VERSION ""

NS_ :

BS_:

BU_: VMCU TECU TACHO RECU_Virt IC3 HPCU EMS EBS DACU CIOM BBM ACM

BO_ 2675897016 TrailerDiagPhysRespMsg_F2_B8_BB1: 8 EBS
 SG_ TrailerDiagPhysResp_F2_B8_ISig_3 : 0|8@1- (1,0) [0|0] ""  VMCU

BO_ 2675897008 TrailerDiagPhysRespMsg_F2_B0_BB1: 8 EBS
 SG_ TrailerDiagPhysResp_F2_B0_ISig_3 : 0|8@1- (1,0) [0|0] ""  VMCU

BO_ 2675897000 TrailerDiagPhysRespMsg_F2_A8_BB1: 8 EBS
 SG_ TrailerDiagPhysResp_F2_A8_ISig_3 : 0|8@1- (1,0) [0|0] ""  VMCU

BO_ 2675886324 TrailerDiagPhysReqMsg_C8_F4_BB1: 8 IC3
 SG_ TrailerDiagPhysReq_C8_F4_ISig_3 : 0|8@1- (1,0) [0|0] ""  EBS

BO_ 2675886322 TrailerDiagPhysReqMsg_C8_F2_BB1: 8 VMCU
 SG_ TrailerDiagPhysReq_C8_F2_ISig_3 : 0|8@1- (1,0) [0|0] ""  EBS

BO_ 2675884276 TrailerDiagPhysReqMsg_C0_F4_BB1: 8 IC3
 SG_ TrailerDiagPhysReq_C0_F4_ISig_3 : 0|8@1- (1,0) [0|0] ""  EBS

BO_ 2675884274 TrailerDiagPhysReqMsg_C0_F2_BB1: 8 VMCU
 SG_ TrailerDiagPhysReq_C0_F2_ISig_3 : 0|8@1- (1,0) [0|0] ""  EBS

BO_ 2675882228 TrailerDiagPhysReqMsg_B8_F4_BB1: 8 IC3
 SG_ TrailerDiagPhysReq_B8_F4_ISig_3 : 0|8@1- (1,0) [0|0] ""  EBS

BO_ 2675882226 TrailerDiagPhysReqMsg_B8_F2_BB1: 8 VMCU
 SG_ TrailerDiagPhysReq_B8_F2_ISig_3 : 0|8@1- (1,0) [0|0] ""  EBS

BO_ 2675880180 TrailerDiagPhysReqMsg_B0_F4_BB1: 8 IC3
 SG_ TrailerDiagPhysReq_B0_F4_ISig_3 : 0|8@1- (1,0) [0|0] ""  EBS

BO_ 2675880178 TrailerDiagPhysReqMsg_B0_F2_BB1: 8 VMCU
 SG_ TrailerDiagPhysReq_B0_F2_ISig_3 : 0|8@1- (1,0) [0|0] ""  EBS

BO_ 2675878132 TrailerDiagPhysReqMsg_A8_F4_BB1: 8 IC3
 SG_ TrailerDiagPhysReq_A8_F4_ISig_3 : 0|8@1- (1,0) [0|0] ""  EBS

BO_ 2675878130 TrailerDiagPhysReqMsg_A8_F2_BB1: 8 VMCU
 SG_ TrailerDiagPhysReq_A8_F2_ISig_3 : 0|8@1- (1,0) [0|0] ""  EBS

BO_ 2675965940 TrailerDiagFuncMsgTGW_BB1: 8 IC3
 SG_ TrailerDiagFuncTGW2_ISig_3 : 0|64@1- (1,0) [0|0] ""  EBS

BO_ 2675965938 TrailerDiagFuncMsgExtTester_BB1: 8 VMCU
 SG_ TrailerDiagFuncExtTester_ISig_3 : 0|64@1- (1,0) [0|0] ""  EBS

BO_ 2671902706 TesterFuncDiagMsg_BB1: 8 VMCU
 SG_ FuncDiagDataTester_ISig_3 : 0|64@1+ (1,0) [0|0] ""  EBS,TACHO,ACM

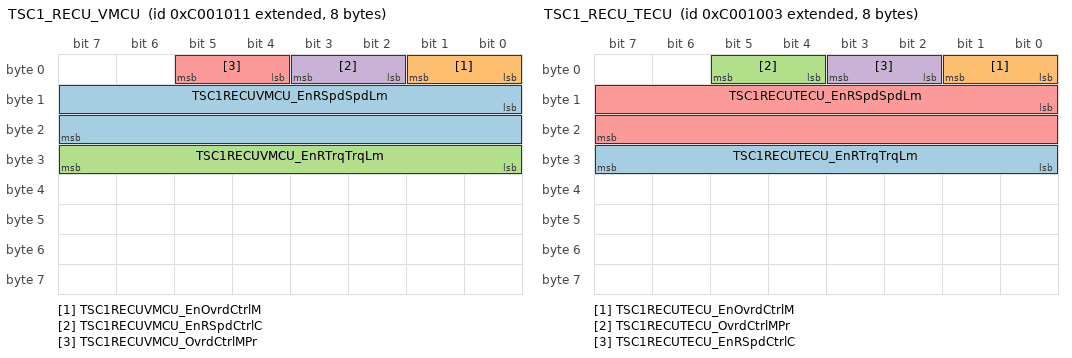
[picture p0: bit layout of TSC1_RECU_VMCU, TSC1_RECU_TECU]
BO_ 2348814353 TSC1_RECU_VMCU: 8 VMCU
 SG_ TSC1RECUVMCU_EnRSpdSpdLm : 8|16@1+ (0.125,0) [0|8191.875] "rpm"  RECU_Virt,EBS
 SG_ TSC1RECUVMCU_EnOvrdCtrlM : 0|2@1+ (1,0) [0|0] ""  EBS,RECU_Virt
 SG_ TSC1RECUVMCU_EnRTrqTrqLm : 24|8@1+ (1,-125) [-125|130] "Percent"  RECU_Virt,EBS
 SG_ TSC1RECUVMCU_EnRSpdCtrlC : 2|2@1+ (1,0) [0|0] ""  RECU_Virt,EBS
 SG_ TSC1RECUVMCU_OvrdCtrlMPr : 4|2@1+ (1,0) [0|0] ""  EBS,RECU_Virt

BO_ 2348814339 TSC1_RECU_TECU: 8 TECU
 SG_ TSC1RECUTECU_EnRTrqTrqLm : 24|8@1+ (1,-125) [-125|130] "Percent"  RECU_Virt
 SG_ TSC1RECUTECU_EnOvrdCtrlM : 0|2@1+ (1,0) [0|0] ""  RECU_Virt
 SG_ TSC1RECUTECU_OvrdCtrlMPr : 4|2@1+ (1,0) [0|0] ""  RECU_Virt
 SG_ TSC1RECUTECU_EnRSpdCtrlC : 2|2@1+ (1,0) [0|0] ""  RECU_Virt
 SG_ TSC1RECUTECU_EnRSpdSpdLm : 8|16@1+ (0.125,0) [0|8191.875] "rpm"  RECU_Virt

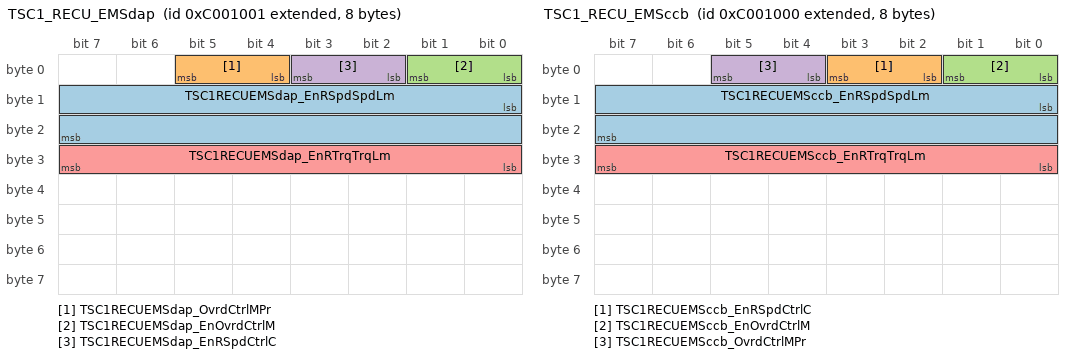
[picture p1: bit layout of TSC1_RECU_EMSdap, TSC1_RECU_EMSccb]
BO_ 2348814337 TSC1_RECU_EMSdap: 8 EMS
 SG_ TSC1RECUEMSdap_EnRSpdSpdLm : 8|16@1+ (0.125,0) [0|8191.875] "rpm"  RECU_Virt
 SG_ TSC1RECUEMSdap_OvrdCtrlMPr : 4|2@1+ (1,0) [0|0] ""  RECU_Virt
 SG_ TSC1RECUEMSdap_EnOvrdCtrlM : 0|2@1+ (1,0) [0|0] ""  RECU_Virt
 SG_ TSC1RECUEMSdap_EnRSpdCtrlC : 2|2@1+ (1,0) [0|0] ""  RECU_Virt
 SG_ TSC1RECUEMSdap_EnRTrqTrqLm : 24|8@1+ (1,-125) [-125|130] "Percent"  RECU_Virt

BO_ 2348814336 TSC1_RECU_EMSccb: 8 EMS
 SG_ TSC1RECUEMSccb_EnRSpdSpdLm : 8|16@1+ (0.125,0) [0|8191.875] "rpm"  RECU_Virt
 SG_ TSC1RECUEMSccb_EnRSpdCtrlC : 2|2@1+ (1,0) [0|0] ""  RECU_Virt
 SG_ TSC1RECUEMSccb_EnOvrdCtrlM : 0|2@1+ (1,0) [0|0] ""  RECU_Virt
 SG_ TSC1RECUEMSccb_OvrdCtrlMPr : 4|2@1+ (1,0) [0|0] ""  RECU_Virt
 SG_ TSC1RECUEMSccb_EnRTrqTrqLm : 24|8@1+ (1,-125) [-125|130] "Percent"  RECU_Virt

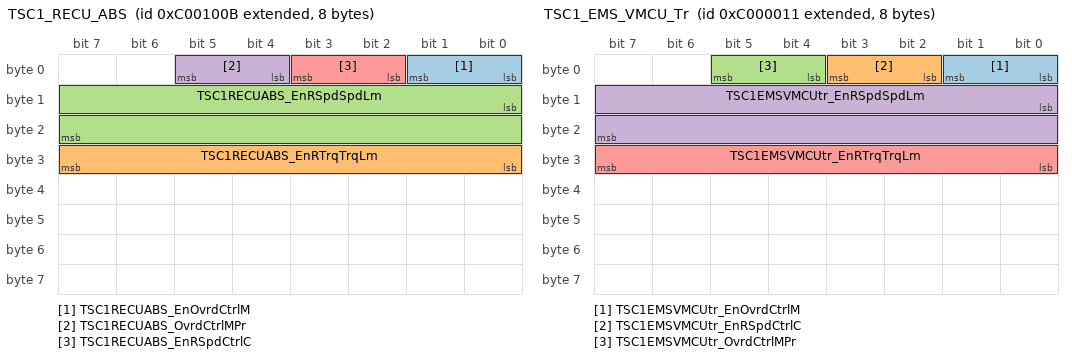
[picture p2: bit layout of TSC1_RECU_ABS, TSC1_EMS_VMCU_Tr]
BO_ 2348814347 TSC1_RECU_ABS: 8 EBS
 SG_ TSC1RECUABS_EnOvrdCtrlM : 0|2@1+ (1,0) [0|0] ""  RECU_Virt
 SG_ TSC1RECUABS_EnRTrqTrqLm : 24|8@1+ (1,-125) [-125|130] "Percent"  RECU_Virt
 SG_ TSC1RECUABS_EnRSpdSpdLm : 8|16@1+ (0.125,0) [0|8191.875] "rpm"  RECU_Virt
 SG_ TSC1RECUABS_OvrdCtrlMPr : 4|2@1+ (1,0) [0|0] ""  RECU_Virt
 SG_ TSC1RECUABS_EnRSpdCtrlC : 2|2@1+ (1,0) [0|0] ""  RECU_Virt

BO_ 2348810257 TSC1_EMS_VMCU_Tr: 8 VMCU
 SG_ TSC1EMSVMCUtr_EnOvrdCtrlM : 0|2@1+ (1,0) [0|0] ""  EMS
 SG_ TSC1EMSVMCUtr_EnRSpdCtrlC : 2|2@1+ (1,0) [0|0] ""  EMS
 SG_ TSC1EMSVMCUtr_OvrdCtrlMPr : 4|2@1+ (1,0) [0|0] ""  EMS
 SG_ TSC1EMSVMCUtr_EnRSpdSpdLm : 8|16@1+ (0.125,0) [0|8191.875] "rpm"  EMS
 SG_ TSC1EMSVMCUtr_EnRTrqTrqLm : 24|8@1+ (1,-125) [-125|130] "Percent"  EMS

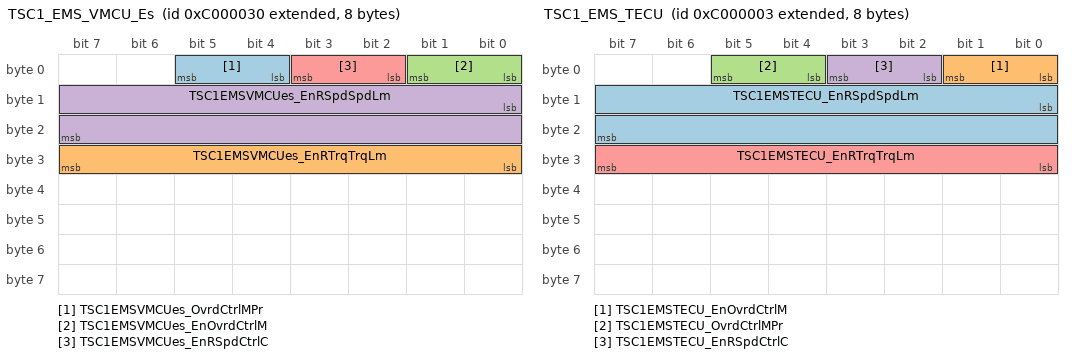
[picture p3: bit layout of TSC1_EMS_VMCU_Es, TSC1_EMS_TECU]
BO_ 2348810288 TSC1_EMS_VMCU_Es: 8 VMCU
 SG_ TSC1EMSVMCUes_OvrdCtrlMPr : 4|2@1+ (1,0) [0|0] ""  EMS,TECU
 SG_ TSC1EMSVMCUes_EnRTrqTrqLm : 24|8@1+ (1,-125) [-125|130] "Percent"  TECU,EMS
 SG_ TSC1EMSVMCUes_EnOvrdCtrlM : 0|2@1+ (1,0) [0|0] ""  TECU,EMS
 SG_ TSC1EMSVMCUes_EnRSpdSpdLm : 8|16@1+ (0.125,0) [0|8191.875] "rpm"  TECU,EMS
 SG_ TSC1EMSVMCUes_EnRSpdCtrlC : 2|2@1+ (1,0) [0|0] ""  EMS,TECU

BO_ 2348810243 TSC1_EMS_TECU: 8 TECU
 SG_ TSC1EMSTECU_EnRSpdSpdLm : 8|16@1+ (0.125,0) [0|8191.875] "rpm"  EMS
 SG_ TSC1EMSTECU_EnOvrdCtrlM : 0|2@1+ (1,0) [0|0] ""  EMS
 SG_ TSC1EMSTECU_OvrdCtrlMPr : 4|2@1+ (1,0) [0|0] ""  EMS
 SG_ TSC1EMSTECU_EnRSpdCtrlC : 2|2@1+ (1,0) [0|0] ""  EMS
 SG_ TSC1EMSTECU_EnRTrqTrqLm : 24|8@1+ (1,-125) [-125|130] "Percent"  EMS

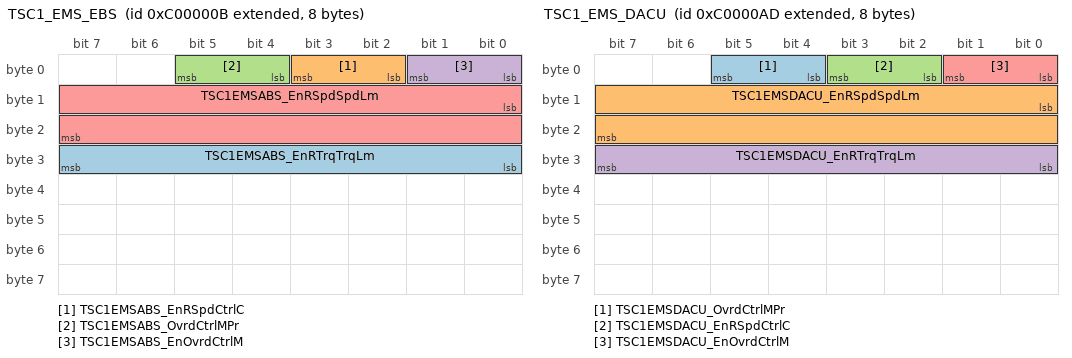
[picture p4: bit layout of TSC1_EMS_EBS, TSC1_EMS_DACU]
BO_ 2348810251 TSC1_EMS_EBS: 8 EBS
 SG_ TSC1EMSABS_EnRTrqTrqLm : 24|8@1+ (1,-125) [-125|130] "Percent"  EMS
 SG_ TSC1EMSABS_EnRSpdCtrlC : 2|2@1+ (1,0) [0|0] ""  EMS
 SG_ TSC1EMSABS_OvrdCtrlMPr : 4|2@1+ (1,0) [0|0] ""  EMS
 SG_ TSC1EMSABS_EnOvrdCtrlM : 0|2@1+ (1,0) [0|0] ""  EMS
 SG_ TSC1EMSABS_EnRSpdSpdLm : 8|16@1+ (0.125,0) [0|8191.875] "rpm"  EMS

BO_ 2348810413 TSC1_EMS_DACU: 8 DACU
 SG_ TSC1EMSDACU_OvrdCtrlMPr : 4|2@1+ (1,0) [0|0] ""  EMS
 SG_ TSC1EMSDACU_EnRSpdSpdLm : 8|16@1+ (0.125,0) [0|8191.875] "rpm"  EMS
 SG_ TSC1EMSDACU_EnRSpdCtrlC : 2|2@1+ (1,0) [0|0] ""  EMS
 SG_ TSC1EMSDACU_EnRTrqTrqLm : 24|8@1+ (1,-125) [-125|130] "Percent"  EMS
 SG_ TSC1EMSDACU_EnOvrdCtrlM : 0|2@1+ (1,0) [0|0] ""  EMS

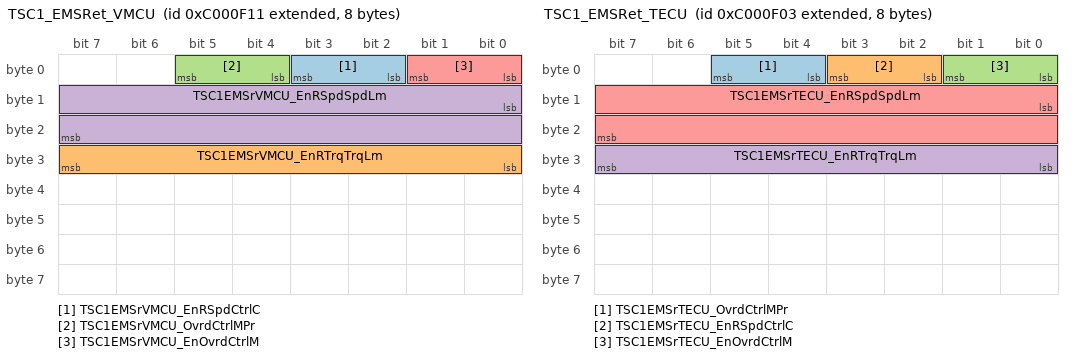
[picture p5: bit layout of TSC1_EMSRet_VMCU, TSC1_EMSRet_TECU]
BO_ 2348814097 TSC1_EMSRet_VMCU: 8 VMCU
 SG_ TSC1EMSrVMCU_EnRSpdCtrlC : 2|2@1+ (1,0) [0|0] ""  EBS,EMS
 SG_ TSC1EMSrVMCU_EnRTrqTrqLm : 24|8@1+ (1,-125) [-125|130] "Percent"  EMS,EBS
 SG_ TSC1EMSrVMCU_OvrdCtrlMPr : 4|2@1+ (1,0) [0|0] ""  EMS,EBS
 SG_ TSC1EMSrVMCU_EnRSpdSpdLm : 8|16@1+ (0.125,0) [0|8191.875] "rpm"  EBS,EMS
 SG_ TSC1EMSrVMCU_EnOvrdCtrlM : 0|2@1+ (1,0) [0|0] ""  EMS,EBS

BO_ 2348814083 TSC1_EMSRet_TECU: 8 TECU
 SG_ TSC1EMSrTECU_OvrdCtrlMPr : 4|2@1+ (1,0) [0|0] ""  EMS
 SG_ TSC1EMSrTECU_EnRSpdCtrlC : 2|2@1+ (1,0) [0|0] ""  EMS
 SG_ TSC1EMSrTECU_EnOvrdCtrlM : 0|2@1+ (1,0) [0|0] ""  EMS
 SG_ TSC1EMSrTECU_EnRTrqTrqLm : 24|8@1+ (1,-125) [-125|130] "Percent"  EMS
 SG_ TSC1EMSrTECU_EnRSpdSpdLm : 8|16@1+ (0.125,0) [0|8191.875] "rpm"  EMS

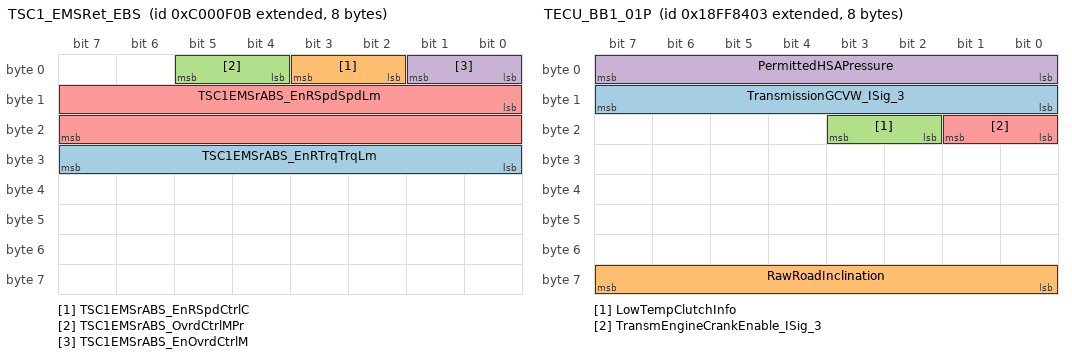
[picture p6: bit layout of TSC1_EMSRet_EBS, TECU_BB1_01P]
BO_ 2348814091 TSC1_EMSRet_EBS: 8 EBS
 SG_ TSC1EMSrABS_EnRTrqTrqLm : 24|8@1+ (1,-125) [-125|130] "Percent"  TECU,EMS
 SG_ TSC1EMSrABS_EnRSpdCtrlC : 2|2@1+ (1,0) [0|0] ""  TECU,EMS
 SG_ TSC1EMSrABS_OvrdCtrlMPr : 4|2@1+ (1,0) [0|0] ""  TECU,EMS
 SG_ TSC1EMSrABS_EnOvrdCtrlM : 0|2@1+ (1,0) [0|0] ""  TECU,EMS
 SG_ TSC1EMSrABS_EnRSpdSpdLm : 8|16@1+ (0.125,0) [0|8191.875] "rpm"  TECU,EMS

BO_ 2566755587 TRF2_X_TCU: 8 Vector__XXX

BO_ 2566846467 TRF1_X_TECU: 8 TECU
 SG_ TransmissionOilTemp_ISig_3 : 32|16@1+ (0.03125,-273) [-273|1774.96875] "DegreeC"  BBM,EMS,IC3
 SG_ TransmissionOilLevel : 8|8@1+ (0.4,0) [0|102] "Percent"  IC3

BO_ 2565603075 TPDT_X_TECU: 8 TECU
 SG_ TPDT_SeqNo_TECU : 0|8@1+ (1,0) [0|0] ""  IC3

BO_ 2565603310 TPDT_X_TACHO: 8 TACHO
 SG_ TPDT_SeqNo_TACHO : 0|8@1+ (1,0) [0|0] ""  IC3,VMCU,CIOM

BO_ 2565603088 TPDT_X_RECU: 8 RECU_Virt
 SG_ TPDT_SeqNo_RECU : 0|8@1+ (1,0) [0|0] ""  DACU,EMS,VMCU,TECU,EBS

BO_ 2565603077 TPDT_X_GSSA: 8 Vector__XXX

BO_ 2565603087 TPDT_X_EMSRet: 8 EMS
 SG_ TPDT_SeqNo_EMSRet : 0|8@1+ (1,0) [0|0] ""  TECU,RECU_Virt,DACU,EBS,IC3,VMCU

BO_ 2565603072 TPDT_X_EMS: 8 EMS
 SG_ TPDT_SeqNo_EMS : 0|8@1+ (1,0) [0|0] ""  TECU,DACU,IC3,VMCU,EBS,CIOM,RECU_Virt

BO_ 2565603083 TPDT_X_EBS: 8 EBS
 SG_ TPDT_SeqNo_EBS : 0|8@1+ (1,0) [0|0] ""  IC3,VMCU

BO_ 2565603133 TPDT_X_ACM: 8 ACM
 SG_ TPDT_SeqNo_ACM : 0|8@1+ (1,0) [0|0] ""  IC3

BO_ 2565598737 TPDT_TACHO_VMCU: 8 VMCU
 SG_ TPDT_SeqNo_TACHO_VMCU : 0|8@1+ (1,0) [0|0] ""  TACHO

BO_ 2565668611 TPCM_X_TECU: 8 TECU
 SG_ TPCM_ControlByte_TECU : 0|8@1+ (1,0) [0|0] ""  IC3

BO_ 2565668846 TPCM_X_TACHO: 8 TACHO
 SG_ TPCM_ControlByte_TACHO : 0|8@1+ (1,0) [0|0] ""  VMCU,CIOM,IC3

BO_ 2565668624 TPCM_X_RECU: 8 RECU_Virt
 SG_ TPCM_ControlByte_RECU : 0|8@1+ (1,0) [0|0] ""  TECU,EMS,VMCU,DACU,EBS

BO_ 2565668613 TPCM_X_GSSA: 8 Vector__XXX

BO_ 2565668623 TPCM_X_EMSRet: 8 EMS
 SG_ TPCM_ControlByte_EMSRet : 0|8@1+ (1,0) [0|0] ""  DACU,IC3,EBS,RECU_Virt,VMCU,TECU

BO_ 2565668608 TPCM_X_EMS: 8 EMS
 SG_ TPCM_ControlByte_EMS : 0|8@1+ (1,0) [0|0] ""  EBS,DACU,CIOM,RECU_Virt,TECU,VMCU,IC3

BO_ 2565668619 TPCM_X_EBS: 8 EBS
 SG_ TPCM_ControlByte_EBS : 0|8@1+ (1,0) [0|0] ""  IC3,VMCU

BO_ 2565668669 TPCM_X_ACM: 8 ACM
 SG_ TPCM_ControlByte_ACM : 0|8@1+ (1,0) [0|0] ""  IC3

BO_ 2565607918 TPCM_VMCU_TACHO: 8 TACHO
 SG_ TPCM_ControlByte_VMCU_TACHO : 0|8@1+ (1,0) [0|0] ""  VMCU

BO_ 2565664273 TPCM_TACHO_VMCU: 8 VMCU
 SG_ TPCM_ControlByte_TACHO_VMCU : 0|8@1+ (1,0) [0|0] ""  TACHO

BO_ 2633844483 TML_X_TCU: 8 Vector__XXX

BO_ 2566882307 TECU_BB1_01P: 8 TECU
 SG_ TransmissionGCVW_ISig_3 : 8|8@1+ (1000,0) [0|255000] "kg"  IC3,EMS,VMCU
 SG_ RawRoadInclination : 56|8@1+ (0.2,-25) [-25|26] "Percent"  VMCU
 SG_ LowTempClutchInfo : 18|2@1+ (1,0) [0|0] ""  IC3
 SG_ PermittedHSAPressure : 0|8@1+ (0.4,0) [0|102] "Percent"  EBS
 SG_ TransmEngineCrankEnable_ISig_3 : 16|2@1+ (1,0) [0|0] ""  VMCU

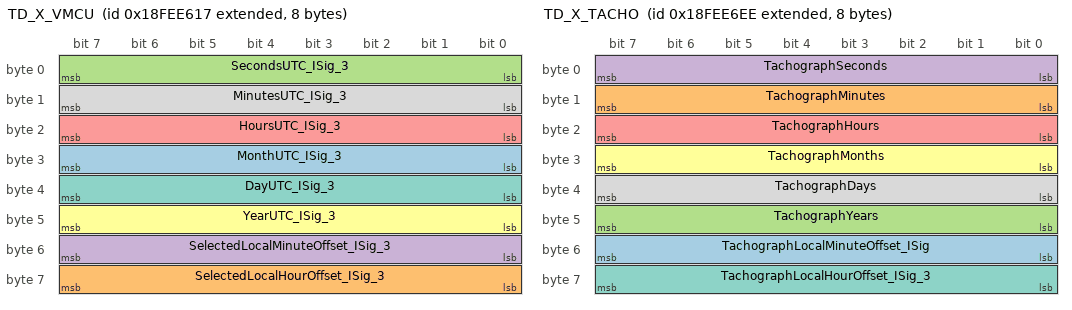
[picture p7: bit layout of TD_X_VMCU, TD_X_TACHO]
BO_ 2566841879 TD_X_VMCU: 8 VMCU
 SG_ MonthUTC_ISig_3 : 24|8@1+ (1,0) [0|255] "Months"  EBS,TECU,ACM,DACU,EMS,BBM,IC3,CIOM
 SG_ SelectedLocalHourOffset_ISig_3 : 56|8@1+ (1,-125) [-125|130] "h"  EBS,IC3
 SG_ SecondsUTC_ISig_3 : 0|8@1+ (0.25,0) [0|63.75] "s"  DACU,TECU,CIOM,IC3,ACM,BBM,EBS,EMS
 SG_ SelectedLocalMinuteOffset_ISig_3 : 48|8@1+ (1,-125) [-125|130] "min"  EBS,IC3
 SG_ HoursUTC_ISig_3 : 16|8@1+ (1,0) [0|255] "h"  EBS,DACU,ACM,BBM,IC3,TECU,CIOM,EMS
 SG_ YearUTC_ISig_3 : 40|8@1+ (1,1985) [1985|2240] "Years"  EBS,EMS,DACU,IC3,ACM,BBM,CIOM,TECU
 SG_ DayUTC_ISig_3 : 32|8@1+ (0.25,0) [0|63.75] "Days"  TECU,CIOM,IC3,EBS,EMS,DACU,ACM,BBM
 SG_ MinutesUTC_ISig_3 : 8|8@1+ (1,0) [0|255] "min"  DACU,TECU,CIOM,ACM,EMS,EBS,BBM,IC3

BO_ 2566842094 TD_X_TACHO: 8 TACHO
 SG_ TachographLocalMinuteOffset_ISig : 48|8@1+ (1,-125) [-125|130] "min"  VMCU,BBM
 SG_ TachographMinutes : 8|8@1+ (1,0) [0|255] "min"  VMCU
 SG_ TachographYears : 40|8@1+ (1,1985) [1985|2240] "Years"  VMCU
 SG_ TachographSeconds : 0|8@1+ (0.25,0) [0|63.75] "s"  VMCU
 SG_ TachographHours : 16|8@1+ (1,0) [0|255] "h"  VMCU
 SG_ TachographMonths : 24|8@1+ (1,0) [0|255] "Months"  VMCU
 SG_ TachographLocalHourOffset_ISig_3 : 56|8@1+ (1,-125) [-125|130] "h"  BBM,VMCU
 SG_ TachographDays : 32|8@1+ (0.25,0) [0|63.75] "Days"  VMCU

BO_ 2564156951 TDA_X_VMCU: 8 VMCU
 SG_ AdjustLocalMinuteOffset : 48|8@1+ (1,-125) [-125|130] "min"  TACHO
 SG_ AdjustLocalHourOffset : 56|8@1+ (1,-125) [-125|130] "h"  TACHO

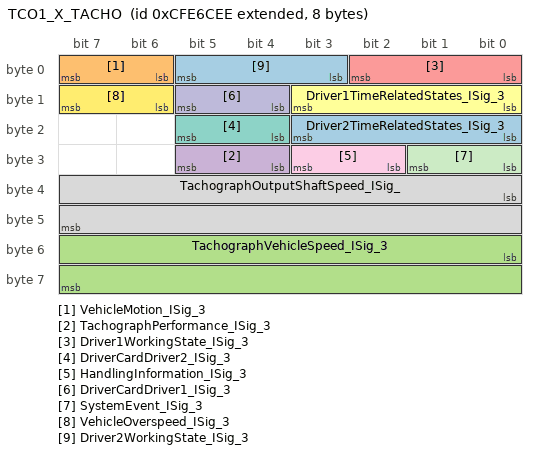
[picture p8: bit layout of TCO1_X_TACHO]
BO_ 2365484270 TCO1_X_TACHO: 8 TACHO
 SG_ Driver2TimeRelatedStates_ISig_3 : 16|4@1+ (1,0) [0|0] ""  BBM,CIOM,IC3
 SG_ VehicleMotion_ISig_3 : 6|2@1+ (1,0) [0|0] ""  IC3,CIOM,BBM
 SG_ TachographVehicleSpeed_ISig_3 : 48|16@1+ (0.00390625,0) [0|255.99609375] "Km_per_h"  CIOM,VMCU,BBM,IC3
 SG_ TachographPerformance_ISig_3 : 28|2@1+ (1,0) [0|0] ""  BBM,CIOM,IC3,VMCU
 SG_ Driver1WorkingState_ISig_3 : 0|3@1+ (1,0) [0|0] ""  BBM,IC3,CIOM
 SG_ Driver1TimeRelatedStates_ISig_3 : 8|4@1+ (1,0) [0|0] ""  CIOM,BBM,IC3
 SG_ DriverCardDriver2_ISig_3 : 20|2@1+ (1,0) [0|0] ""  CIOM,BBM,IC3
 SG_ TachographOutputShaftSpeed_ISig_ : 32|16@1+ (0.125,0) [0|8191.875] "rpm"  VMCU,BBM
 SG_ HandlingInformation_ISig_3 : 26|2@1+ (1,0) [0|0] ""  CIOM,VMCU,IC3,BBM
 SG_ DriverCardDriver1_ISig_3 : 12|2@1+ (1,0) [0|0] ""  CIOM,VMCU,IC3,BBM,DACU
 SG_ SystemEvent_ISig_3 : 24|2@1+ (1,0) [0|0] ""  IC3,BBM,VMCU,CIOM
 SG_ VehicleOverspeed_ISig_3 : 14|2@1+ (1,0) [0|0] ""  CIOM,BBM,IC3
 SG_ Driver2WorkingState_ISig_3 : 3|3@1+ (1,0) [0|0] ""  CIOM,BBM,IC3

BO_ 2566840835 TCFG_X_TCU: 8 Vector__XXX

BO_ 2348876549 TC1_TECU_GSSA: 8 Vector__XXX

BO_ 2566838787 SOFT_X_TCU: 8 Vector__XXX

BO_ 2566838789 SOFT_X_GSSA: 8 Vector__XXX

BO_ 2566862055 Reserved_VDC_BB1: 8 Vector__XXX

BO_ 2566862311 Reserved_CCU_BB1_04P: 8 Vector__XXX

BO_ 2566861799 Reserved_CCU_BB1_03P: 8 Vector__XXX

BO_ 2566861543 Reserved_CCU_BB1_02P: 8 Vector__XXX

BO_ 2566861287 Reserved_CCU_BB1_01P: 8 Vector__XXX

BO_ 2566862567 Reserved_BMS_BB1_01P: 8 Vector__XXX

BO_ 2565537539 RQST_X_TCU: 8 Vector__XXX

BO_ 2565533233 RQST_TACHO_CIOM: 3 CIOM
 SG_ PGNReq_Tacho_CIOM : 0|24@1+ (1,0) [0|16777215] ""  TACHO

BO_ 2565473539 RQST_GSSA_TCU: 8 Vector__XXX

BO_ 2631855639 RESET_TACHO_HMIIOM: 8 IC3

BO_ 2499792656 RECU_BB1_01P: 8 RECU_Virt
 SG_ DrivelineRetarderStat : 0|2@1+ (1,0) [0|0] ""  IC3

BO_ 2566840592 RC_X_RECU: 19 RECU_Virt
 SG_ DrivelineRetarderRefTorque : 128|16@1+ (1,0) [0|65535] "Nm"  EBS,VMCU,DACU,TECU,EMS
 SG_ DrivelineRetarderLocation : 4|4@1+ (1,0) [0|0] ""  EMS,DACU,EBS
 SG_ DrivelineRetarderType : 0|4@1+ (1,0) [0|0] ""  EBS

BO_ 2566840591 RC_X_EMSRet: 19 EMS
 SG_ EngRetConf_RetCtrlMethod : 8|8@1+ (1,0) [0|255] "Step"  TECU
 SG_ EngRetConf_RetSpeedAtP4 : 88|16@1+ (0.125,0) [0|8191.875] "rpm"  TECU
 SG_ EngRetConf_MaxRetSpeedP2 : 40|16@1+ (0.125,0) [0|8191.875] "rpm"  TECU
 SG_ EngRetConf_PerTrqAtP3 : 80|8@1+ (1,-125) [-125|130] "Percent"  TECU
 SG_ EngRetConf_RetSpeedAtP5 : 112|16@1+ (0.125,0) [0|8191.875] "rpm"  TECU
 SG_ EngRetConf_speedAtIdleP1 : 16|16@1+ (0.125,0) [0|8191.875] "rpm"  TECU
 SG_ EngRetConf_PerTrqAtP4 : 104|8@1+ (1,-125) [-125|130] "Percent"  TECU
 SG_ ReferenceEngineRetarderTorque : 128|16@1+ (1,0) [0|65535] "Nm"  VMCU,EBS,DACU,RECU_Virt,TECU
 SG_ EngRetConf_PerTrqAtIdleP1 : 32|8@1+ (1,-125) [-125|130] "Percent"  TECU
 SG_ EngRetConf_RetSpeedAtP3 : 64|16@1+ (0.125,0) [0|8191.875] "rpm"  TECU
 SG_ EngRetConf_PerTrqAtMaxSpeedP2 : 56|8@1+ (1,-125) [-125|130] "Percent"  TECU
 SG_ EngRetConf_PerTrqAtP5 : 144|8@1+ (1,-125) [-125|130] "Percent"  TECU

CM_ BO_ 2348814353 "PGN 0 Torque/Speed Control 1, From VMCU to RECU";
CM_ SG_ 2348814353 TSC1RECUVMCU_EnRSpdSpdLm "65024 - 65279 Error ; 65280 - 65535 Not available";
CM_ SG_ 2348814353 TSC1RECUVMCU_EnRTrqTrqLm "254 Error ; 255 Not available";
CM_ BO_ 2348814339 "PGN 0 Torque/Speed Control 1";
CM_ BO_ 2348814337 "PGN 0 Torque/Speed Control 1";
CM_ SG_ 2348814337 TSC1RECUEMSdap_EnRSpdSpdLm "65024 - 65279 Error ; 65280 - 65535 Not available";
CM_ SG_ 2348814337 TSC1RECUEMSdap_EnRTrqTrqLm "254 Error ; 255 Not available";
CM_ BO_ 2348814336 "PGN 0 Torque/Speed Control 1";
CM_ SG_ 2348814336 TSC1RECUEMSccb_EnRSpdSpdLm "65024 - 65279 Error ; 65280 - 65535 Not available";
CM_ SG_ 2348814336 TSC1RECUEMSccb_EnRTrqTrqLm "254 Error ; 255 Not available";
CM_ BO_ 2348814347 "PGN 0 Torque/Speed Control 1";
CM_ SG_ 2348814347 TSC1RECUABS_EnRTrqTrqLm "254 Error ; 255 Not available";
CM_ SG_ 2348814347 TSC1RECUABS_EnRSpdSpdLm "65024 - 65279 Error ; 65280 - 65535 Not available";
CM_ BO_ 2348810257 "PGN 0 Torque/Speed Control 1, Torque control, From VMCU to EMS";
CM_ SG_ 2348810257 TSC1EMSVMCUtr_EnRSpdSpdLm "65024 - 65279 Error ; 65280 - 65535 Not available";
CM_ SG_ 2348810257 TSC1EMSVMCUtr_EnRTrqTrqLm "254 Error ; 255 Not available";
CM_ BO_ 2348810288 "PGN 0 Torque/Speed Control 1, Engine speed control, From VMCU to EMS";
CM_ SG_ 2348810288 TSC1EMSVMCUes_EnRTrqTrqLm "254 Error ; 255 Not available";
CM_ SG_ 2348810288 TSC1EMSVMCUes_EnRSpdSpdLm "65024 - 65279 Error ; 65280 - 65535 Not available";
CM_ BO_ 2348810243 "PGN 0 Torque/Speed Control 1, From TECU to EMS";
CM_ SG_ 2348810243 TSC1EMSTECU_EnRSpdSpdLm "65024 - 65279 Error ; 65280 - 65535 Not available";
CM_ SG_ 2348810243 TSC1EMSTECU_EnRTrqTrqLm "254 Error ; 255 Not available";
CM_ BO_ 2348810251 "PGN 0 Torque/Speed Control 1, From EBS to EMS";
CM_ SG_ 2348810251 TSC1EMSABS_EnRTrqTrqLm "254 Error ; 255 Not available";
CM_ SG_ 2348810251 TSC1EMSABS_EnRSpdSpdLm "65024 - 65279 Error ; 65280 - 65535 Not available";
CM_ BO_ 2348810413 "PGN 0 Torque/Speed Control 1, From DACU to EMS";
CM_ SG_ 2348810413 TSC1EMSDACU_EnRSpdSpdLm "65024 - 65279 Error ; 65280 - 65535 Not available";
CM_ SG_ 2348810413 TSC1EMSDACU_EnRTrqTrqLm "254 Error ; 255 Not available";
CM_ BO_ 2348814097 "PGN 0 Torque/Speed Control 1, From VMCU to EMS Retarder";
CM_ SG_ 2348814097 TSC1EMSrVMCU_EnRTrqTrqLm "254 Error ; 255 Not available";
CM_ SG_ 2348814097 TSC1EMSrVMCU_EnRSpdSpdLm "65024 - 65279 Error ; 65280 - 65535 Not available";
CM_ BO_ 2348814083 "PGN 0 Torque/Speed Control 1, From TECU to EMS Retarder";
CM_ SG_ 2348814083 TSC1EMSrTECU_EnRTrqTrqLm "254 Error ; 255 Not available";
CM_ SG_ 2348814083 TSC1EMSrTECU_EnRSpdSpdLm "65024 - 65279 Error ; 65280 - 65535 Not available";
CM_ BO_ 2348814091 "PGN 0 Torque/Speed Control 1, From EBS to EMS Retarder";
CM_ SG_ 2348814091 TSC1EMSrABS_EnRTrqTrqLm "254 Error ; 255 Not available";
CM_ SG_ 2348814091 TSC1EMSrABS_EnRSpdSpdLm "65024 - 65279 Error ; 65280 - 65535 Not available";
CM_ BO_ 2566755587 "PGN 64917 Transmission Fluids 2";
CM_ BO_ 2566846467 "PGN 65272 Transmission Fluids 1";
CM_ SG_ 2566846467 TransmissionOilTemp_ISig_3 "65024 - 65279 Error ; 65280 - 65535 Not available";
CM_ BO_ 2565603075 "PGN 60160 Transport Protocol Data Transfer, From TECU";
CM_ BO_ 2565603310 "PGN 60160 Transport Protocol Data Transfer, From TACHO";
CM_ BO_ 2565603088 "PGN 60160 Transport Protocol Data Transfer, From RECU";
CM_ BO_ 2565603077 "PGN 60160 Transport Protocol Data Transfer";
CM_ BO_ 2565603087 "PGN 60160 Transport Protocol Data Transfer, From EMS Retarder";
CM_ BO_ 2565603072 "PGN 60160 Transport Protocol Data Transfer, From EMS";
CM_ BO_ 2565603083 "PGN 60160 Transport Protocol Data Transfer, From EBS";
CM_ BO_ 2565603133 "PGN 60160 Transport Protocol Data Transfer, From ACM";
CM_ BO_ 2565668611 "PGN 60416 Transport Protocol Connection Management, From TECU";
CM_ BO_ 2565668846 "PGN 60416 Transport Protocol Connection Management, From TACHO";
CM_ BO_ 2565668624 "PGN 60416 Transport Protocol Connection Management, From RECU";
CM_ BO_ 2565668613 "PGN 60416 Transport Protocol Connection Management";
CM_ BO_ 2565668623 "PGN 60416 Transport Protocol Connection Management, From EMS Retarder";
CM_ BO_ 2565668608 "PGN 60416 Transport Protocol Connection Management, From EMS";
CM_ BO_ 2565668619 "PGN 60416 Transport Protocol Connection Management, From EBS";
CM_ BO_ 2565668669 "PGN 60416 Transport Protocol Connection Management, From ACM";
CM_ BO_ 2633844483 "PGN64839 Transmission Mode Labels";
CM_ SG_ 2566882307 TransmissionGCVW_ISig_3 "254 Error ; 255 Not available";
CM_ SG_ 2566882307 PermittedHSAPressure "254 Error ; 255 Not available";
CM_ BO_ 2566841879 "PGN 65254 Time/Date, From HMIIOM";
CM_ SG_ 2566841879 MonthUTC_ISig_3 "254 Error ; 255 Not available";
CM_ SG_ 2566841879 SecondsUTC_ISig_3 "254 Error ; 255 Not available";
CM_ SG_ 2566841879 HoursUTC_ISig_3 "254 Error ; 255 Not available";
CM_ SG_ 2566841879 YearUTC_ISig_3 "254 Error ; 255 Not available";
CM_ SG_ 2566841879 DayUTC_ISig_3 "254 Error ; 255 Not available";
CM_ SG_ 2566841879 MinutesUTC_ISig_3 "254 Error ; 255 Not available";
CM_ BO_ 2566842094 "PGN 65254 Time/Date, From TACHO";
CM_ SG_ 2566842094 TachographLocalMinuteOffset_ISig "254 Error ; 255 Not available";
CM_ SG_ 2566842094 TachographMinutes "254 Error ; 255 Not available";
CM_ SG_ 2566842094 TachographYears "254 Error ; 255 Not available";
CM_ SG_ 2566842094 TachographSeconds "254 Error ; 255 Not available";
CM_ SG_ 2566842094 TachographHours "254 Error ; 255 Not available";
CM_ SG_ 2566842094 TachographMonths "254 Error ; 255 Not available";
CM_ SG_ 2566842094 TachographLocalHourOffset_ISig_3 "254 Error ; 255 Not available";
CM_ SG_ 2566842094 TachographDays "254 Error ; 255 Not available";
CM_ BO_ 2564156951 "PGN 54528 TimeDate Adjust";
CM_ SG_ 2564156951 AdjustLocalMinuteOffset "254 Error ; 255 Not available";
CM_ SG_ 2564156951 AdjustLocalHourOffset "254 Error ; 255 Not available";
CM_ BO_ 2365484270 "PGN 65132 Tachograph";
CM_ SG_ 2365484270 TachographVehicleSpeed_ISig_3 "65024 - 65279 Error ; 65280 - 65535 Not available";
CM_ SG_ 2365484270 TachographOutputShaftSpeed_ISig_ "65024 - 65279 Error ; 65280 - 65535 Not available";
CM_ BO_ 2566840835 "PGN 65250 Transmission Configuration";
CM_ BO_ 2348876549 "PGN 256 Transmission Control 1, Gearshift selector to Transmission.
Transmission rate: When active; 50 ms to transmission and axles";
CM_ BO_ 2566838787 "PGN 65242 Software Identification";
CM_ BO_ 2566838789 "PGN 65242 Software Identification";
CM_ BO_ 2566862055 "Reserved ID for EBMR tx100ms";
CM_ BO_ 2566862311 "Reserved ID for EBMR tx100ms";
CM_ BO_ 2566861799 "Reserved ID for EBMR tx100ms";
CM_ BO_ 2566861543 "Reserved ID for EBMR tx100ms";
CM_ BO_ 2566861287 "Reserved ID for EBMR tx250ms +100ms state change";
CM_ BO_ 2566862567 "Reserved ID for EBMR tx1000ms, Note SA may be modified";
CM_ BO_ 2565537539 "PGN59904 Request PGN Global sent by Transmission ECU";
CM_ BO_ 2565533233 "PGN 59904 Request PGN ";
CM_ BO_ 2565473539 "PGN59904 Request PGN to GearShiftSelector sent by Transmission ECU";
CM_ BO_ 2631855639 "PGN 56832 Reset, from HMIIOM to TACHO";
CM_ BO_ 2566840592 "PGN 65249 Retarder Configuration from RECU";
CM_ SG_ 2566840592 DrivelineRetarderRefTorque "65024 - 65279 Error ; 65280 - 65535 Not available";
CM_ BO_ 2566840591 "PGN 65249 Retarder Configuration from EMSRetarder";
CM_ SG_ 2566840591 EngRetConf_RetCtrlMethod "254 Error ; 255 Not available";
CM_ SG_ 2566840591 EngRetConf_RetSpeedAtP4 "65024 - 65279 Error ; 65280 - 65535 Not available";
CM_ SG_ 2566840591 EngRetConf_MaxRetSpeedP2 "65024 - 65279 Error ; 65280 - 65535 Not available";
CM_ SG_ 2566840591 EngRetConf_PerTrqAtP3 "254 Error ; 255 Not available";
CM_ SG_ 2566840591 EngRetConf_RetSpeedAtP5 "65024 - 65279 Error ; 65280 - 65535 Not available";
CM_ SG_ 2566840591 EngRetConf_speedAtIdleP1 "65024 - 65279 Error ; 65280 - 65535 Not available";
CM_ SG_ 2566840591 EngRetConf_PerTrqAtP4 "254 Error ; 255 Not available";
CM_ SG_ 2566840591 ReferenceEngineRetarderTorque "65024 - 65279 Error ; 65280 - 65535 Not available";
CM_ SG_ 2566840591 EngRetConf_PerTrqAtIdleP1 "254 Error ; 255 Not available";
CM_ SG_ 2566840591 EngRetConf_RetSpeedAtP3 "65024 - 65279 Error ; 65280 - 65535 Not available";
CM_ SG_ 2566840591 EngRetConf_PerTrqAtMaxSpeedP2 "254 Error ; 255 Not available";
CM_ SG_ 2566840591 EngRetConf_PerTrqAtP5 "254 Error ; 255 Not available";
BA_DEF_ BO_  "GenMsgStartDelayTime" INT 0 0;
BA_DEF_ BO_  "GenMsgDelayTime" INT 0 0;
BA_DEF_ BO_  "GenMsgNrOfRepetition" INT 0 0;
BA_DEF_ BO_  "GenMsgCycleTimeFast" INT 0 0;
BA_DEF_ BO_  "GenMsgCycleTime" INT 0 0;
BA_DEF_ BO_  "GenMsgSendType" ENUM  "Cyclic","NotUsed","NotUsed","NotUsed","NotUsed","NotUsed","NotUsed","IfActive","NoMsgSendType","NotUsed";
BA_DEF_ SG_  "GenSigStartValue" INT 0 0;
BA_DEF_ SG_  "GenSigCycleTimeActive" INT 0 0;
BA_DEF_ SG_  "GenSigCycleTime" INT 0 0;
BA_DEF_ SG_  "GenSigSendType" ENUM  "Cyclic","OnWrite","OnWriteWithRepetition","OnChange","OnChangeWithRepetition","IfActive","IfActiveWithRepetition","NoSigSendType","NotUsed","NotUsed","NotUsed","NotUsed","NotUsed";
BA_DEF_ BO_  "VFrameFormat" ENUM  "StandardCAN","ExtendedCAN","reserved","J1939PG","reserved","reserved","reserved","reserved","reserved","reserved","reserved","reserved","reserved","reserved","StandardCAN_FD","ExtendedCAN_FD";
BA_DEF_ BO_  "TpJ1939VarDlc" ENUM  "No","Yes";
BA_DEF_ SG_  "SigType" ENUM  "Default","Range","RangeSigned","ASCII","Discrete","Control","ReferencePGN","DTC","StringDelimiter","StringLength","StringLengthControl";
BA_DEF_ SG_  "SeToolVersion_SIGNAL" STRING ;
BA_DEF_ SG_  "SeToolUniqueID_SIGNAL" STRING ;
BA_DEF_ SG_  "SeToolOwnerSigGroup_SIGNAL" STRING ;
BA_DEF_ SG_  "SeToolOwnerSigGroupID_SIGNAL" STRING ;
BA_DEF_ SG_  "SeToolName_SIGNAL" STRING ;
BA_DEF_ SG_  "SeToolItemID_SIGNAL" STRING ;
BA_DEF_ SG_  "SeToolAncestorID_SIGNAL" STRING ;
BA_DEF_ SG_  "SPN" INT 0 524287;
BA_DEF_ SG_  "Platform_VMCU1_Sig" ENUM  "No","Yes";
BA_DEF_ SG_  "Platform_FactoryIf_Sig" ENUM  "No","Yes";
BA_DEF_ SG_  "NeedsUpdateBit" ENUM  "No","Yes";
BA_DEF_ SG_  "GenSigMaxLatency" INT 0 65535;
BA_DEF_ SG_  "GenSigILSupport" ENUM  "Yes","No";
BA_DEF_ BO_  "GenMsgILSupport" ENUM  "No","Yes";
BA_DEF_ BO_  "DiagUUDTResponse" ENUM  "No","Yes";
BA_DEF_ BO_  "DiagState" ENUM  "No","Yes";
BA_DEF_ BO_  "DiagResponse" ENUM  "No","Yes";
BA_DEF_ BO_  "DiagRequest" ENUM  "No","Yes";
BA_DEF_ BO_  "DiagConnection" HEX 0 65535;
BA_DEF_ BO_  "CanTpFcFrameId" HEX 0 2147483647;
BA_DEF_ BO_  "CanTpBs" INT 0 255;
BA_DEF_ SG_  "SystemSignalLongSymbol" STRING ;
BA_DEF_REL_ BU_SG_REL_  "GenSigTimeoutTime" INT 0 65535;
BA_DEF_REL_ BU_SG_REL_  "GenSigFirstTimeoutTime" INT 0 65535;
BA_DEF_DEF_  "GenMsgStartDelayTime" 0;
BA_DEF_DEF_  "GenMsgDelayTime" 0;
BA_DEF_DEF_  "GenMsgNrOfRepetition" 0;
BA_DEF_DEF_  "GenMsgCycleTimeFast" 0;
BA_DEF_DEF_  "GenMsgCycleTime" 0;
BA_DEF_DEF_  "GenMsgSendType" "Cyclic";
BA_DEF_DEF_  "GenSigStartValue" 0;
BA_DEF_DEF_  "GenSigCycleTimeActive" 0;
BA_DEF_DEF_  "GenSigCycleTime" 0;
BA_DEF_DEF_  "GenSigSendType" "Cyclic";
BA_DEF_DEF_  "VFrameFormat" "ExtendedCAN";
BA_DEF_DEF_  "TpJ1939VarDlc" "No";
BA_DEF_DEF_  "SigType" "Default";
BA_DEF_DEF_  "SeToolVersion_SIGNAL" "";
BA_DEF_DEF_  "SeToolUniqueID_SIGNAL" "";
BA_DEF_DEF_  "SeToolOwnerSigGroup_SIGNAL" "";
BA_DEF_DEF_  "SeToolOwnerSigGroupID_SIGNAL" "";
BA_DEF_DEF_  "SeToolName_SIGNAL" "";
BA_DEF_DEF_  "SeToolItemID_SIGNAL" "";
BA_DEF_DEF_  "SeToolAncestorID_SIGNAL" "";
BA_DEF_DEF_  "SPN" 0;
BA_DEF_DEF_  "Platform_VMCU1_Sig" "No";
BA_DEF_DEF_  "Platform_FactoryIf_Sig" "No";
BA_DEF_DEF_  "NeedsUpdateBit" "No";
BA_DEF_DEF_  "GenSigMaxLatency" 0;
BA_DEF_DEF_  "GenSigILSupport" "Yes";
BA_DEF_DEF_  "GenMsgILSupport" "Yes";
BA_DEF_DEF_  "DiagUUDTResponse" "No";
BA_DEF_DEF_  "DiagState" "No";
BA_DEF_DEF_  "DiagResponse" "No";
BA_DEF_DEF_  "DiagRequest" "No";
BA_DEF_DEF_  "DiagConnection" 0;
BA_DEF_DEF_  "CanTpFcFrameId" 2147483647;
BA_DEF_DEF_  "CanTpBs" 255;
BA_DEF_DEF_REL_ "GenSigTimeoutTime" 0;
BA_DEF_DEF_REL_ "GenSigFirstTimeoutTime" 0;
BA_DEF_DEF_  "SystemSignalLongSymbol" "";
BA_ "GenMsgILSupport" BO_ 2675897016 0;
BA_ "GenMsgSendType" BO_ 2675897016 8;
BA_ "VFrameFormat" BO_ 2675897016 3;
BA_ "GenMsgILSupport" BO_ 2675897008 0;
BA_ "GenMsgSendType" BO_ 2675897008 8;
BA_ "VFrameFormat" BO_ 2675897008 3;
BA_ "GenMsgILSupport" BO_ 2675897000 0;
BA_ "GenMsgSendType" BO_ 2675897000 8;
BA_ "VFrameFormat" BO_ 2675897000 3;
BA_ "GenMsgILSupport" BO_ 2675886324 0;
BA_ "GenMsgSendType" BO_ 2675886324 8;
BA_ "VFrameFormat" BO_ 2675886324 3;
BA_ "GenMsgILSupport" BO_ 2675886322 0;
BA_ "GenMsgSendType" BO_ 2675886322 8;
BA_ "VFrameFormat" BO_ 2675886322 3;
BA_ "GenMsgILSupport" BO_ 2675884276 0;
BA_ "GenMsgSendType" BO_ 2675884276 8;
BA_ "VFrameFormat" BO_ 2675884276 3;
BA_ "GenMsgILSupport" BO_ 2675884274 0;
BA_ "GenMsgSendType" BO_ 2675884274 8;
BA_ "VFrameFormat" BO_ 2675884274 3;
BA_ "GenMsgILSupport" BO_ 2675882228 0;
BA_ "GenMsgSendType" BO_ 2675882228 8;
BA_ "VFrameFormat" BO_ 2675882228 3;
BA_ "GenMsgILSupport" BO_ 2675882226 0;
BA_ "GenMsgSendType" BO_ 2675882226 8;
BA_ "VFrameFormat" BO_ 2675882226 3;
BA_ "GenMsgILSupport" BO_ 2675880180 0;
BA_ "GenMsgSendType" BO_ 2675880180 8;
BA_ "VFrameFormat" BO_ 2675880180 3;
BA_ "GenMsgILSupport" BO_ 2675880178 0;
BA_ "GenMsgSendType" BO_ 2675880178 8;
BA_ "VFrameFormat" BO_ 2675880178 3;
BA_ "GenMsgILSupport" BO_ 2675878132 0;
BA_ "GenMsgSendType" BO_ 2675878132 8;
BA_ "VFrameFormat" BO_ 2675878132 3;
BA_ "GenMsgILSupport" BO_ 2675878130 0;
BA_ "GenMsgSendType" BO_ 2675878130 8;
BA_ "VFrameFormat" BO_ 2675878130 3;
BA_ "GenMsgILSupport" BO_ 2675965940 0;
BA_ "GenMsgSendType" BO_ 2675965940 8;
BA_ "VFrameFormat" BO_ 2675965940 3;
BA_ "GenMsgILSupport" BO_ 2675965938 0;
BA_ "GenMsgSendType" BO_ 2675965938 8;
BA_ "VFrameFormat" BO_ 2675965938 3;
BA_ "DiagConnection" BO_ 2671902706 62190;
BA_ "DiagState" BO_ 2671902706 1;
BA_ "GenMsgILSupport" BO_ 2671902706 0;
BA_ "GenMsgSendType" BO_ 2671902706 8;
BA_ "VFrameFormat" BO_ 2671902706 3;
BA_ "GenMsgSendType" BO_ 2348814353 7;
BA_ "GenMsgCycleTimeFast" BO_ 2348814353 50;
BA_ "GenMsgNrOfRepetition" BO_ 2348814353 3;
BA_ "VFrameFormat" BO_ 2348814353 3;
BA_ "GenMsgSendType" BO_ 2348814339 7;
BA_ "GenMsgCycleTimeFast" BO_ 2348814339 50;
BA_ "GenMsgNrOfRepetition" BO_ 2348814339 3;
BA_ "VFrameFormat" BO_ 2348814339 3;
BA_ "GenMsgSendType" BO_ 2348814337 7;
BA_ "GenMsgCycleTimeFast" BO_ 2348814337 50;
BA_ "GenMsgNrOfRepetition" BO_ 2348814337 3;
BA_ "VFrameFormat" BO_ 2348814337 3;
BA_ "GenMsgSendType" BO_ 2348814336 7;
BA_ "GenMsgCycleTimeFast" BO_ 2348814336 50;
BA_ "GenMsgNrOfRepetition" BO_ 2348814336 3;
BA_ "VFrameFormat" BO_ 2348814336 3;
BA_ "GenMsgSendType" BO_ 2348814347 7;
BA_ "GenMsgCycleTimeFast" BO_ 2348814347 50;
BA_ "GenMsgNrOfRepetition" BO_ 2348814347 3;
BA_ "VFrameFormat" BO_ 2348814347 3;
BA_ "GenMsgSendType" BO_ 2348810257 7;
BA_ "GenMsgCycleTimeFast" BO_ 2348810257 20;
BA_ "GenMsgNrOfRepetition" BO_ 2348810257 3;
BA_ "VFrameFormat" BO_ 2348810257 3;
BA_ "GenMsgSendType" BO_ 2348810288 7;
BA_ "GenMsgCycleTimeFast" BO_ 2348810288 20;
BA_ "GenMsgNrOfRepetition" BO_ 2348810288 3;
BA_ "VFrameFormat" BO_ 2348810288 3;
BA_ "GenMsgSendType" BO_ 2348810243 7;
BA_ "GenMsgCycleTimeFast" BO_ 2348810243 10;
BA_ "GenMsgNrOfRepetition" BO_ 2348810243 3;
BA_ "VFrameFormat" BO_ 2348810243 3;
BA_ "GenMsgSendType" BO_ 2348810251 7;
BA_ "GenMsgCycleTimeFast" BO_ 2348810251 10;
BA_ "GenMsgNrOfRepetition" BO_ 2348810251 3;
BA_ "VFrameFormat" BO_ 2348810251 3;
BA_ "GenMsgSendType" BO_ 2348810413 7;
BA_ "GenMsgCycleTimeFast" BO_ 2348810413 20;
BA_ "GenMsgNrOfRepetition" BO_ 2348810413 3;
BA_ "VFrameFormat" BO_ 2348810413 3;
BA_ "GenMsgSendType" BO_ 2348814097 7;
BA_ "GenMsgCycleTimeFast" BO_ 2348814097 50;
BA_ "GenMsgNrOfRepetition" BO_ 2348814097 3;
BA_ "VFrameFormat" BO_ 2348814097 3;
BA_ "GenMsgSendType" BO_ 2348814083 7;
BA_ "GenMsgCycleTimeFast" BO_ 2348814083 50;
BA_ "GenMsgNrOfRepetition" BO_ 2348814083 3;
BA_ "VFrameFormat" BO_ 2348814083 3;
BA_ "GenMsgSendType" BO_ 2348814091 7;
BA_ "GenMsgCycleTimeFast" BO_ 2348814091 50;
BA_ "GenMsgNrOfRepetition" BO_ 2348814091 3;
BA_ "VFrameFormat" BO_ 2348814091 3;
BA_ "VFrameFormat" BO_ 2566755587 3;
BA_ "GenMsgCycleTime" BO_ 2566846467 1000;
BA_ "GenMsgStartDelayTime" BO_ 2566846467 125;
BA_ "VFrameFormat" BO_ 2566846467 3;
BA_ "GenMsgILSupport" BO_ 2565603075 0;
BA_ "GenMsgSendType" BO_ 2565603075 8;
BA_ "VFrameFormat" BO_ 2565603075 3;
BA_ "GenMsgILSupport" BO_ 2565603310 0;
BA_ "GenMsgSendType" BO_ 2565603310 8;
BA_ "VFrameFormat" BO_ 2565603310 3;
BA_ "GenMsgILSupport" BO_ 2565603088 0;
BA_ "GenMsgSendType" BO_ 2565603088 8;
BA_ "VFrameFormat" BO_ 2565603088 3;
BA_ "GenMsgILSupport" BO_ 2565603077 0;
BA_ "VFrameFormat" BO_ 2565603077 3;
BA_ "GenMsgILSupport" BO_ 2565603087 0;
BA_ "GenMsgSendType" BO_ 2565603087 8;
BA_ "VFrameFormat" BO_ 2565603087 3;
BA_ "GenMsgILSupport" BO_ 2565603072 0;
BA_ "GenMsgSendType" BO_ 2565603072 8;
BA_ "VFrameFormat" BO_ 2565603072 3;
BA_ "GenMsgILSupport" BO_ 2565603083 0;
BA_ "GenMsgSendType" BO_ 2565603083 8;
BA_ "VFrameFormat" BO_ 2565603083 3;
BA_ "GenMsgILSupport" BO_ 2565603133 0;
BA_ "GenMsgSendType" BO_ 2565603133 8;
BA_ "VFrameFormat" BO_ 2565603133 3;
BA_ "GenMsgILSupport" BO_ 2565598737 0;
BA_ "GenMsgSendType" BO_ 2565598737 8;
BA_ "VFrameFormat" BO_ 2565598737 3;
BA_ "GenMsgILSupport" BO_ 2565668611 0;
BA_ "GenMsgSendType" BO_ 2565668611 8;
BA_ "VFrameFormat" BO_ 2565668611 3;
BA_ "GenMsgILSupport" BO_ 2565668846 0;
BA_ "GenMsgSendType" BO_ 2565668846 8;
BA_ "VFrameFormat" BO_ 2565668846 3;
BA_ "GenMsgILSupport" BO_ 2565668624 0;
BA_ "GenMsgSendType" BO_ 2565668624 8;
BA_ "VFrameFormat" BO_ 2565668624 3;
BA_ "GenMsgILSupport" BO_ 2565668613 0;
BA_ "VFrameFormat" BO_ 2565668613 3;
BA_ "GenMsgILSupport" BO_ 2565668623 0;
BA_ "GenMsgSendType" BO_ 2565668623 8;
BA_ "VFrameFormat" BO_ 2565668623 3;
BA_ "GenMsgILSupport" BO_ 2565668608 0;
BA_ "GenMsgSendType" BO_ 2565668608 8;
BA_ "VFrameFormat" BO_ 2565668608 3;
BA_ "GenMsgILSupport" BO_ 2565668619 0;
BA_ "GenMsgSendType" BO_ 2565668619 8;
BA_ "VFrameFormat" BO_ 2565668619 3;
BA_ "GenMsgILSupport" BO_ 2565668669 0;
BA_ "GenMsgSendType" BO_ 2565668669 8;
BA_ "VFrameFormat" BO_ 2565668669 3;
BA_ "GenMsgILSupport" BO_ 2565607918 0;
BA_ "GenMsgSendType" BO_ 2565607918 8;
BA_ "VFrameFormat" BO_ 2565607918 3;
BA_ "GenMsgILSupport" BO_ 2565664273 0;
BA_ "GenMsgSendType" BO_ 2565664273 8;
BA_ "VFrameFormat" BO_ 2565664273 3;
BA_ "TpJ1939VarDlc" BO_ 2633844483 1;
BA_ "VFrameFormat" BO_ 2633844483 3;
BA_ "GenMsgCycleTime" BO_ 2566882307 95;
BA_ "GenMsgStartDelayTime" BO_ 2566882307 5;
BA_ "VFrameFormat" BO_ 2566882307 3;
BA_ "GenMsgCycleTime" BO_ 2566841879 250;
BA_ "GenMsgStartDelayTime" BO_ 2566841879 50;
BA_ "VFrameFormat" BO_ 2566841879 3;
BA_ "GenMsgCycleTime" BO_ 2566842094 1000;
BA_ "VFrameFormat" BO_ 2566842094 3;
BA_ "GenMsgSendType" BO_ 2564156951 8;
BA_ "GenMsgDelayTime" BO_ 2564156951 100;
BA_ "VFrameFormat" BO_ 2564156951 3;
BA_ "GenMsgCycleTime" BO_ 2365484270 20;
BA_ "VFrameFormat" BO_ 2365484270 3;
BA_ "TpJ1939VarDlc" BO_ 2566840835 1;
BA_ "VFrameFormat" BO_ 2566840835 3;
BA_ "VFrameFormat" BO_ 2348876549 3;
BA_ "TpJ1939VarDlc" BO_ 2566838787 1;
BA_ "VFrameFormat" BO_ 2566838787 3;
BA_ "TpJ1939VarDlc" BO_ 2566838789 1;
BA_ "VFrameFormat" BO_ 2566838789 3;
BA_ "VFrameFormat" BO_ 2566862055 3;
BA_ "VFrameFormat" BO_ 2566862311 3;
BA_ "VFrameFormat" BO_ 2566861799 3;
BA_ "VFrameFormat" BO_ 2566861543 3;
BA_ "VFrameFormat" BO_ 2566861287 3;
BA_ "VFrameFormat" BO_ 2566862567 3;
BA_ "VFrameFormat" BO_ 2565537539 3;
BA_ "GenMsgCycleTime" BO_ 2565533233 30000;
BA_ "GenMsgStartDelayTime" BO_ 2565533233 25;
BA_ "VFrameFormat" BO_ 2565533233 3;
BA_ "VFrameFormat" BO_ 2565473539 3;
BA_ "GenMsgSendType" BO_ 2631855639 8;
BA_ "GenMsgDelayTime" BO_ 2631855639 200;
BA_ "VFrameFormat" BO_ 2631855639 3;
BA_ "GenMsgCycleTime" BO_ 2499792656 150;
BA_ "GenMsgStartDelayTime" BO_ 2499792656 10;
BA_ "VFrameFormat" BO_ 2499792656 3;
BA_ "GenMsgCycleTime" BO_ 2566840592 5000;
BA_ "GenMsgDelayTime" BO_ 2566840592 350;
BA_ "GenMsgStartDelayTime" BO_ 2566840592 25;
BA_ "VFrameFormat" BO_ 2566840592 3;
BA_ "GenMsgCycleTime" BO_ 2566840591 5000;
BA_ "GenMsgDelayTime" BO_ 2566840591 350;
BA_ "GenMsgStartDelayTime" BO_ 2566840591 1555;
BA_ "VFrameFormat" BO_ 2566840591 3;
BA_ "GenSigSendType" SG_ 2675897016 TrailerDiagPhysResp_F2_B8_ISig_3 7;
BA_ "GenSigSendType" SG_ 2675897008 TrailerDiagPhysResp_F2_B0_ISig_3 7;
BA_ "GenSigSendType" SG_ 2675897000 TrailerDiagPhysResp_F2_A8_ISig_3 7;
BA_ "GenSigSendType" SG_ 2675886324 TrailerDiagPhysReq_C8_F4_ISig_3 7;
BA_ "GenSigSendType" SG_ 2675886322 TrailerDiagPhysReq_C8_F2_ISig_3 7;
BA_ "GenSigSendType" SG_ 2675884276 TrailerDiagPhysReq_C0_F4_ISig_3 7;
BA_ "GenSigSendType" SG_ 2675884274 TrailerDiagPhysReq_C0_F2_ISig_3 7;
BA_ "GenSigSendType" SG_ 2675882228 TrailerDiagPhysReq_B8_F4_ISig_3 7;
BA_ "GenSigSendType" SG_ 2675882226 TrailerDiagPhysReq_B8_F2_ISig_3 7;
BA_ "GenSigSendType" SG_ 2675880180 TrailerDiagPhysReq_B0_F4_ISig_3 7;
BA_ "GenSigSendType" SG_ 2675880178 TrailerDiagPhysReq_B0_F2_ISig_3 7;
BA_ "GenSigSendType" SG_ 2675878132 TrailerDiagPhysReq_A8_F4_ISig_3 7;
BA_ "GenSigSendType" SG_ 2675878130 TrailerDiagPhysReq_A8_F2_ISig_3 7;
BA_ "GenSigSendType" SG_ 2675965940 TrailerDiagFuncTGW2_ISig_3 7;
BA_ "GenSigSendType" SG_ 2675965938 TrailerDiagFuncExtTester_ISig_3 7;
BA_ "GenSigSendType" SG_ 2671902706 FuncDiagDataTester_ISig_3 7;
BA_ "Platform_VMCU1_Sig" SG_ 2671902706 FuncDiagDataTester_ISig_3 1;
BA_ "GenSigSendType" SG_ 2348814353 TSC1RECUVMCU_EnRSpdSpdLm 7;
BA_ "GenSigCycleTime" SG_ 2348814353 TSC1RECUVMCU_EnRSpdSpdLm 100;
BA_ "GenSigCycleTimeActive" SG_ 2348814353 TSC1RECUVMCU_EnRSpdSpdLm 100;
BA_ "GenSigStartValue" SG_ 2348814353 TSC1RECUVMCU_EnRSpdSpdLm 65535;
BA_ "Platform_VMCU1_Sig" SG_ 2348814353 TSC1RECUVMCU_EnRSpdSpdLm 1;
BA_ "SPN" SG_ 2348814353 TSC1RECUVMCU_EnRSpdSpdLm 898;
BA_ "GenSigSendType" SG_ 2348814353 TSC1RECUVMCU_EnOvrdCtrlM 6;
BA_ "Platform_VMCU1_Sig" SG_ 2348814353 TSC1RECUVMCU_EnOvrdCtrlM 1;
BA_ "SPN" SG_ 2348814353 TSC1RECUVMCU_EnOvrdCtrlM 695;
BA_ "GenSigSendType" SG_ 2348814353 TSC1RECUVMCU_EnRTrqTrqLm 7;
BA_ "GenSigCycleTime" SG_ 2348814353 TSC1RECUVMCU_EnRTrqTrqLm 100;
BA_ "GenSigCycleTimeActive" SG_ 2348814353 TSC1RECUVMCU_EnRTrqTrqLm 100;
BA_ "GenSigStartValue" SG_ 2348814353 TSC1RECUVMCU_EnRTrqTrqLm 255;
BA_ "Platform_VMCU1_Sig" SG_ 2348814353 TSC1RECUVMCU_EnRTrqTrqLm 1;
BA_ "SPN" SG_ 2348814353 TSC1RECUVMCU_EnRTrqTrqLm 518;
BA_ "GenSigSendType" SG_ 2348814353 TSC1RECUVMCU_EnRSpdCtrlC 7;
BA_ "GenSigCycleTime" SG_ 2348814353 TSC1RECUVMCU_EnRSpdCtrlC 100;
BA_ "GenSigCycleTimeActive" SG_ 2348814353 TSC1RECUVMCU_EnRSpdCtrlC 100;
BA_ "Platform_VMCU1_Sig" SG_ 2348814353 TSC1RECUVMCU_EnRSpdCtrlC 1;
BA_ "SPN" SG_ 2348814353 TSC1RECUVMCU_EnRSpdCtrlC 696;
BA_ "GenSigSendType" SG_ 2348814353 TSC1RECUVMCU_OvrdCtrlMPr 7;
BA_ "GenSigCycleTime" SG_ 2348814353 TSC1RECUVMCU_OvrdCtrlMPr 100;
BA_ "GenSigCycleTimeActive" SG_ 2348814353 TSC1RECUVMCU_OvrdCtrlMPr 100;
BA_ "GenSigStartValue" SG_ 2348814353 TSC1RECUVMCU_OvrdCtrlMPr 3;
BA_ "Platform_VMCU1_Sig" SG_ 2348814353 TSC1RECUVMCU_OvrdCtrlMPr 1;
BA_ "SPN" SG_ 2348814353 TSC1RECUVMCU_OvrdCtrlMPr 897;
BA_ "GenSigSendType" SG_ 2348814339 TSC1RECUTECU_EnRTrqTrqLm 7;
BA_ "GenSigStartValue" SG_ 2348814339 TSC1RECUTECU_EnRTrqTrqLm 255;
BA_ "Platform_VMCU1_Sig" SG_ 2348814339 TSC1RECUTECU_EnRTrqTrqLm 1;
BA_ "SPN" SG_ 2348814339 TSC1RECUTECU_EnRTrqTrqLm 518;
BA_ "GenSigSendType" SG_ 2348814339 TSC1RECUTECU_EnOvrdCtrlM 6;
BA_ "Platform_VMCU1_Sig" SG_ 2348814339 TSC1RECUTECU_EnOvrdCtrlM 1;
BA_ "SPN" SG_ 2348814339 TSC1RECUTECU_EnOvrdCtrlM 695;
BA_ "GenSigSendType" SG_ 2348814339 TSC1RECUTECU_OvrdCtrlMPr 7;
BA_ "GenSigStartValue" SG_ 2348814339 TSC1RECUTECU_OvrdCtrlMPr 3;
BA_ "Platform_VMCU1_Sig" SG_ 2348814339 TSC1RECUTECU_OvrdCtrlMPr 1;
BA_ "SPN" SG_ 2348814339 TSC1RECUTECU_OvrdCtrlMPr 897;
BA_ "GenSigSendType" SG_ 2348814339 TSC1RECUTECU_EnRSpdCtrlC 7;
BA_ "Platform_VMCU1_Sig" SG_ 2348814339 TSC1RECUTECU_EnRSpdCtrlC 1;
BA_ "SPN" SG_ 2348814339 TSC1RECUTECU_EnRSpdCtrlC 696;
BA_ "GenSigSendType" SG_ 2348814339 TSC1RECUTECU_EnRSpdSpdLm 7;
BA_ "GenSigStartValue" SG_ 2348814339 TSC1RECUTECU_EnRSpdSpdLm 65535;
BA_ "Platform_VMCU1_Sig" SG_ 2348814339 TSC1RECUTECU_EnRSpdSpdLm 1;
BA_ "SPN" SG_ 2348814339 TSC1RECUTECU_EnRSpdSpdLm 898;
BA_ "GenSigSendType" SG_ 2348814337 TSC1RECUEMSdap_EnRSpdSpdLm 7;
BA_ "GenSigCycleTime" SG_ 2348814337 TSC1RECUEMSdap_EnRSpdSpdLm 100;
BA_ "GenSigCycleTimeActive" SG_ 2348814337 TSC1RECUEMSdap_EnRSpdSpdLm 100;
BA_ "GenSigStartValue" SG_ 2348814337 TSC1RECUEMSdap_EnRSpdSpdLm 65535;
BA_ "Platform_VMCU1_Sig" SG_ 2348814337 TSC1RECUEMSdap_EnRSpdSpdLm 1;
BA_ "SPN" SG_ 2348814337 TSC1RECUEMSdap_EnRSpdSpdLm 898;
BA_ "GenSigSendType" SG_ 2348814337 TSC1RECUEMSdap_OvrdCtrlMPr 7;
BA_ "GenSigCycleTime" SG_ 2348814337 TSC1RECUEMSdap_OvrdCtrlMPr 100;
BA_ "GenSigCycleTimeActive" SG_ 2348814337 TSC1RECUEMSdap_OvrdCtrlMPr 100;
BA_ "GenSigStartValue" SG_ 2348814337 TSC1RECUEMSdap_OvrdCtrlMPr 3;
BA_ "Platform_VMCU1_Sig" SG_ 2348814337 TSC1RECUEMSdap_OvrdCtrlMPr 1;
BA_ "SPN" SG_ 2348814337 TSC1RECUEMSdap_OvrdCtrlMPr 897;
BA_ "GenSigSendType" SG_ 2348814337 TSC1RECUEMSdap_EnOvrdCtrlM 6;
BA_ "Platform_VMCU1_Sig" SG_ 2348814337 TSC1RECUEMSdap_EnOvrdCtrlM 1;
BA_ "SPN" SG_ 2348814337 TSC1RECUEMSdap_EnOvrdCtrlM 695;
BA_ "GenSigSendType" SG_ 2348814337 TSC1RECUEMSdap_EnRSpdCtrlC 7;
BA_ "GenSigCycleTime" SG_ 2348814337 TSC1RECUEMSdap_EnRSpdCtrlC 100;
BA_ "GenSigCycleTimeActive" SG_ 2348814337 TSC1RECUEMSdap_EnRSpdCtrlC 100;
BA_ "Platform_VMCU1_Sig" SG_ 2348814337 TSC1RECUEMSdap_EnRSpdCtrlC 1;
BA_ "SPN" SG_ 2348814337 TSC1RECUEMSdap_EnRSpdCtrlC 696;
BA_ "GenSigSendType" SG_ 2348814337 TSC1RECUEMSdap_EnRTrqTrqLm 7;
BA_ "GenSigCycleTime" SG_ 2348814337 TSC1RECUEMSdap_EnRTrqTrqLm 100;
BA_ "GenSigCycleTimeActive" SG_ 2348814337 TSC1RECUEMSdap_EnRTrqTrqLm 100;
BA_ "GenSigStartValue" SG_ 2348814337 TSC1RECUEMSdap_EnRTrqTrqLm 255;
BA_ "Platform_VMCU1_Sig" SG_ 2348814337 TSC1RECUEMSdap_EnRTrqTrqLm 1;
BA_ "SPN" SG_ 2348814337 TSC1RECUEMSdap_EnRTrqTrqLm 518;
BA_ "GenSigSendType" SG_ 2348814336 TSC1RECUEMSccb_EnRSpdSpdLm 7;
BA_ "GenSigCycleTime" SG_ 2348814336 TSC1RECUEMSccb_EnRSpdSpdLm 100;
BA_ "GenSigCycleTimeActive" SG_ 2348814336 TSC1RECUEMSccb_EnRSpdSpdLm 100;
BA_ "GenSigStartValue" SG_ 2348814336 TSC1RECUEMSccb_EnRSpdSpdLm 65535;
BA_ "Platform_VMCU1_Sig" SG_ 2348814336 TSC1RECUEMSccb_EnRSpdSpdLm 1;
BA_ "SPN" SG_ 2348814336 TSC1RECUEMSccb_EnRSpdSpdLm 898;
BA_ "GenSigSendType" SG_ 2348814336 TSC1RECUEMSccb_EnRSpdCtrlC 7;
BA_ "GenSigCycleTime" SG_ 2348814336 TSC1RECUEMSccb_EnRSpdCtrlC 100;
BA_ "GenSigCycleTimeActive" SG_ 2348814336 TSC1RECUEMSccb_EnRSpdCtrlC 100;
BA_ "Platform_VMCU1_Sig" SG_ 2348814336 TSC1RECUEMSccb_EnRSpdCtrlC 1;
BA_ "SPN" SG_ 2348814336 TSC1RECUEMSccb_EnRSpdCtrlC 696;
BA_ "GenSigSendType" SG_ 2348814336 TSC1RECUEMSccb_EnOvrdCtrlM 6;
BA_ "Platform_VMCU1_Sig" SG_ 2348814336 TSC1RECUEMSccb_EnOvrdCtrlM 1;
BA_ "SPN" SG_ 2348814336 TSC1RECUEMSccb_EnOvrdCtrlM 695;
BA_ "GenSigSendType" SG_ 2348814336 TSC1RECUEMSccb_OvrdCtrlMPr 7;
BA_ "GenSigCycleTime" SG_ 2348814336 TSC1RECUEMSccb_OvrdCtrlMPr 100;
BA_ "GenSigCycleTimeActive" SG_ 2348814336 TSC1RECUEMSccb_OvrdCtrlMPr 100;
BA_ "GenSigStartValue" SG_ 2348814336 TSC1RECUEMSccb_OvrdCtrlMPr 3;
BA_ "Platform_VMCU1_Sig" SG_ 2348814336 TSC1RECUEMSccb_OvrdCtrlMPr 1;
BA_ "SPN" SG_ 2348814336 TSC1RECUEMSccb_OvrdCtrlMPr 897;
BA_ "GenSigSendType" SG_ 2348814336 TSC1RECUEMSccb_EnRTrqTrqLm 7;
BA_ "GenSigCycleTime" SG_ 2348814336 TSC1RECUEMSccb_EnRTrqTrqLm 100;
BA_ "GenSigCycleTimeActive" SG_ 2348814336 TSC1RECUEMSccb_EnRTrqTrqLm 100;
BA_ "GenSigStartValue" SG_ 2348814336 TSC1RECUEMSccb_EnRTrqTrqLm 255;
BA_ "Platform_VMCU1_Sig" SG_ 2348814336 TSC1RECUEMSccb_EnRTrqTrqLm 1;
BA_ "SPN" SG_ 2348814336 TSC1RECUEMSccb_EnRTrqTrqLm 518;
BA_ "GenSigSendType" SG_ 2348814347 TSC1RECUABS_EnOvrdCtrlM 6;
BA_ "Platform_VMCU1_Sig" SG_ 2348814347 TSC1RECUABS_EnOvrdCtrlM 1;
BA_ "SPN" SG_ 2348814347 TSC1RECUABS_EnOvrdCtrlM 695;
BA_ "GenSigSendType" SG_ 2348814347 TSC1RECUABS_EnRTrqTrqLm 7;
BA_ "GenSigCycleTime" SG_ 2348814347 TSC1RECUABS_EnRTrqTrqLm 100;
BA_ "GenSigCycleTimeActive" SG_ 2348814347 TSC1RECUABS_EnRTrqTrqLm 100;
BA_ "GenSigStartValue" SG_ 2348814347 TSC1RECUABS_EnRTrqTrqLm 255;
BA_ "Platform_VMCU1_Sig" SG_ 2348814347 TSC1RECUABS_EnRTrqTrqLm 1;
BA_ "SPN" SG_ 2348814347 TSC1RECUABS_EnRTrqTrqLm 518;
BA_ "GenSigSendType" SG_ 2348814347 TSC1RECUABS_EnRSpdSpdLm 7;
BA_ "GenSigCycleTime" SG_ 2348814347 TSC1RECUABS_EnRSpdSpdLm 100;
BA_ "GenSigCycleTimeActive" SG_ 2348814347 TSC1RECUABS_EnRSpdSpdLm 100;
BA_ "GenSigStartValue" SG_ 2348814347 TSC1RECUABS_EnRSpdSpdLm 65535;
BA_ "Platform_VMCU1_Sig" SG_ 2348814347 TSC1RECUABS_EnRSpdSpdLm 1;
BA_ "SPN" SG_ 2348814347 TSC1RECUABS_EnRSpdSpdLm 898;
BA_ "GenSigSendType" SG_ 2348814347 TSC1RECUABS_OvrdCtrlMPr 7;
BA_ "GenSigCycleTime" SG_ 2348814347 TSC1RECUABS_OvrdCtrlMPr 100;
BA_ "GenSigCycleTimeActive" SG_ 2348814347 TSC1RECUABS_OvrdCtrlMPr 100;
BA_ "GenSigStartValue" SG_ 2348814347 TSC1RECUABS_OvrdCtrlMPr 3;
BA_ "Platform_VMCU1_Sig" SG_ 2348814347 TSC1RECUABS_OvrdCtrlMPr 1;
BA_ "SPN" SG_ 2348814347 TSC1RECUABS_OvrdCtrlMPr 897;
BA_ "GenSigSendType" SG_ 2348814347 TSC1RECUABS_EnRSpdCtrlC 7;
BA_ "GenSigCycleTime" SG_ 2348814347 TSC1RECUABS_EnRSpdCtrlC 100;
BA_ "GenSigCycleTimeActive" SG_ 2348814347 TSC1RECUABS_EnRSpdCtrlC 100;
BA_ "Platform_VMCU1_Sig" SG_ 2348814347 TSC1RECUABS_EnRSpdCtrlC 1;
BA_ "SPN" SG_ 2348814347 TSC1RECUABS_EnRSpdCtrlC 696;
BA_ "GenSigSendType" SG_ 2348810257 TSC1EMSVMCUtr_EnOvrdCtrlM 6;
BA_ "Platform_VMCU1_Sig" SG_ 2348810257 TSC1EMSVMCUtr_EnOvrdCtrlM 1;
BA_ "SPN" SG_ 2348810257 TSC1EMSVMCUtr_EnOvrdCtrlM 695;
BA_ "SeToolAncestorID_SIGNAL" SG_ 2348810257 TSC1EMSVMCUtr_EnOvrdCtrlM "x0000001D042564C7";
BA_ "SeToolItemID_SIGNAL" SG_ 2348810257 TSC1EMSVMCUtr_EnOvrdCtrlM "x0000001D042564C7";
BA_ "SeToolName_SIGNAL" SG_ 2348810257 TSC1EMSVMCUtr_EnOvrdCtrlM "EnOvrdCtrlM";
BA_ "SeToolOwnerSigGroupID_SIGNAL" SG_ 2348810257 TSC1EMSVMCUtr_EnOvrdCtrlM "x0000001D043FB710";
BA_ "SeToolOwnerSigGroup_SIGNAL" SG_ 2348810257 TSC1EMSVMCUtr_EnOvrdCtrlM "TSC1EMSVMCUtr";
BA_ "SeToolVersion_SIGNAL" SG_ 2348810257 TSC1EMSVMCUtr_EnOvrdCtrlM "1";
BA_ "GenSigSendType" SG_ 2348810257 TSC1EMSVMCUtr_EnRSpdCtrlC 7;
BA_ "GenSigCycleTime" SG_ 2348810257 TSC1EMSVMCUtr_EnRSpdCtrlC 100;
BA_ "GenSigCycleTimeActive" SG_ 2348810257 TSC1EMSVMCUtr_EnRSpdCtrlC 100;
BA_ "Platform_VMCU1_Sig" SG_ 2348810257 TSC1EMSVMCUtr_EnRSpdCtrlC 1;
BA_ "SPN" SG_ 2348810257 TSC1EMSVMCUtr_EnRSpdCtrlC 696;
BA_ "SeToolAncestorID_SIGNAL" SG_ 2348810257 TSC1EMSVMCUtr_EnRSpdCtrlC "x0000001D042564C9";
BA_ "SeToolItemID_SIGNAL" SG_ 2348810257 TSC1EMSVMCUtr_EnRSpdCtrlC "x0000001D042564C9";
BA_ "SeToolName_SIGNAL" SG_ 2348810257 TSC1EMSVMCUtr_EnRSpdCtrlC "EnRSpdCtrlC";
BA_ "SeToolOwnerSigGroupID_SIGNAL" SG_ 2348810257 TSC1EMSVMCUtr_EnRSpdCtrlC "x0000001D043FB710";
BA_ "SeToolOwnerSigGroup_SIGNAL" SG_ 2348810257 TSC1EMSVMCUtr_EnRSpdCtrlC "TSC1EMSVMCUtr";
BA_ "SeToolVersion_SIGNAL" SG_ 2348810257 TSC1EMSVMCUtr_EnRSpdCtrlC "1";
BA_ "GenSigSendType" SG_ 2348810257 TSC1EMSVMCUtr_OvrdCtrlMPr 7;
BA_ "GenSigCycleTime" SG_ 2348810257 TSC1EMSVMCUtr_OvrdCtrlMPr 100;
BA_ "GenSigCycleTimeActive" SG_ 2348810257 TSC1EMSVMCUtr_OvrdCtrlMPr 100;
BA_ "GenSigStartValue" SG_ 2348810257 TSC1EMSVMCUtr_OvrdCtrlMPr 3;
BA_ "Platform_VMCU1_Sig" SG_ 2348810257 TSC1EMSVMCUtr_OvrdCtrlMPr 1;
BA_ "SPN" SG_ 2348810257 TSC1EMSVMCUtr_OvrdCtrlMPr 897;
BA_ "SeToolAncestorID_SIGNAL" SG_ 2348810257 TSC1EMSVMCUtr_OvrdCtrlMPr "x0000001D042564CE";
BA_ "SeToolItemID_SIGNAL" SG_ 2348810257 TSC1EMSVMCUtr_OvrdCtrlMPr "x0000001D042564CE";
BA_ "SeToolName_SIGNAL" SG_ 2348810257 TSC1EMSVMCUtr_OvrdCtrlMPr "OvrdCtrlMPr";
BA_ "SeToolOwnerSigGroupID_SIGNAL" SG_ 2348810257 TSC1EMSVMCUtr_OvrdCtrlMPr "x0000001D043FB710";
BA_ "SeToolOwnerSigGroup_SIGNAL" SG_ 2348810257 TSC1EMSVMCUtr_OvrdCtrlMPr "TSC1EMSVMCUtr";
BA_ "SeToolVersion_SIGNAL" SG_ 2348810257 TSC1EMSVMCUtr_OvrdCtrlMPr "1";
BA_ "GenSigSendType" SG_ 2348810257 TSC1EMSVMCUtr_EnRSpdSpdLm 7;
BA_ "GenSigCycleTime" SG_ 2348810257 TSC1EMSVMCUtr_EnRSpdSpdLm 100;
BA_ "GenSigCycleTimeActive" SG_ 2348810257 TSC1EMSVMCUtr_EnRSpdSpdLm 100;
BA_ "GenSigStartValue" SG_ 2348810257 TSC1EMSVMCUtr_EnRSpdSpdLm 65535;
BA_ "Platform_VMCU1_Sig" SG_ 2348810257 TSC1EMSVMCUtr_EnRSpdSpdLm 1;
BA_ "SPN" SG_ 2348810257 TSC1EMSVMCUtr_EnRSpdSpdLm 898;
BA_ "SeToolAncestorID_SIGNAL" SG_ 2348810257 TSC1EMSVMCUtr_EnRSpdSpdLm "x0000001D042564D1";
BA_ "SeToolItemID_SIGNAL" SG_ 2348810257 TSC1EMSVMCUtr_EnRSpdSpdLm "x0000001D042564D1";
BA_ "SeToolName_SIGNAL" SG_ 2348810257 TSC1EMSVMCUtr_EnRSpdSpdLm "EnRSpdSpdLm";
BA_ "SeToolOwnerSigGroupID_SIGNAL" SG_ 2348810257 TSC1EMSVMCUtr_EnRSpdSpdLm "x0000001D043FB710";
BA_ "SeToolOwnerSigGroup_SIGNAL" SG_ 2348810257 TSC1EMSVMCUtr_EnRSpdSpdLm "TSC1EMSVMCUtr";
BA_ "SeToolVersion_SIGNAL" SG_ 2348810257 TSC1EMSVMCUtr_EnRSpdSpdLm "1";
BA_ "GenSigSendType" SG_ 2348810257 TSC1EMSVMCUtr_EnRTrqTrqLm 7;
BA_ "GenSigCycleTime" SG_ 2348810257 TSC1EMSVMCUtr_EnRTrqTrqLm 100;
BA_ "GenSigCycleTimeActive" SG_ 2348810257 TSC1EMSVMCUtr_EnRTrqTrqLm 100;
BA_ "GenSigStartValue" SG_ 2348810257 TSC1EMSVMCUtr_EnRTrqTrqLm 255;
BA_ "Platform_VMCU1_Sig" SG_ 2348810257 TSC1EMSVMCUtr_EnRTrqTrqLm 1;
BA_ "SPN" SG_ 2348810257 TSC1EMSVMCUtr_EnRTrqTrqLm 518;
BA_ "SeToolAncestorID_SIGNAL" SG_ 2348810257 TSC1EMSVMCUtr_EnRTrqTrqLm "x0000001D042564D4";
BA_ "SeToolItemID_SIGNAL" SG_ 2348810257 TSC1EMSVMCUtr_EnRTrqTrqLm "x0000001D042564D4";
BA_ "SeToolName_SIGNAL" SG_ 2348810257 TSC1EMSVMCUtr_EnRTrqTrqLm "EnRTrqTrqLm";
BA_ "SeToolOwnerSigGroupID_SIGNAL" SG_ 2348810257 TSC1EMSVMCUtr_EnRTrqTrqLm "x0000001D043FB710";
BA_ "SeToolOwnerSigGroup_SIGNAL" SG_ 2348810257 TSC1EMSVMCUtr_EnRTrqTrqLm "TSC1EMSVMCUtr";
BA_ "SeToolVersion_SIGNAL" SG_ 2348810257 TSC1EMSVMCUtr_EnRTrqTrqLm "1";
BA_ "GenSigSendType" SG_ 2348810288 TSC1EMSVMCUes_OvrdCtrlMPr 7;
BA_ "GenSigCycleTime" SG_ 2348810288 TSC1EMSVMCUes_OvrdCtrlMPr 100;
BA_ "GenSigCycleTimeActive" SG_ 2348810288 TSC1EMSVMCUes_OvrdCtrlMPr 100;
BA_ "GenSigStartValue" SG_ 2348810288 TSC1EMSVMCUes_OvrdCtrlMPr 3;
BA_ "Platform_VMCU1_Sig" SG_ 2348810288 TSC1EMSVMCUes_OvrdCtrlMPr 1;
BA_ "SPN" SG_ 2348810288 TSC1EMSVMCUes_OvrdCtrlMPr 897;
BA_ "SeToolAncestorID_SIGNAL" SG_ 2348810288 TSC1EMSVMCUes_OvrdCtrlMPr "x0000001D042564CE";
BA_ "SeToolItemID_SIGNAL" SG_ 2348810288 TSC1EMSVMCUes_OvrdCtrlMPr "x0000001D042564CE";
BA_ "SeToolName_SIGNAL" SG_ 2348810288 TSC1EMSVMCUes_OvrdCtrlMPr "OvrdCtrlMPr";
BA_ "SeToolOwnerSigGroupID_SIGNAL" SG_ 2348810288 TSC1EMSVMCUes_OvrdCtrlMPr "x0000001D0436B0FF";
BA_ "SeToolOwnerSigGroup_SIGNAL" SG_ 2348810288 TSC1EMSVMCUes_OvrdCtrlMPr "TSC1EMSVMCUes";
BA_ "SeToolVersion_SIGNAL" SG_ 2348810288 TSC1EMSVMCUes_OvrdCtrlMPr "1";
BA_ "GenSigSendType" SG_ 2348810288 TSC1EMSVMCUes_EnRTrqTrqLm 7;
BA_ "GenSigCycleTime" SG_ 2348810288 TSC1EMSVMCUes_EnRTrqTrqLm 100;
BA_ "GenSigCycleTimeActive" SG_ 2348810288 TSC1EMSVMCUes_EnRTrqTrqLm 100;
BA_ "GenSigStartValue" SG_ 2348810288 TSC1EMSVMCUes_EnRTrqTrqLm 255;
BA_ "Platform_VMCU1_Sig" SG_ 2348810288 TSC1EMSVMCUes_EnRTrqTrqLm 1;
BA_ "SPN" SG_ 2348810288 TSC1EMSVMCUes_EnRTrqTrqLm 518;
BA_ "SeToolAncestorID_SIGNAL" SG_ 2348810288 TSC1EMSVMCUes_EnRTrqTrqLm "x0000001D042564D4";
BA_ "SeToolItemID_SIGNAL" SG_ 2348810288 TSC1EMSVMCUes_EnRTrqTrqLm "x0000001D042564D4";
BA_ "SeToolName_SIGNAL" SG_ 2348810288 TSC1EMSVMCUes_EnRTrqTrqLm "EnRTrqTrqLm";
BA_ "SeToolOwnerSigGroupID_SIGNAL" SG_ 2348810288 TSC1EMSVMCUes_EnRTrqTrqLm "x0000001D0436B0FF";
BA_ "SeToolOwnerSigGroup_SIGNAL" SG_ 2348810288 TSC1EMSVMCUes_EnRTrqTrqLm "TSC1EMSVMCUes";
BA_ "SeToolVersion_SIGNAL" SG_ 2348810288 TSC1EMSVMCUes_EnRTrqTrqLm "1";
BA_ "GenSigSendType" SG_ 2348810288 TSC1EMSVMCUes_EnOvrdCtrlM 6;
BA_ "Platform_VMCU1_Sig" SG_ 2348810288 TSC1EMSVMCUes_EnOvrdCtrlM 1;
BA_ "SPN" SG_ 2348810288 TSC1EMSVMCUes_EnOvrdCtrlM 695;
BA_ "SeToolAncestorID_SIGNAL" SG_ 2348810288 TSC1EMSVMCUes_EnOvrdCtrlM "x0000001D042564C7";
BA_ "SeToolItemID_SIGNAL" SG_ 2348810288 TSC1EMSVMCUes_EnOvrdCtrlM "x0000001D042564C7";
BA_ "SeToolName_SIGNAL" SG_ 2348810288 TSC1EMSVMCUes_EnOvrdCtrlM "EnOvrdCtrlM";
BA_ "SeToolOwnerSigGroupID_SIGNAL" SG_ 2348810288 TSC1EMSVMCUes_EnOvrdCtrlM "x0000001D0436B0FF";
BA_ "SeToolOwnerSigGroup_SIGNAL" SG_ 2348810288 TSC1EMSVMCUes_EnOvrdCtrlM "TSC1EMSVMCUes";
BA_ "SeToolVersion_SIGNAL" SG_ 2348810288 TSC1EMSVMCUes_EnOvrdCtrlM "1";
BA_ "GenSigSendType" SG_ 2348810288 TSC1EMSVMCUes_EnRSpdSpdLm 7;
BA_ "GenSigCycleTime" SG_ 2348810288 TSC1EMSVMCUes_EnRSpdSpdLm 100;
BA_ "GenSigCycleTimeActive" SG_ 2348810288 TSC1EMSVMCUes_EnRSpdSpdLm 100;
BA_ "GenSigStartValue" SG_ 2348810288 TSC1EMSVMCUes_EnRSpdSpdLm 65535;
BA_ "Platform_VMCU1_Sig" SG_ 2348810288 TSC1EMSVMCUes_EnRSpdSpdLm 1;
BA_ "SPN" SG_ 2348810288 TSC1EMSVMCUes_EnRSpdSpdLm 898;
BA_ "SeToolAncestorID_SIGNAL" SG_ 2348810288 TSC1EMSVMCUes_EnRSpdSpdLm "x0000001D042564D1";
BA_ "SeToolItemID_SIGNAL" SG_ 2348810288 TSC1EMSVMCUes_EnRSpdSpdLm "x0000001D042564D1";
BA_ "SeToolName_SIGNAL" SG_ 2348810288 TSC1EMSVMCUes_EnRSpdSpdLm "EnRSpdSpdLm";
BA_ "SeToolOwnerSigGroupID_SIGNAL" SG_ 2348810288 TSC1EMSVMCUes_EnRSpdSpdLm "x0000001D0436B0FF";
BA_ "SeToolOwnerSigGroup_SIGNAL" SG_ 2348810288 TSC1EMSVMCUes_EnRSpdSpdLm "TSC1EMSVMCUes";
BA_ "SeToolVersion_SIGNAL" SG_ 2348810288 TSC1EMSVMCUes_EnRSpdSpdLm "1";
BA_ "GenSigSendType" SG_ 2348810288 TSC1EMSVMCUes_EnRSpdCtrlC 7;
BA_ "GenSigCycleTime" SG_ 2348810288 TSC1EMSVMCUes_EnRSpdCtrlC 100;
BA_ "GenSigCycleTimeActive" SG_ 2348810288 TSC1EMSVMCUes_EnRSpdCtrlC 100;
BA_ "Platform_VMCU1_Sig" SG_ 2348810288 TSC1EMSVMCUes_EnRSpdCtrlC 1;
BA_ "SPN" SG_ 2348810288 TSC1EMSVMCUes_EnRSpdCtrlC 696;
BA_ "SeToolAncestorID_SIGNAL" SG_ 2348810288 TSC1EMSVMCUes_EnRSpdCtrlC "x0000001D042564C9";
BA_ "SeToolItemID_SIGNAL" SG_ 2348810288 TSC1EMSVMCUes_EnRSpdCtrlC "x0000001D042564C9";
BA_ "SeToolName_SIGNAL" SG_ 2348810288 TSC1EMSVMCUes_EnRSpdCtrlC "EnRSpdCtrlC";
BA_ "SeToolOwnerSigGroupID_SIGNAL" SG_ 2348810288 TSC1EMSVMCUes_EnRSpdCtrlC "x0000001D0436B0FF";
BA_ "SeToolOwnerSigGroup_SIGNAL" SG_ 2348810288 TSC1EMSVMCUes_EnRSpdCtrlC "TSC1EMSVMCUes";
BA_ "SeToolVersion_SIGNAL" SG_ 2348810288 TSC1EMSVMCUes_EnRSpdCtrlC "1";
BA_ "GenSigSendType" SG_ 2348810243 TSC1EMSTECU_EnRSpdSpdLm 7;
BA_ "GenSigCycleTime" SG_ 2348810243 TSC1EMSTECU_EnRSpdSpdLm 100;
BA_ "GenSigCycleTimeActive" SG_ 2348810243 TSC1EMSTECU_EnRSpdSpdLm 100;
BA_ "GenSigStartValue" SG_ 2348810243 TSC1EMSTECU_EnRSpdSpdLm 65535;
BA_ "Platform_VMCU1_Sig" SG_ 2348810243 TSC1EMSTECU_EnRSpdSpdLm 1;
BA_ "SPN" SG_ 2348810243 TSC1EMSTECU_EnRSpdSpdLm 898;
BA_ "SeToolAncestorID_SIGNAL" SG_ 2348810243 TSC1EMSTECU_EnRSpdSpdLm "x0000001D042564D1";
BA_ "SeToolItemID_SIGNAL" SG_ 2348810243 TSC1EMSTECU_EnRSpdSpdLm "x0000001D042564D1";
BA_ "SeToolName_SIGNAL" SG_ 2348810243 TSC1EMSTECU_EnRSpdSpdLm "EnRSpdSpdLm";
BA_ "SeToolOwnerSigGroupID_SIGNAL" SG_ 2348810243 TSC1EMSTECU_EnRSpdSpdLm "x0000001D043D7655";
BA_ "SeToolOwnerSigGroup_SIGNAL" SG_ 2348810243 TSC1EMSTECU_EnRSpdSpdLm "TSC1_TECU_EMS";
BA_ "SeToolVersion_SIGNAL" SG_ 2348810243 TSC1EMSTECU_EnRSpdSpdLm "1";
BA_ "GenSigSendType" SG_ 2348810243 TSC1EMSTECU_EnOvrdCtrlM 6;
BA_ "Platform_VMCU1_Sig" SG_ 2348810243 TSC1EMSTECU_EnOvrdCtrlM 1;
BA_ "SPN" SG_ 2348810243 TSC1EMSTECU_EnOvrdCtrlM 695;
BA_ "SeToolAncestorID_SIGNAL" SG_ 2348810243 TSC1EMSTECU_EnOvrdCtrlM "x0000001D042564C7";
BA_ "SeToolItemID_SIGNAL" SG_ 2348810243 TSC1EMSTECU_EnOvrdCtrlM "x0000001D042564C7";
BA_ "SeToolName_SIGNAL" SG_ 2348810243 TSC1EMSTECU_EnOvrdCtrlM "EnOvrdCtrlM";
BA_ "SeToolOwnerSigGroupID_SIGNAL" SG_ 2348810243 TSC1EMSTECU_EnOvrdCtrlM "x0000001D043D7655";
BA_ "SeToolOwnerSigGroup_SIGNAL" SG_ 2348810243 TSC1EMSTECU_EnOvrdCtrlM "TSC1_TECU_EMS";
BA_ "SeToolVersion_SIGNAL" SG_ 2348810243 TSC1EMSTECU_EnOvrdCtrlM "1";
BA_ "GenSigSendType" SG_ 2348810243 TSC1EMSTECU_OvrdCtrlMPr 7;
BA_ "GenSigCycleTime" SG_ 2348810243 TSC1EMSTECU_OvrdCtrlMPr 100;
BA_ "GenSigCycleTimeActive" SG_ 2348810243 TSC1EMSTECU_OvrdCtrlMPr 100;
BA_ "GenSigStartValue" SG_ 2348810243 TSC1EMSTECU_OvrdCtrlMPr 3;
BA_ "Platform_VMCU1_Sig" SG_ 2348810243 TSC1EMSTECU_OvrdCtrlMPr 1;
BA_ "SPN" SG_ 2348810243 TSC1EMSTECU_OvrdCtrlMPr 897;
BA_ "SeToolAncestorID_SIGNAL" SG_ 2348810243 TSC1EMSTECU_OvrdCtrlMPr "x0000001D042564CE";
BA_ "SeToolItemID_SIGNAL" SG_ 2348810243 TSC1EMSTECU_OvrdCtrlMPr "x0000001D042564CE";
BA_ "SeToolName_SIGNAL" SG_ 2348810243 TSC1EMSTECU_OvrdCtrlMPr "OvrdCtrlMPr";
BA_ "SeToolOwnerSigGroupID_SIGNAL" SG_ 2348810243 TSC1EMSTECU_OvrdCtrlMPr "x0000001D043D7655";
BA_ "SeToolOwnerSigGroup_SIGNAL" SG_ 2348810243 TSC1EMSTECU_OvrdCtrlMPr "TSC1_TECU_EMS";
BA_ "SeToolVersion_SIGNAL" SG_ 2348810243 TSC1EMSTECU_OvrdCtrlMPr "1";
BA_ "GenSigSendType" SG_ 2348810243 TSC1EMSTECU_EnRSpdCtrlC 7;
BA_ "GenSigCycleTime" SG_ 2348810243 TSC1EMSTECU_EnRSpdCtrlC 100;
BA_ "GenSigCycleTimeActive" SG_ 2348810243 TSC1EMSTECU_EnRSpdCtrlC 100;
BA_ "Platform_VMCU1_Sig" SG_ 2348810243 TSC1EMSTECU_EnRSpdCtrlC 1;
BA_ "SPN" SG_ 2348810243 TSC1EMSTECU_EnRSpdCtrlC 696;
BA_ "SeToolAncestorID_SIGNAL" SG_ 2348810243 TSC1EMSTECU_EnRSpdCtrlC "x0000001D042564C9";
BA_ "SeToolItemID_SIGNAL" SG_ 2348810243 TSC1EMSTECU_EnRSpdCtrlC "x0000001D042564C9";
BA_ "SeToolName_SIGNAL" SG_ 2348810243 TSC1EMSTECU_EnRSpdCtrlC "EnRSpdCtrlC";
BA_ "SeToolOwnerSigGroupID_SIGNAL" SG_ 2348810243 TSC1EMSTECU_EnRSpdCtrlC "x0000001D043D7655";
BA_ "SeToolOwnerSigGroup_SIGNAL" SG_ 2348810243 TSC1EMSTECU_EnRSpdCtrlC "TSC1_TECU_EMS";
BA_ "SeToolVersion_SIGNAL" SG_ 2348810243 TSC1EMSTECU_EnRSpdCtrlC "1";
BA_ "GenSigSendType" SG_ 2348810243 TSC1EMSTECU_EnRTrqTrqLm 7;
BA_ "GenSigCycleTime" SG_ 2348810243 TSC1EMSTECU_EnRTrqTrqLm 100;
BA_ "GenSigCycleTimeActive" SG_ 2348810243 TSC1EMSTECU_EnRTrqTrqLm 100;
BA_ "GenSigStartValue" SG_ 2348810243 TSC1EMSTECU_EnRTrqTrqLm 255;
BA_ "Platform_VMCU1_Sig" SG_ 2348810243 TSC1EMSTECU_EnRTrqTrqLm 1;
BA_ "SPN" SG_ 2348810243 TSC1EMSTECU_EnRTrqTrqLm 518;
BA_ "SeToolAncestorID_SIGNAL" SG_ 2348810243 TSC1EMSTECU_EnRTrqTrqLm "x0000001D042564D4";
BA_ "SeToolItemID_SIGNAL" SG_ 2348810243 TSC1EMSTECU_EnRTrqTrqLm "x0000001D042564D4";
BA_ "SeToolName_SIGNAL" SG_ 2348810243 TSC1EMSTECU_EnRTrqTrqLm "EnRTrqTrqLm";
BA_ "SeToolOwnerSigGroupID_SIGNAL" SG_ 2348810243 TSC1EMSTECU_EnRTrqTrqLm "x0000001D043D7655";
BA_ "SeToolOwnerSigGroup_SIGNAL" SG_ 2348810243 TSC1EMSTECU_EnRTrqTrqLm "TSC1_TECU_EMS";
BA_ "SeToolVersion_SIGNAL" SG_ 2348810243 TSC1EMSTECU_EnRTrqTrqLm "1";
BA_ "GenSigSendType" SG_ 2348810251 TSC1EMSABS_EnRTrqTrqLm 7;
BA_ "GenSigCycleTime" SG_ 2348810251 TSC1EMSABS_EnRTrqTrqLm 100;
BA_ "GenSigCycleTimeActive" SG_ 2348810251 TSC1EMSABS_EnRTrqTrqLm 100;
BA_ "GenSigStartValue" SG_ 2348810251 TSC1EMSABS_EnRTrqTrqLm 255;
BA_ "Platform_VMCU1_Sig" SG_ 2348810251 TSC1EMSABS_EnRTrqTrqLm 1;
BA_ "SPN" SG_ 2348810251 TSC1EMSABS_EnRTrqTrqLm 518;
BA_ "SeToolAncestorID_SIGNAL" SG_ 2348810251 TSC1EMSABS_EnRTrqTrqLm "x0000001D042564D4";
BA_ "SeToolItemID_SIGNAL" SG_ 2348810251 TSC1EMSABS_EnRTrqTrqLm "x0000001D042564D4";
BA_ "SeToolName_SIGNAL" SG_ 2348810251 TSC1EMSABS_EnRTrqTrqLm "EnRTrqTrqLm";
BA_ "SeToolOwnerSigGroupID_SIGNAL" SG_ 2348810251 TSC1EMSABS_EnRTrqTrqLm "x0000001D043D6E46";
BA_ "SeToolOwnerSigGroup_SIGNAL" SG_ 2348810251 TSC1EMSABS_EnRTrqTrqLm "TSC1EMSABS";
BA_ "SeToolVersion_SIGNAL" SG_ 2348810251 TSC1EMSABS_EnRTrqTrqLm "1";
BA_ "GenSigSendType" SG_ 2348810251 TSC1EMSABS_EnRSpdCtrlC 7;
BA_ "GenSigCycleTime" SG_ 2348810251 TSC1EMSABS_EnRSpdCtrlC 100;
BA_ "GenSigCycleTimeActive" SG_ 2348810251 TSC1EMSABS_EnRSpdCtrlC 100;
BA_ "Platform_VMCU1_Sig" SG_ 2348810251 TSC1EMSABS_EnRSpdCtrlC 1;
BA_ "SPN" SG_ 2348810251 TSC1EMSABS_EnRSpdCtrlC 696;
BA_ "SeToolAncestorID_SIGNAL" SG_ 2348810251 TSC1EMSABS_EnRSpdCtrlC "x0000001D042564C9";
BA_ "SeToolItemID_SIGNAL" SG_ 2348810251 TSC1EMSABS_EnRSpdCtrlC "x0000001D042564C9";
BA_ "SeToolName_SIGNAL" SG_ 2348810251 TSC1EMSABS_EnRSpdCtrlC "EnRSpdCtrlC";
BA_ "SeToolOwnerSigGroupID_SIGNAL" SG_ 2348810251 TSC1EMSABS_EnRSpdCtrlC "x0000001D043D6E46";
BA_ "SeToolOwnerSigGroup_SIGNAL" SG_ 2348810251 TSC1EMSABS_EnRSpdCtrlC "TSC1EMSABS";
BA_ "SeToolVersion_SIGNAL" SG_ 2348810251 TSC1EMSABS_EnRSpdCtrlC "1";
BA_ "GenSigSendType" SG_ 2348810251 TSC1EMSABS_OvrdCtrlMPr 7;
BA_ "GenSigCycleTime" SG_ 2348810251 TSC1EMSABS_OvrdCtrlMPr 100;
BA_ "GenSigCycleTimeActive" SG_ 2348810251 TSC1EMSABS_OvrdCtrlMPr 100;
BA_ "GenSigStartValue" SG_ 2348810251 TSC1EMSABS_OvrdCtrlMPr 3;
BA_ "Platform_VMCU1_Sig" SG_ 2348810251 TSC1EMSABS_OvrdCtrlMPr 1;
BA_ "SPN" SG_ 2348810251 TSC1EMSABS_OvrdCtrlMPr 897;
BA_ "SeToolAncestorID_SIGNAL" SG_ 2348810251 TSC1EMSABS_OvrdCtrlMPr "x0000001D042564CE";
BA_ "SeToolItemID_SIGNAL" SG_ 2348810251 TSC1EMSABS_OvrdCtrlMPr "x0000001D042564CE";
BA_ "SeToolName_SIGNAL" SG_ 2348810251 TSC1EMSABS_OvrdCtrlMPr "OvrdCtrlMPr";
BA_ "SeToolOwnerSigGroupID_SIGNAL" SG_ 2348810251 TSC1EMSABS_OvrdCtrlMPr "x0000001D043D6E46";
BA_ "SeToolOwnerSigGroup_SIGNAL" SG_ 2348810251 TSC1EMSABS_OvrdCtrlMPr "TSC1EMSABS";
BA_ "SeToolVersion_SIGNAL" SG_ 2348810251 TSC1EMSABS_OvrdCtrlMPr "1";
BA_ "GenSigSendType" SG_ 2348810251 TSC1EMSABS_EnOvrdCtrlM 6;
BA_ "Platform_VMCU1_Sig" SG_ 2348810251 TSC1EMSABS_EnOvrdCtrlM 1;
BA_ "SPN" SG_ 2348810251 TSC1EMSABS_EnOvrdCtrlM 695;
BA_ "SeToolAncestorID_SIGNAL" SG_ 2348810251 TSC1EMSABS_EnOvrdCtrlM "x0000001D042564C7";
BA_ "SeToolItemID_SIGNAL" SG_ 2348810251 TSC1EMSABS_EnOvrdCtrlM "x0000001D042564C7";
BA_ "SeToolName_SIGNAL" SG_ 2348810251 TSC1EMSABS_EnOvrdCtrlM "EnOvrdCtrlM";
BA_ "SeToolOwnerSigGroupID_SIGNAL" SG_ 2348810251 TSC1EMSABS_EnOvrdCtrlM "x0000001D043D6E46";
BA_ "SeToolOwnerSigGroup_SIGNAL" SG_ 2348810251 TSC1EMSABS_EnOvrdCtrlM "TSC1EMSABS";
BA_ "SeToolVersion_SIGNAL" SG_ 2348810251 TSC1EMSABS_EnOvrdCtrlM "1";
BA_ "GenSigSendType" SG_ 2348810251 TSC1EMSABS_EnRSpdSpdLm 7;
BA_ "GenSigCycleTime" SG_ 2348810251 TSC1EMSABS_EnRSpdSpdLm 100;
BA_ "GenSigCycleTimeActive" SG_ 2348810251 TSC1EMSABS_EnRSpdSpdLm 100;
BA_ "GenSigStartValue" SG_ 2348810251 TSC1EMSABS_EnRSpdSpdLm 65535;
BA_ "Platform_VMCU1_Sig" SG_ 2348810251 TSC1EMSABS_EnRSpdSpdLm 1;
BA_ "SPN" SG_ 2348810251 TSC1EMSABS_EnRSpdSpdLm 898;
BA_ "SeToolAncestorID_SIGNAL" SG_ 2348810251 TSC1EMSABS_EnRSpdSpdLm "x0000001D042564D1";
BA_ "SeToolItemID_SIGNAL" SG_ 2348810251 TSC1EMSABS_EnRSpdSpdLm "x0000001D042564D1";
BA_ "SeToolName_SIGNAL" SG_ 2348810251 TSC1EMSABS_EnRSpdSpdLm "EnRSpdSpdLm";
BA_ "SeToolOwnerSigGroupID_SIGNAL" SG_ 2348810251 TSC1EMSABS_EnRSpdSpdLm "x0000001D043D6E46";
BA_ "SeToolOwnerSigGroup_SIGNAL" SG_ 2348810251 TSC1EMSABS_EnRSpdSpdLm "TSC1EMSABS";
BA_ "SeToolVersion_SIGNAL" SG_ 2348810251 TSC1EMSABS_EnRSpdSpdLm "1";
BA_ "GenSigSendType" SG_ 2348810413 TSC1EMSDACU_OvrdCtrlMPr 7;
BA_ "GenSigCycleTime" SG_ 2348810413 TSC1EMSDACU_OvrdCtrlMPr 100;
BA_ "GenSigCycleTimeActive" SG_ 2348810413 TSC1EMSDACU_OvrdCtrlMPr 100;
BA_ "GenSigStartValue" SG_ 2348810413 TSC1EMSDACU_OvrdCtrlMPr 3;
BA_ "Platform_VMCU1_Sig" SG_ 2348810413 TSC1EMSDACU_OvrdCtrlMPr 1;
BA_ "SPN" SG_ 2348810413 TSC1EMSDACU_OvrdCtrlMPr 897;
BA_ "SeToolAncestorID_SIGNAL" SG_ 2348810413 TSC1EMSDACU_OvrdCtrlMPr "x0000001D042564CE";
BA_ "SeToolItemID_SIGNAL" SG_ 2348810413 TSC1EMSDACU_OvrdCtrlMPr "x0000001D042564CE";
BA_ "SeToolName_SIGNAL" SG_ 2348810413 TSC1EMSDACU_OvrdCtrlMPr "OvrdCtrlMPr";
BA_ "SeToolOwnerSigGroupID_SIGNAL" SG_ 2348810413 TSC1EMSDACU_OvrdCtrlMPr "x0000001D0440D562";
BA_ "SeToolOwnerSigGroup_SIGNAL" SG_ 2348810413 TSC1EMSDACU_OvrdCtrlMPr "TSC1EMSDACU";
BA_ "SeToolVersion_SIGNAL" SG_ 2348810413 TSC1EMSDACU_OvrdCtrlMPr "1";
BA_ "GenSigSendType" SG_ 2348810413 TSC1EMSDACU_EnRSpdSpdLm 7;
BA_ "GenSigCycleTime" SG_ 2348810413 TSC1EMSDACU_EnRSpdSpdLm 100;
BA_ "GenSigCycleTimeActive" SG_ 2348810413 TSC1EMSDACU_EnRSpdSpdLm 100;
BA_ "GenSigStartValue" SG_ 2348810413 TSC1EMSDACU_EnRSpdSpdLm 65535;
BA_ "Platform_VMCU1_Sig" SG_ 2348810413 TSC1EMSDACU_EnRSpdSpdLm 1;
BA_ "SPN" SG_ 2348810413 TSC1EMSDACU_EnRSpdSpdLm 898;
BA_ "SeToolAncestorID_SIGNAL" SG_ 2348810413 TSC1EMSDACU_EnRSpdSpdLm "x0000001D042564D1";
BA_ "SeToolItemID_SIGNAL" SG_ 2348810413 TSC1EMSDACU_EnRSpdSpdLm "x0000001D042564D1";
BA_ "SeToolName_SIGNAL" SG_ 2348810413 TSC1EMSDACU_EnRSpdSpdLm "EnRSpdSpdLm";
BA_ "SeToolOwnerSigGroupID_SIGNAL" SG_ 2348810413 TSC1EMSDACU_EnRSpdSpdLm "x0000001D0440D562";
BA_ "SeToolOwnerSigGroup_SIGNAL" SG_ 2348810413 TSC1EMSDACU_EnRSpdSpdLm "TSC1EMSDACU";
BA_ "SeToolVersion_SIGNAL" SG_ 2348810413 TSC1EMSDACU_EnRSpdSpdLm "1";
BA_ "GenSigSendType" SG_ 2348810413 TSC1EMSDACU_EnRSpdCtrlC 7;
BA_ "GenSigCycleTime" SG_ 2348810413 TSC1EMSDACU_EnRSpdCtrlC 100;
BA_ "GenSigCycleTimeActive" SG_ 2348810413 TSC1EMSDACU_EnRSpdCtrlC 100;
BA_ "Platform_VMCU1_Sig" SG_ 2348810413 TSC1EMSDACU_EnRSpdCtrlC 1;
BA_ "SPN" SG_ 2348810413 TSC1EMSDACU_EnRSpdCtrlC 696;
BA_ "SeToolAncestorID_SIGNAL" SG_ 2348810413 TSC1EMSDACU_EnRSpdCtrlC "x0000001D042564C9";
BA_ "SeToolItemID_SIGNAL" SG_ 2348810413 TSC1EMSDACU_EnRSpdCtrlC "x0000001D042564C9";
BA_ "SeToolName_SIGNAL" SG_ 2348810413 TSC1EMSDACU_EnRSpdCtrlC "EnRSpdCtrlC";
BA_ "SeToolOwnerSigGroupID_SIGNAL" SG_ 2348810413 TSC1EMSDACU_EnRSpdCtrlC "x0000001D0440D562";
BA_ "SeToolOwnerSigGroup_SIGNAL" SG_ 2348810413 TSC1EMSDACU_EnRSpdCtrlC "TSC1EMSDACU";
BA_ "SeToolVersion_SIGNAL" SG_ 2348810413 TSC1EMSDACU_EnRSpdCtrlC "1";
BA_ "GenSigSendType" SG_ 2348810413 TSC1EMSDACU_EnRTrqTrqLm 7;
BA_ "GenSigCycleTime" SG_ 2348810413 TSC1EMSDACU_EnRTrqTrqLm 100;
BA_ "GenSigCycleTimeActive" SG_ 2348810413 TSC1EMSDACU_EnRTrqTrqLm 100;
BA_ "GenSigStartValue" SG_ 2348810413 TSC1EMSDACU_EnRTrqTrqLm 255;
BA_ "Platform_VMCU1_Sig" SG_ 2348810413 TSC1EMSDACU_EnRTrqTrqLm 1;
BA_ "SPN" SG_ 2348810413 TSC1EMSDACU_EnRTrqTrqLm 518;
BA_ "SeToolAncestorID_SIGNAL" SG_ 2348810413 TSC1EMSDACU_EnRTrqTrqLm "x0000001D042564D4";
BA_ "SeToolItemID_SIGNAL" SG_ 2348810413 TSC1EMSDACU_EnRTrqTrqLm "x0000001D042564D4";
BA_ "SeToolName_SIGNAL" SG_ 2348810413 TSC1EMSDACU_EnRTrqTrqLm "EnRTrqTrqLm";
BA_ "SeToolOwnerSigGroupID_SIGNAL" SG_ 2348810413 TSC1EMSDACU_EnRTrqTrqLm "x0000001D0440D562";
BA_ "SeToolOwnerSigGroup_SIGNAL" SG_ 2348810413 TSC1EMSDACU_EnRTrqTrqLm "TSC1EMSDACU";
BA_ "SeToolVersion_SIGNAL" SG_ 2348810413 TSC1EMSDACU_EnRTrqTrqLm "1";
BA_ "GenSigSendType" SG_ 2348810413 TSC1EMSDACU_EnOvrdCtrlM 6;
BA_ "Platform_VMCU1_Sig" SG_ 2348810413 TSC1EMSDACU_EnOvrdCtrlM 1;
BA_ "SPN" SG_ 2348810413 TSC1EMSDACU_EnOvrdCtrlM 695;
BA_ "SeToolAncestorID_SIGNAL" SG_ 2348810413 TSC1EMSDACU_EnOvrdCtrlM "x0000001D042564C7";
BA_ "SeToolItemID_SIGNAL" SG_ 2348810413 TSC1EMSDACU_EnOvrdCtrlM "x0000001D042564C7";
BA_ "SeToolName_SIGNAL" SG_ 2348810413 TSC1EMSDACU_EnOvrdCtrlM "EnOvrdCtrlM";
BA_ "SeToolOwnerSigGroupID_SIGNAL" SG_ 2348810413 TSC1EMSDACU_EnOvrdCtrlM "x0000001D0440D562";
BA_ "SeToolOwnerSigGroup_SIGNAL" SG_ 2348810413 TSC1EMSDACU_EnOvrdCtrlM "TSC1EMSDACU";
BA_ "SeToolVersion_SIGNAL" SG_ 2348810413 TSC1EMSDACU_EnOvrdCtrlM "1";
BA_ "GenSigSendType" SG_ 2348814097 TSC1EMSrVMCU_EnRSpdCtrlC 7;
BA_ "GenSigCycleTime" SG_ 2348814097 TSC1EMSrVMCU_EnRSpdCtrlC 100;
BA_ "GenSigCycleTimeActive" SG_ 2348814097 TSC1EMSrVMCU_EnRSpdCtrlC 100;
BA_ "Platform_VMCU1_Sig" SG_ 2348814097 TSC1EMSrVMCU_EnRSpdCtrlC 1;
BA_ "SPN" SG_ 2348814097 TSC1EMSrVMCU_EnRSpdCtrlC 696;
BA_ "SeToolAncestorID_SIGNAL" SG_ 2348814097 TSC1EMSrVMCU_EnRSpdCtrlC "x0000001D042564C9";
BA_ "SeToolItemID_SIGNAL" SG_ 2348814097 TSC1EMSrVMCU_EnRSpdCtrlC "x0000001D042564C9";
BA_ "SeToolName_SIGNAL" SG_ 2348814097 TSC1EMSrVMCU_EnRSpdCtrlC "EnRSpdCtrlC";
BA_ "SeToolOwnerSigGroupID_SIGNAL" SG_ 2348814097 TSC1EMSrVMCU_EnRSpdCtrlC "x0000001D043FB6F7";
BA_ "SeToolOwnerSigGroup_SIGNAL" SG_ 2348814097 TSC1EMSrVMCU_EnRSpdCtrlC "TSC1EMSrVMCU";
BA_ "SeToolVersion_SIGNAL" SG_ 2348814097 TSC1EMSrVMCU_EnRSpdCtrlC "1";
BA_ "GenSigSendType" SG_ 2348814097 TSC1EMSrVMCU_EnRTrqTrqLm 7;
BA_ "GenSigCycleTime" SG_ 2348814097 TSC1EMSrVMCU_EnRTrqTrqLm 100;
BA_ "GenSigCycleTimeActive" SG_ 2348814097 TSC1EMSrVMCU_EnRTrqTrqLm 100;
BA_ "GenSigStartValue" SG_ 2348814097 TSC1EMSrVMCU_EnRTrqTrqLm 255;
BA_ "Platform_VMCU1_Sig" SG_ 2348814097 TSC1EMSrVMCU_EnRTrqTrqLm 1;
BA_ "SPN" SG_ 2348814097 TSC1EMSrVMCU_EnRTrqTrqLm 518;
BA_ "SeToolAncestorID_SIGNAL" SG_ 2348814097 TSC1EMSrVMCU_EnRTrqTrqLm "x0000001D042564D4";
BA_ "SeToolItemID_SIGNAL" SG_ 2348814097 TSC1EMSrVMCU_EnRTrqTrqLm "x0000001D042564D4";
BA_ "SeToolName_SIGNAL" SG_ 2348814097 TSC1EMSrVMCU_EnRTrqTrqLm "EnRTrqTrqLm";
BA_ "SeToolOwnerSigGroupID_SIGNAL" SG_ 2348814097 TSC1EMSrVMCU_EnRTrqTrqLm "x0000001D043FB6F7";
BA_ "SeToolOwnerSigGroup_SIGNAL" SG_ 2348814097 TSC1EMSrVMCU_EnRTrqTrqLm "TSC1EMSrVMCU";
BA_ "SeToolVersion_SIGNAL" SG_ 2348814097 TSC1EMSrVMCU_EnRTrqTrqLm "1";
BA_ "GenSigSendType" SG_ 2348814097 TSC1EMSrVMCU_OvrdCtrlMPr 7;
BA_ "GenSigCycleTime" SG_ 2348814097 TSC1EMSrVMCU_OvrdCtrlMPr 100;
BA_ "GenSigCycleTimeActive" SG_ 2348814097 TSC1EMSrVMCU_OvrdCtrlMPr 100;
BA_ "GenSigStartValue" SG_ 2348814097 TSC1EMSrVMCU_OvrdCtrlMPr 3;
BA_ "Platform_VMCU1_Sig" SG_ 2348814097 TSC1EMSrVMCU_OvrdCtrlMPr 1;
BA_ "SPN" SG_ 2348814097 TSC1EMSrVMCU_OvrdCtrlMPr 897;
BA_ "SeToolAncestorID_SIGNAL" SG_ 2348814097 TSC1EMSrVMCU_OvrdCtrlMPr "x0000001D042564CE";
BA_ "SeToolItemID_SIGNAL" SG_ 2348814097 TSC1EMSrVMCU_OvrdCtrlMPr "x0000001D042564CE";
BA_ "SeToolName_SIGNAL" SG_ 2348814097 TSC1EMSrVMCU_OvrdCtrlMPr "OvrdCtrlMPr";
BA_ "SeToolOwnerSigGroupID_SIGNAL" SG_ 2348814097 TSC1EMSrVMCU_OvrdCtrlMPr "x0000001D043FB6F7";
BA_ "SeToolOwnerSigGroup_SIGNAL" SG_ 2348814097 TSC1EMSrVMCU_OvrdCtrlMPr "TSC1EMSrVMCU";
BA_ "SeToolVersion_SIGNAL" SG_ 2348814097 TSC1EMSrVMCU_OvrdCtrlMPr "1";
BA_ "GenSigSendType" SG_ 2348814097 TSC1EMSrVMCU_EnRSpdSpdLm 7;
BA_ "GenSigCycleTime" SG_ 2348814097 TSC1EMSrVMCU_EnRSpdSpdLm 100;
BA_ "GenSigCycleTimeActive" SG_ 2348814097 TSC1EMSrVMCU_EnRSpdSpdLm 100;
BA_ "GenSigStartValue" SG_ 2348814097 TSC1EMSrVMCU_EnRSpdSpdLm 65535;
BA_ "Platform_VMCU1_Sig" SG_ 2348814097 TSC1EMSrVMCU_EnRSpdSpdLm 1;
BA_ "SPN" SG_ 2348814097 TSC1EMSrVMCU_EnRSpdSpdLm 898;
BA_ "SeToolAncestorID_SIGNAL" SG_ 2348814097 TSC1EMSrVMCU_EnRSpdSpdLm "x0000001D042564D1";
BA_ "SeToolItemID_SIGNAL" SG_ 2348814097 TSC1EMSrVMCU_EnRSpdSpdLm "x0000001D042564D1";
BA_ "SeToolName_SIGNAL" SG_ 2348814097 TSC1EMSrVMCU_EnRSpdSpdLm "EnRSpdSpdLm";
BA_ "SeToolOwnerSigGroupID_SIGNAL" SG_ 2348814097 TSC1EMSrVMCU_EnRSpdSpdLm "x0000001D043FB6F7";
BA_ "SeToolOwnerSigGroup_SIGNAL" SG_ 2348814097 TSC1EMSrVMCU_EnRSpdSpdLm "TSC1EMSrVMCU";
BA_ "SeToolVersion_SIGNAL" SG_ 2348814097 TSC1EMSrVMCU_EnRSpdSpdLm "1";
BA_ "GenSigSendType" SG_ 2348814097 TSC1EMSrVMCU_EnOvrdCtrlM 6;
BA_ "Platform_VMCU1_Sig" SG_ 2348814097 TSC1EMSrVMCU_EnOvrdCtrlM 1;
BA_ "SPN" SG_ 2348814097 TSC1EMSrVMCU_EnOvrdCtrlM 695;
BA_ "SeToolAncestorID_SIGNAL" SG_ 2348814097 TSC1EMSrVMCU_EnOvrdCtrlM "x0000001D042564C7";
BA_ "SeToolItemID_SIGNAL" SG_ 2348814097 TSC1EMSrVMCU_EnOvrdCtrlM "x0000001D042564C7";
BA_ "SeToolName_SIGNAL" SG_ 2348814097 TSC1EMSrVMCU_EnOvrdCtrlM "EnOvrdCtrlM";
BA_ "SeToolOwnerSigGroupID_SIGNAL" SG_ 2348814097 TSC1EMSrVMCU_EnOvrdCtrlM "x0000001D043FB6F7";
BA_ "SeToolOwnerSigGroup_SIGNAL" SG_ 2348814097 TSC1EMSrVMCU_EnOvrdCtrlM "TSC1EMSrVMCU";
BA_ "SeToolVersion_SIGNAL" SG_ 2348814097 TSC1EMSrVMCU_EnOvrdCtrlM "1";
BA_ "GenSigSendType" SG_ 2348814083 TSC1EMSrTECU_OvrdCtrlMPr 7;
BA_ "GenSigCycleTime" SG_ 2348814083 TSC1EMSrTECU_OvrdCtrlMPr 100;
BA_ "GenSigCycleTimeActive" SG_ 2348814083 TSC1EMSrTECU_OvrdCtrlMPr 100;
BA_ "GenSigStartValue" SG_ 2348814083 TSC1EMSrTECU_OvrdCtrlMPr 3;
BA_ "Platform_VMCU1_Sig" SG_ 2348814083 TSC1EMSrTECU_OvrdCtrlMPr 1;
BA_ "SPN" SG_ 2348814083 TSC1EMSrTECU_OvrdCtrlMPr 897;
BA_ "SeToolAncestorID_SIGNAL" SG_ 2348814083 TSC1EMSrTECU_OvrdCtrlMPr "x0000001D042564CE";
BA_ "SeToolItemID_SIGNAL" SG_ 2348814083 TSC1EMSrTECU_OvrdCtrlMPr "x0000001D042564CE";
BA_ "SeToolName_SIGNAL" SG_ 2348814083 TSC1EMSrTECU_OvrdCtrlMPr "OvrdCtrlMPr";
BA_ "SeToolOwnerSigGroupID_SIGNAL" SG_ 2348814083 TSC1EMSrTECU_OvrdCtrlMPr "x0000001D043D766D";
BA_ "SeToolOwnerSigGroup_SIGNAL" SG_ 2348814083 TSC1EMSrTECU_OvrdCtrlMPr "TSC1_TECU_EMS_Ret";
BA_ "SeToolVersion_SIGNAL" SG_ 2348814083 TSC1EMSrTECU_OvrdCtrlMPr "1";
BA_ "GenSigSendType" SG_ 2348814083 TSC1EMSrTECU_EnRSpdCtrlC 7;
BA_ "GenSigCycleTime" SG_ 2348814083 TSC1EMSrTECU_EnRSpdCtrlC 100;
BA_ "GenSigCycleTimeActive" SG_ 2348814083 TSC1EMSrTECU_EnRSpdCtrlC 100;
BA_ "Platform_VMCU1_Sig" SG_ 2348814083 TSC1EMSrTECU_EnRSpdCtrlC 1;
BA_ "SPN" SG_ 2348814083 TSC1EMSrTECU_EnRSpdCtrlC 696;
BA_ "SeToolAncestorID_SIGNAL" SG_ 2348814083 TSC1EMSrTECU_EnRSpdCtrlC "x0000001D042564C9";
BA_ "SeToolItemID_SIGNAL" SG_ 2348814083 TSC1EMSrTECU_EnRSpdCtrlC "x0000001D042564C9";
BA_ "SeToolName_SIGNAL" SG_ 2348814083 TSC1EMSrTECU_EnRSpdCtrlC "EnRSpdCtrlC";
BA_ "SeToolOwnerSigGroupID_SIGNAL" SG_ 2348814083 TSC1EMSrTECU_EnRSpdCtrlC "x0000001D043D766D";
BA_ "SeToolOwnerSigGroup_SIGNAL" SG_ 2348814083 TSC1EMSrTECU_EnRSpdCtrlC "TSC1_TECU_EMS_Ret";
BA_ "SeToolVersion_SIGNAL" SG_ 2348814083 TSC1EMSrTECU_EnRSpdCtrlC "1";
BA_ "GenSigSendType" SG_ 2348814083 TSC1EMSrTECU_EnOvrdCtrlM 6;
BA_ "Platform_VMCU1_Sig" SG_ 2348814083 TSC1EMSrTECU_EnOvrdCtrlM 1;
BA_ "SPN" SG_ 2348814083 TSC1EMSrTECU_EnOvrdCtrlM 695;
BA_ "SeToolAncestorID_SIGNAL" SG_ 2348814083 TSC1EMSrTECU_EnOvrdCtrlM "x0000001D042564C7";
BA_ "SeToolItemID_SIGNAL" SG_ 2348814083 TSC1EMSrTECU_EnOvrdCtrlM "x0000001D042564C7";
BA_ "SeToolName_SIGNAL" SG_ 2348814083 TSC1EMSrTECU_EnOvrdCtrlM "EnOvrdCtrlM";
BA_ "SeToolOwnerSigGroupID_SIGNAL" SG_ 2348814083 TSC1EMSrTECU_EnOvrdCtrlM "x0000001D043D766D";
BA_ "SeToolOwnerSigGroup_SIGNAL" SG_ 2348814083 TSC1EMSrTECU_EnOvrdCtrlM "TSC1_TECU_EMS_Ret";
BA_ "SeToolVersion_SIGNAL" SG_ 2348814083 TSC1EMSrTECU_EnOvrdCtrlM "1";
BA_ "GenSigSendType" SG_ 2348814083 TSC1EMSrTECU_EnRTrqTrqLm 7;
BA_ "GenSigCycleTime" SG_ 2348814083 TSC1EMSrTECU_EnRTrqTrqLm 100;
BA_ "GenSigCycleTimeActive" SG_ 2348814083 TSC1EMSrTECU_EnRTrqTrqLm 100;
BA_ "GenSigStartValue" SG_ 2348814083 TSC1EMSrTECU_EnRTrqTrqLm 255;
BA_ "Platform_VMCU1_Sig" SG_ 2348814083 TSC1EMSrTECU_EnRTrqTrqLm 1;
BA_ "SPN" SG_ 2348814083 TSC1EMSrTECU_EnRTrqTrqLm 518;
BA_ "SeToolAncestorID_SIGNAL" SG_ 2348814083 TSC1EMSrTECU_EnRTrqTrqLm "x0000001D042564D4";
BA_ "SeToolItemID_SIGNAL" SG_ 2348814083 TSC1EMSrTECU_EnRTrqTrqLm "x0000001D042564D4";
BA_ "SeToolName_SIGNAL" SG_ 2348814083 TSC1EMSrTECU_EnRTrqTrqLm "EnRTrqTrqLm";
BA_ "SeToolOwnerSigGroupID_SIGNAL" SG_ 2348814083 TSC1EMSrTECU_EnRTrqTrqLm "x0000001D043D766D";
BA_ "SeToolOwnerSigGroup_SIGNAL" SG_ 2348814083 TSC1EMSrTECU_EnRTrqTrqLm "TSC1_TECU_EMS_Ret";
BA_ "SeToolVersion_SIGNAL" SG_ 2348814083 TSC1EMSrTECU_EnRTrqTrqLm "1";
BA_ "GenSigSendType" SG_ 2348814083 TSC1EMSrTECU_EnRSpdSpdLm 7;
BA_ "GenSigCycleTime" SG_ 2348814083 TSC1EMSrTECU_EnRSpdSpdLm 100;
BA_ "GenSigCycleTimeActive" SG_ 2348814083 TSC1EMSrTECU_EnRSpdSpdLm 100;
BA_ "GenSigStartValue" SG_ 2348814083 TSC1EMSrTECU_EnRSpdSpdLm 65535;
BA_ "Platform_VMCU1_Sig" SG_ 2348814083 TSC1EMSrTECU_EnRSpdSpdLm 1;
BA_ "SPN" SG_ 2348814083 TSC1EMSrTECU_EnRSpdSpdLm 898;
BA_ "SeToolAncestorID_SIGNAL" SG_ 2348814083 TSC1EMSrTECU_EnRSpdSpdLm "x0000001D042564D1";
BA_ "SeToolItemID_SIGNAL" SG_ 2348814083 TSC1EMSrTECU_EnRSpdSpdLm "x0000001D042564D1";
BA_ "SeToolName_SIGNAL" SG_ 2348814083 TSC1EMSrTECU_EnRSpdSpdLm "EnRSpdSpdLm";
BA_ "SeToolOwnerSigGroupID_SIGNAL" SG_ 2348814083 TSC1EMSrTECU_EnRSpdSpdLm "x0000001D043D766D";
BA_ "SeToolOwnerSigGroup_SIGNAL" SG_ 2348814083 TSC1EMSrTECU_EnRSpdSpdLm "TSC1_TECU_EMS_Ret";
BA_ "SeToolVersion_SIGNAL" SG_ 2348814083 TSC1EMSrTECU_EnRSpdSpdLm "1";
BA_ "GenSigSendType" SG_ 2348814091 TSC1EMSrABS_EnRTrqTrqLm 7;
BA_ "GenSigCycleTime" SG_ 2348814091 TSC1EMSrABS_EnRTrqTrqLm 100;
BA_ "GenSigCycleTimeActive" SG_ 2348814091 TSC1EMSrABS_EnRTrqTrqLm 100;
BA_ "GenSigStartValue" SG_ 2348814091 TSC1EMSrABS_EnRTrqTrqLm 255;
BA_ "Platform_VMCU1_Sig" SG_ 2348814091 TSC1EMSrABS_EnRTrqTrqLm 1;
BA_ "SPN" SG_ 2348814091 TSC1EMSrABS_EnRTrqTrqLm 518;
BA_ "SeToolAncestorID_SIGNAL" SG_ 2348814091 TSC1EMSrABS_EnRTrqTrqLm "x0000001D042564D4";
BA_ "SeToolItemID_SIGNAL" SG_ 2348814091 TSC1EMSrABS_EnRTrqTrqLm "x0000001D042564D4";
BA_ "SeToolName_SIGNAL" SG_ 2348814091 TSC1EMSrABS_EnRTrqTrqLm "EnRTrqTrqLm";
BA_ "SeToolOwnerSigGroupID_SIGNAL" SG_ 2348814091 TSC1EMSrABS_EnRTrqTrqLm "x0000001D043D6A13";
BA_ "SeToolOwnerSigGroup_SIGNAL" SG_ 2348814091 TSC1EMSrABS_EnRTrqTrqLm "TSC1EMSrABS";
BA_ "SeToolVersion_SIGNAL" SG_ 2348814091 TSC1EMSrABS_EnRTrqTrqLm "1";
BA_ "GenSigSendType" SG_ 2348814091 TSC1EMSrABS_EnRSpdCtrlC 7;
BA_ "GenSigCycleTime" SG_ 2348814091 TSC1EMSrABS_EnRSpdCtrlC 100;
BA_ "GenSigCycleTimeActive" SG_ 2348814091 TSC1EMSrABS_EnRSpdCtrlC 100;
BA_ "Platform_VMCU1_Sig" SG_ 2348814091 TSC1EMSrABS_EnRSpdCtrlC 1;
BA_ "SPN" SG_ 2348814091 TSC1EMSrABS_EnRSpdCtrlC 696;
BA_ "SeToolAncestorID_SIGNAL" SG_ 2348814091 TSC1EMSrABS_EnRSpdCtrlC "x0000001D042564C9";
BA_ "SeToolItemID_SIGNAL" SG_ 2348814091 TSC1EMSrABS_EnRSpdCtrlC "x0000001D042564C9";
BA_ "SeToolName_SIGNAL" SG_ 2348814091 TSC1EMSrABS_EnRSpdCtrlC "EnRSpdCtrlC";
BA_ "SeToolOwnerSigGroupID_SIGNAL" SG_ 2348814091 TSC1EMSrABS_EnRSpdCtrlC "x0000001D043D6A13";
BA_ "SeToolOwnerSigGroup_SIGNAL" SG_ 2348814091 TSC1EMSrABS_EnRSpdCtrlC "TSC1EMSrABS";
BA_ "SeToolVersion_SIGNAL" SG_ 2348814091 TSC1EMSrABS_EnRSpdCtrlC "1";
BA_ "GenSigSendType" SG_ 2348814091 TSC1EMSrABS_OvrdCtrlMPr 7;
BA_ "GenSigCycleTime" SG_ 2348814091 TSC1EMSrABS_OvrdCtrlMPr 100;
BA_ "GenSigCycleTimeActive" SG_ 2348814091 TSC1EMSrABS_OvrdCtrlMPr 100;
BA_ "GenSigStartValue" SG_ 2348814091 TSC1EMSrABS_OvrdCtrlMPr 3;
BA_ "Platform_VMCU1_Sig" SG_ 2348814091 TSC1EMSrABS_OvrdCtrlMPr 1;
BA_ "SPN" SG_ 2348814091 TSC1EMSrABS_OvrdCtrlMPr 897;
BA_ "SeToolAncestorID_SIGNAL" SG_ 2348814091 TSC1EMSrABS_OvrdCtrlMPr "x0000001D042564CE";
BA_ "SeToolItemID_SIGNAL" SG_ 2348814091 TSC1EMSrABS_OvrdCtrlMPr "x0000001D042564CE";
BA_ "SeToolName_SIGNAL" SG_ 2348814091 TSC1EMSrABS_OvrdCtrlMPr "OvrdCtrlMPr";
BA_ "SeToolOwnerSigGroupID_SIGNAL" SG_ 2348814091 TSC1EMSrABS_OvrdCtrlMPr "x0000001D043D6A13";
BA_ "SeToolOwnerSigGroup_SIGNAL" SG_ 2348814091 TSC1EMSrABS_OvrdCtrlMPr "TSC1EMSrABS";
BA_ "SeToolVersion_SIGNAL" SG_ 2348814091 TSC1EMSrABS_OvrdCtrlMPr "1";
BA_ "GenSigSendType" SG_ 2348814091 TSC1EMSrABS_EnOvrdCtrlM 6;
BA_ "Platform_VMCU1_Sig" SG_ 2348814091 TSC1EMSrABS_EnOvrdCtrlM 1;
BA_ "SPN" SG_ 2348814091 TSC1EMSrABS_EnOvrdCtrlM 695;
BA_ "SeToolAncestorID_SIGNAL" SG_ 2348814091 TSC1EMSrABS_EnOvrdCtrlM "x0000001D042564C7";
BA_ "SeToolItemID_SIGNAL" SG_ 2348814091 TSC1EMSrABS_EnOvrdCtrlM "x0000001D042564C7";
BA_ "SeToolName_SIGNAL" SG_ 2348814091 TSC1EMSrABS_EnOvrdCtrlM "EnOvrdCtrlM";
BA_ "SeToolOwnerSigGroupID_SIGNAL" SG_ 2348814091 TSC1EMSrABS_EnOvrdCtrlM "x0000001D043D6A13";
BA_ "SeToolOwnerSigGroup_SIGNAL" SG_ 2348814091 TSC1EMSrABS_EnOvrdCtrlM "TSC1EMSrABS";
BA_ "SeToolVersion_SIGNAL" SG_ 2348814091 TSC1EMSrABS_EnOvrdCtrlM "1";
BA_ "GenSigSendType" SG_ 2348814091 TSC1EMSrABS_EnRSpdSpdLm 7;
BA_ "GenSigCycleTime" SG_ 2348814091 TSC1EMSrABS_EnRSpdSpdLm 100;
BA_ "GenSigCycleTimeActive" SG_ 2348814091 TSC1EMSrABS_EnRSpdSpdLm 100;
BA_ "GenSigStartValue" SG_ 2348814091 TSC1EMSrABS_EnRSpdSpdLm 65535;
BA_ "Platform_VMCU1_Sig" SG_ 2348814091 TSC1EMSrABS_EnRSpdSpdLm 1;
BA_ "SPN" SG_ 2348814091 TSC1EMSrABS_EnRSpdSpdLm 898;
BA_ "SeToolAncestorID_SIGNAL" SG_ 2348814091 TSC1EMSrABS_EnRSpdSpdLm "x0000001D042564D1";
BA_ "SeToolItemID_SIGNAL" SG_ 2348814091 TSC1EMSrABS_EnRSpdSpdLm "x0000001D042564D1";
BA_ "SeToolName_SIGNAL" SG_ 2348814091 TSC1EMSrABS_EnRSpdSpdLm "EnRSpdSpdLm";
BA_ "SeToolOwnerSigGroupID_SIGNAL" SG_ 2348814091 TSC1EMSrABS_EnRSpdSpdLm "x0000001D043D6A13";
BA_ "SeToolOwnerSigGroup_SIGNAL" SG_ 2348814091 TSC1EMSrABS_EnRSpdSpdLm "TSC1EMSrABS";
BA_ "SeToolVersion_SIGNAL" SG_ 2348814091 TSC1EMSrABS_EnRSpdSpdLm "1";
BA_ "GenSigCycleTime" SG_ 2566846467 TransmissionOilTemp_ISig_3 100;
BA_ "GenSigCycleTimeActive" SG_ 2566846467 TransmissionOilTemp_ISig_3 100;
BA_ "GenSigStartValue" SG_ 2566846467 TransmissionOilTemp_ISig_3 65535;
BA_ "Platform_VMCU1_Sig" SG_ 2566846467 TransmissionOilTemp_ISig_3 1;
BA_ "SPN" SG_ 2566846467 TransmissionOilTemp_ISig_3 177;
BA_ "SeToolAncestorID_SIGNAL" SG_ 2566846467 TransmissionOilTemp_ISig_3 "x0000001D04131792";
BA_ "SeToolItemID_SIGNAL" SG_ 2566846467 TransmissionOilTemp_ISig_3 "x0000001D04131792";
BA_ "SeToolName_SIGNAL" SG_ 2566846467 TransmissionOilTemp_ISig_3 "TransmissionOilTemp";
BA_ "SeToolVersion_SIGNAL" SG_ 2566846467 TransmissionOilTemp_ISig_3 "1";
BA_ "GenSigCycleTime" SG_ 2566846467 TransmissionOilLevel 100;
BA_ "GenSigCycleTimeActive" SG_ 2566846467 TransmissionOilLevel 100;
BA_ "GenSigStartValue" SG_ 2566846467 TransmissionOilLevel 255;
BA_ "Platform_VMCU1_Sig" SG_ 2566846467 TransmissionOilLevel 1;
BA_ "SPN" SG_ 2566846467 TransmissionOilLevel 124;
BA_ "GenSigSendType" SG_ 2565603075 TPDT_SeqNo_TECU 7;
BA_ "Platform_VMCU1_Sig" SG_ 2565603075 TPDT_SeqNo_TECU 1;
BA_ "GenSigSendType" SG_ 2565603310 TPDT_SeqNo_TACHO 7;
BA_ "Platform_VMCU1_Sig" SG_ 2565603310 TPDT_SeqNo_TACHO 1;
BA_ "GenSigSendType" SG_ 2565603088 TPDT_SeqNo_RECU 7;
BA_ "Platform_VMCU1_Sig" SG_ 2565603088 TPDT_SeqNo_RECU 1;
BA_ "GenSigSendType" SG_ 2565603087 TPDT_SeqNo_EMSRet 7;
BA_ "Platform_VMCU1_Sig" SG_ 2565603087 TPDT_SeqNo_EMSRet 1;
BA_ "GenSigSendType" SG_ 2565603072 TPDT_SeqNo_EMS 7;
BA_ "Platform_VMCU1_Sig" SG_ 2565603072 TPDT_SeqNo_EMS 1;
BA_ "GenSigSendType" SG_ 2565603083 TPDT_SeqNo_EBS 7;
BA_ "GenSigSendType" SG_ 2565603133 TPDT_SeqNo_ACM 7;
BA_ "Platform_VMCU1_Sig" SG_ 2565603133 TPDT_SeqNo_ACM 1;
BA_ "GenSigSendType" SG_ 2565598737 TPDT_SeqNo_TACHO_VMCU 7;
BA_ "GenSigSendType" SG_ 2565668611 TPCM_ControlByte_TECU 7;
BA_ "Platform_VMCU1_Sig" SG_ 2565668611 TPCM_ControlByte_TECU 1;
BA_ "GenSigSendType" SG_ 2565668846 TPCM_ControlByte_TACHO 7;
BA_ "Platform_VMCU1_Sig" SG_ 2565668846 TPCM_ControlByte_TACHO 1;
BA_ "GenSigSendType" SG_ 2565668624 TPCM_ControlByte_RECU 7;
BA_ "Platform_VMCU1_Sig" SG_ 2565668624 TPCM_ControlByte_RECU 1;
BA_ "GenSigSendType" SG_ 2565668623 TPCM_ControlByte_EMSRet 7;
BA_ "Platform_VMCU1_Sig" SG_ 2565668623 TPCM_ControlByte_EMSRet 1;
BA_ "GenSigSendType" SG_ 2565668608 TPCM_ControlByte_EMS 7;
BA_ "Platform_VMCU1_Sig" SG_ 2565668608 TPCM_ControlByte_EMS 1;
BA_ "GenSigSendType" SG_ 2565668619 TPCM_ControlByte_EBS 7;
BA_ "GenSigSendType" SG_ 2565668669 TPCM_ControlByte_ACM 7;
BA_ "Platform_VMCU1_Sig" SG_ 2565668669 TPCM_ControlByte_ACM 1;
BA_ "GenSigSendType" SG_ 2565607918 TPCM_ControlByte_VMCU_TACHO 7;
BA_ "GenSigSendType" SG_ 2565664273 TPCM_ControlByte_TACHO_VMCU 7;
BA_ "GenSigCycleTime" SG_ 2566882307 TransmissionGCVW_ISig_3 100;
BA_ "GenSigCycleTimeActive" SG_ 2566882307 TransmissionGCVW_ISig_3 100;
BA_ "GenSigStartValue" SG_ 2566882307 TransmissionGCVW_ISig_3 255;
BA_ "Platform_VMCU1_Sig" SG_ 2566882307 TransmissionGCVW_ISig_3 1;
BA_ "GenSigCycleTime" SG_ 2566882307 RawRoadInclination 100;
BA_ "GenSigCycleTimeActive" SG_ 2566882307 RawRoadInclination 100;
BA_ "GenSigStartValue" SG_ 2566882307 RawRoadInclination 255;
BA_ "GenSigCycleTime" SG_ 2566882307 LowTempClutchInfo 100;
BA_ "GenSigCycleTimeActive" SG_ 2566882307 LowTempClutchInfo 100;
BA_ "GenSigStartValue" SG_ 2566882307 LowTempClutchInfo 3;
BA_ "GenSigCycleTime" SG_ 2566882307 PermittedHSAPressure 100;
BA_ "GenSigCycleTimeActive" SG_ 2566882307 PermittedHSAPressure 100;
BA_ "GenSigStartValue" SG_ 2566882307 PermittedHSAPressure 255;
BA_ "GenSigMaxLatency" SG_ 2566882307 PermittedHSAPressure 110;
BA_ "Platform_VMCU1_Sig" SG_ 2566882307 PermittedHSAPressure 1;
BA_ "SeToolAncestorID_SIGNAL" SG_ 2566882307 PermittedHSAPressure "x0000001D0410CF7A";
BA_ "SeToolItemID_SIGNAL" SG_ 2566882307 PermittedHSAPressure "x0000001D0435749F";
BA_ "SeToolName_SIGNAL" SG_ 2566882307 PermittedHSAPressure "PermittedHSAPressure";
BA_ "SeToolVersion_SIGNAL" SG_ 2566882307 PermittedHSAPressure "2";
BA_ "GenSigCycleTime" SG_ 2566882307 TransmEngineCrankEnable_ISig_3 100;
BA_ "GenSigCycleTimeActive" SG_ 2566882307 TransmEngineCrankEnable_ISig_3 100;
BA_ "GenSigStartValue" SG_ 2566882307 TransmEngineCrankEnable_ISig_3 3;
BA_ "Platform_VMCU1_Sig" SG_ 2566882307 TransmEngineCrankEnable_ISig_3 1;
BA_ "SeToolAncestorID_SIGNAL" SG_ 2566882307 TransmEngineCrankEnable_ISig_3 "x0000001D041FEE2F";
BA_ "SeToolItemID_SIGNAL" SG_ 2566882307 TransmEngineCrankEnable_ISig_3 "x0000001D041FEE2F";
BA_ "SeToolName_SIGNAL" SG_ 2566882307 TransmEngineCrankEnable_ISig_3 "TransmEngineCrankEnable";
BA_ "SeToolVersion_SIGNAL" SG_ 2566882307 TransmEngineCrankEnable_ISig_3 "1";
BA_ "GenSigCycleTime" SG_ 2566841879 MonthUTC_ISig_3 100;
BA_ "GenSigCycleTimeActive" SG_ 2566841879 MonthUTC_ISig_3 100;
BA_ "GenSigStartValue" SG_ 2566841879 MonthUTC_ISig_3 255;
BA_ "Platform_FactoryIf_Sig" SG_ 2566841879 MonthUTC_ISig_3 1;
BA_ "Platform_VMCU1_Sig" SG_ 2566841879 MonthUTC_ISig_3 1;
BA_ "SPN" SG_ 2566841879 MonthUTC_ISig_3 963;
BA_ "SeToolAncestorID_SIGNAL" SG_ 2566841879 MonthUTC_ISig_3 "x0000001D0412FAC9";
BA_ "SeToolItemID_SIGNAL" SG_ 2566841879 MonthUTC_ISig_3 "x0000001D041EBD16";
BA_ "SeToolName_SIGNAL" SG_ 2566841879 MonthUTC_ISig_3 "MonthUTC";
BA_ "SeToolVersion_SIGNAL" SG_ 2566841879 MonthUTC_ISig_3 "2";
BA_ "GenSigCycleTime" SG_ 2566841879 SelectedLocalHourOffset_ISig_3 100;
BA_ "GenSigCycleTimeActive" SG_ 2566841879 SelectedLocalHourOffset_ISig_3 100;
BA_ "GenSigStartValue" SG_ 2566841879 SelectedLocalHourOffset_ISig_3 255;
BA_ "SPN" SG_ 2566841879 SelectedLocalHourOffset_ISig_3 1602;
BA_ "GenSigCycleTime" SG_ 2566841879 SecondsUTC_ISig_3 100;
BA_ "GenSigCycleTimeActive" SG_ 2566841879 SecondsUTC_ISig_3 100;
BA_ "GenSigStartValue" SG_ 2566841879 SecondsUTC_ISig_3 255;
BA_ "Platform_FactoryIf_Sig" SG_ 2566841879 SecondsUTC_ISig_3 1;
BA_ "Platform_VMCU1_Sig" SG_ 2566841879 SecondsUTC_ISig_3 1;
BA_ "SPN" SG_ 2566841879 SecondsUTC_ISig_3 959;
BA_ "SeToolAncestorID_SIGNAL" SG_ 2566841879 SecondsUTC_ISig_3 "x0000001D0412FABE";
BA_ "SeToolItemID_SIGNAL" SG_ 2566841879 SecondsUTC_ISig_3 "x0000001D041EBD32";
BA_ "SeToolName_SIGNAL" SG_ 2566841879 SecondsUTC_ISig_3 "SecondsUTC";
BA_ "SeToolVersion_SIGNAL" SG_ 2566841879 SecondsUTC_ISig_3 "2";
BA_ "GenSigCycleTime" SG_ 2566841879 SelectedLocalMinuteOffset_ISig_3 100;
BA_ "GenSigCycleTimeActive" SG_ 2566841879 SelectedLocalMinuteOffset_ISig_3 100;
BA_ "GenSigStartValue" SG_ 2566841879 SelectedLocalMinuteOffset_ISig_3 255;
BA_ "SPN" SG_ 2566841879 SelectedLocalMinuteOffset_ISig_3 1601;
BA_ "GenSigCycleTime" SG_ 2566841879 HoursUTC_ISig_3 100;
BA_ "GenSigCycleTimeActive" SG_ 2566841879 HoursUTC_ISig_3 100;
BA_ "GenSigStartValue" SG_ 2566841879 HoursUTC_ISig_3 255;
BA_ "Platform_FactoryIf_Sig" SG_ 2566841879 HoursUTC_ISig_3 1;
BA_ "Platform_VMCU1_Sig" SG_ 2566841879 HoursUTC_ISig_3 1;
BA_ "SPN" SG_ 2566841879 HoursUTC_ISig_3 961;
BA_ "SeToolAncestorID_SIGNAL" SG_ 2566841879 HoursUTC_ISig_3 "x0000001D0412FAC2";
BA_ "SeToolItemID_SIGNAL" SG_ 2566841879 HoursUTC_ISig_3 "x0000001D041EBD20";
BA_ "SeToolName_SIGNAL" SG_ 2566841879 HoursUTC_ISig_3 "HoursUTC";
BA_ "SeToolVersion_SIGNAL" SG_ 2566841879 HoursUTC_ISig_3 "2";
BA_ "GenSigCycleTime" SG_ 2566841879 YearUTC_ISig_3 100;
BA_ "GenSigCycleTimeActive" SG_ 2566841879 YearUTC_ISig_3 100;
BA_ "GenSigStartValue" SG_ 2566841879 YearUTC_ISig_3 255;
BA_ "Platform_FactoryIf_Sig" SG_ 2566841879 YearUTC_ISig_3 1;
BA_ "Platform_VMCU1_Sig" SG_ 2566841879 YearUTC_ISig_3 1;
BA_ "SPN" SG_ 2566841879 YearUTC_ISig_3 964;
BA_ "SeToolAncestorID_SIGNAL" SG_ 2566841879 YearUTC_ISig_3 "x0000001D0412FACB";
BA_ "SeToolItemID_SIGNAL" SG_ 2566841879 YearUTC_ISig_3 "x0000001D041EBCEF";
BA_ "SeToolName_SIGNAL" SG_ 2566841879 YearUTC_ISig_3 "YearUTC";
BA_ "SeToolVersion_SIGNAL" SG_ 2566841879 YearUTC_ISig_3 "2";
BA_ "GenSigCycleTime" SG_ 2566841879 DayUTC_ISig_3 100;
BA_ "GenSigCycleTimeActive" SG_ 2566841879 DayUTC_ISig_3 100;
BA_ "GenSigStartValue" SG_ 2566841879 DayUTC_ISig_3 255;
BA_ "Platform_FactoryIf_Sig" SG_ 2566841879 DayUTC_ISig_3 1;
BA_ "Platform_VMCU1_Sig" SG_ 2566841879 DayUTC_ISig_3 1;
BA_ "SPN" SG_ 2566841879 DayUTC_ISig_3 962;
BA_ "SeToolAncestorID_SIGNAL" SG_ 2566841879 DayUTC_ISig_3 "x0000001D0412FAC4";
BA_ "SeToolItemID_SIGNAL" SG_ 2566841879 DayUTC_ISig_3 "x0000001D041EBD81";
BA_ "SeToolName_SIGNAL" SG_ 2566841879 DayUTC_ISig_3 "DayUTC";
BA_ "SeToolVersion_SIGNAL" SG_ 2566841879 DayUTC_ISig_3 "2";
BA_ "GenSigCycleTime" SG_ 2566841879 MinutesUTC_ISig_3 100;
BA_ "GenSigCycleTimeActive" SG_ 2566841879 MinutesUTC_ISig_3 100;
BA_ "GenSigStartValue" SG_ 2566841879 MinutesUTC_ISig_3 255;
BA_ "Platform_FactoryIf_Sig" SG_ 2566841879 MinutesUTC_ISig_3 1;
BA_ "Platform_VMCU1_Sig" SG_ 2566841879 MinutesUTC_ISig_3 1;
BA_ "SPN" SG_ 2566841879 MinutesUTC_ISig_3 960;
BA_ "SeToolAncestorID_SIGNAL" SG_ 2566841879 MinutesUTC_ISig_3 "x0000001D0412FAC0";
BA_ "SeToolItemID_SIGNAL" SG_ 2566841879 MinutesUTC_ISig_3 "x0000001D041EBD29";
BA_ "SeToolName_SIGNAL" SG_ 2566841879 MinutesUTC_ISig_3 "MinutesUTC";
BA_ "SeToolVersion_SIGNAL" SG_ 2566841879 MinutesUTC_ISig_3 "2";
BA_ "GenSigCycleTime" SG_ 2566842094 TachographLocalMinuteOffset_ISig 100;
BA_ "GenSigCycleTimeActive" SG_ 2566842094 TachographLocalMinuteOffset_ISig 100;
BA_ "GenSigStartValue" SG_ 2566842094 TachographLocalMinuteOffset_ISig 255;
BA_ "Platform_VMCU1_Sig" SG_ 2566842094 TachographLocalMinuteOffset_ISig 1;
BA_ "SPN" SG_ 2566842094 TachographLocalMinuteOffset_ISig 1601;
BA_ "SystemSignalLongSymbol" SG_ 2566842094 TachographLocalMinuteOffset_ISig "TachographLocalMinuteOffset_ISig_3";
BA_ "GenSigCycleTime" SG_ 2566842094 TachographMinutes 100;
BA_ "GenSigCycleTimeActive" SG_ 2566842094 TachographMinutes 100;
BA_ "GenSigStartValue" SG_ 2566842094 TachographMinutes 255;
BA_ "Platform_VMCU1_Sig" SG_ 2566842094 TachographMinutes 1;
BA_ "SPN" SG_ 2566842094 TachographMinutes 960;
BA_ "GenSigCycleTime" SG_ 2566842094 TachographYears 100;
BA_ "GenSigCycleTimeActive" SG_ 2566842094 TachographYears 100;
BA_ "GenSigStartValue" SG_ 2566842094 TachographYears 255;
BA_ "Platform_VMCU1_Sig" SG_ 2566842094 TachographYears 1;
BA_ "SPN" SG_ 2566842094 TachographYears 964;
BA_ "SeToolAncestorID_SIGNAL" SG_ 2566842094 TachographYears "x0000001D0419B88C";
BA_ "SeToolItemID_SIGNAL" SG_ 2566842094 TachographYears "x0000001D0419B88C";
BA_ "SeToolName_SIGNAL" SG_ 2566842094 TachographYears "TachographYears";
BA_ "SeToolVersion_SIGNAL" SG_ 2566842094 TachographYears "1";
BA_ "GenSigCycleTime" SG_ 2566842094 TachographSeconds 100;
BA_ "GenSigCycleTimeActive" SG_ 2566842094 TachographSeconds 100;
BA_ "GenSigStartValue" SG_ 2566842094 TachographSeconds 255;
BA_ "Platform_VMCU1_Sig" SG_ 2566842094 TachographSeconds 1;
BA_ "SPN" SG_ 2566842094 TachographSeconds 959;
BA_ "GenSigCycleTime" SG_ 2566842094 TachographHours 100;
BA_ "GenSigCycleTimeActive" SG_ 2566842094 TachographHours 100;
BA_ "GenSigStartValue" SG_ 2566842094 TachographHours 255;
BA_ "Platform_VMCU1_Sig" SG_ 2566842094 TachographHours 1;
BA_ "SPN" SG_ 2566842094 TachographHours 961;
BA_ "GenSigCycleTime" SG_ 2566842094 TachographMonths 100;
BA_ "GenSigCycleTimeActive" SG_ 2566842094 TachographMonths 100;
BA_ "GenSigStartValue" SG_ 2566842094 TachographMonths 255;
BA_ "Platform_VMCU1_Sig" SG_ 2566842094 TachographMonths 1;
BA_ "SPN" SG_ 2566842094 TachographMonths 963;
BA_ "SeToolAncestorID_SIGNAL" SG_ 2566842094 TachographMonths "x0000001D0419B85C";
BA_ "SeToolItemID_SIGNAL" SG_ 2566842094 TachographMonths "x0000001D0419B85C";
BA_ "SeToolName_SIGNAL" SG_ 2566842094 TachographMonths "TachographMonths";
BA_ "SeToolVersion_SIGNAL" SG_ 2566842094 TachographMonths "1";
BA_ "GenSigCycleTime" SG_ 2566842094 TachographLocalHourOffset_ISig_3 100;
BA_ "GenSigCycleTimeActive" SG_ 2566842094 TachographLocalHourOffset_ISig_3 100;
BA_ "GenSigStartValue" SG_ 2566842094 TachographLocalHourOffset_ISig_3 255;
BA_ "Platform_VMCU1_Sig" SG_ 2566842094 TachographLocalHourOffset_ISig_3 1;
BA_ "SPN" SG_ 2566842094 TachographLocalHourOffset_ISig_3 1602;
BA_ "GenSigCycleTime" SG_ 2566842094 TachographDays 100;
BA_ "GenSigCycleTimeActive" SG_ 2566842094 TachographDays 100;
BA_ "GenSigStartValue" SG_ 2566842094 TachographDays 255;
BA_ "Platform_VMCU1_Sig" SG_ 2566842094 TachographDays 1;
BA_ "SPN" SG_ 2566842094 TachographDays 962;
BA_ "SeToolAncestorID_SIGNAL" SG_ 2566842094 TachographDays "x0000001D0419B848";
BA_ "SeToolItemID_SIGNAL" SG_ 2566842094 TachographDays "x0000001D0419B848";
BA_ "SeToolName_SIGNAL" SG_ 2566842094 TachographDays "TachographDays";
BA_ "SeToolVersion_SIGNAL" SG_ 2566842094 TachographDays "1";
BA_ "GenSigSendType" SG_ 2564156951 AdjustLocalMinuteOffset 1;
BA_ "GenSigStartValue" SG_ 2564156951 AdjustLocalMinuteOffset 255;
BA_ "Platform_VMCU1_Sig" SG_ 2564156951 AdjustLocalMinuteOffset 1;
BA_ "SPN" SG_ 2564156951 AdjustLocalMinuteOffset 1609;
BA_ "GenSigSendType" SG_ 2564156951 AdjustLocalHourOffset 1;
BA_ "GenSigStartValue" SG_ 2564156951 AdjustLocalHourOffset 255;
BA_ "Platform_VMCU1_Sig" SG_ 2564156951 AdjustLocalHourOffset 1;
BA_ "SPN" SG_ 2564156951 AdjustLocalHourOffset 1610;
BA_ "GenSigCycleTime" SG_ 2365484270 Driver2TimeRelatedStates_ISig_3 100;
BA_ "GenSigCycleTimeActive" SG_ 2365484270 Driver2TimeRelatedStates_ISig_3 100;
BA_ "GenSigStartValue" SG_ 2365484270 Driver2TimeRelatedStates_ISig_3 15;
BA_ "Platform_VMCU1_Sig" SG_ 2365484270 Driver2TimeRelatedStates_ISig_3 1;
BA_ "SPN" SG_ 2365484270 Driver2TimeRelatedStates_ISig_3 1618;
BA_ "GenSigCycleTime" SG_ 2365484270 VehicleMotion_ISig_3 100;
BA_ "GenSigCycleTimeActive" SG_ 2365484270 VehicleMotion_ISig_3 100;
BA_ "GenSigStartValue" SG_ 2365484270 VehicleMotion_ISig_3 3;
BA_ "Platform_VMCU1_Sig" SG_ 2365484270 VehicleMotion_ISig_3 1;
BA_ "SPN" SG_ 2365484270 VehicleMotion_ISig_3 1611;
BA_ "GenSigCycleTime" SG_ 2365484270 TachographVehicleSpeed_ISig_3 100;
BA_ "GenSigCycleTimeActive" SG_ 2365484270 TachographVehicleSpeed_ISig_3 100;
BA_ "GenSigStartValue" SG_ 2365484270 TachographVehicleSpeed_ISig_3 65535;
BA_ "Platform_VMCU1_Sig" SG_ 2365484270 TachographVehicleSpeed_ISig_3 1;
BA_ "SPN" SG_ 2365484270 TachographVehicleSpeed_ISig_3 1624;
BA_ "SeToolAncestorID_SIGNAL" SG_ 2365484270 TachographVehicleSpeed_ISig_3 "x0000001D0414CAF5";
BA_ "SeToolItemID_SIGNAL" SG_ 2365484270 TachographVehicleSpeed_ISig_3 "x0000001D0414CAF5";
BA_ "SeToolName_SIGNAL" SG_ 2365484270 TachographVehicleSpeed_ISig_3 "TachographVehicleSpeed";
BA_ "SeToolVersion_SIGNAL" SG_ 2365484270 TachographVehicleSpeed_ISig_3 "1";
BA_ "GenSigCycleTime" SG_ 2365484270 TachographPerformance_ISig_3 100;
BA_ "GenSigCycleTimeActive" SG_ 2365484270 TachographPerformance_ISig_3 100;
BA_ "GenSigStartValue" SG_ 2365484270 TachographPerformance_ISig_3 3;
BA_ "Platform_VMCU1_Sig" SG_ 2365484270 TachographPerformance_ISig_3 1;
BA_ "SPN" SG_ 2365484270 TachographPerformance_ISig_3 1620;
BA_ "GenSigCycleTime" SG_ 2365484270 Driver1WorkingState_ISig_3 100;
BA_ "GenSigCycleTimeActive" SG_ 2365484270 Driver1WorkingState_ISig_3 100;
BA_ "GenSigStartValue" SG_ 2365484270 Driver1WorkingState_ISig_3 7;
BA_ "Platform_VMCU1_Sig" SG_ 2365484270 Driver1WorkingState_ISig_3 1;
BA_ "SPN" SG_ 2365484270 Driver1WorkingState_ISig_3 1612;
BA_ "SeToolAncestorID_SIGNAL" SG_ 2365484270 Driver1WorkingState_ISig_3 "x0000001D0417BE44";
BA_ "SeToolItemID_SIGNAL" SG_ 2365484270 Driver1WorkingState_ISig_3 "x0000001D0417BE44";
BA_ "SeToolName_SIGNAL" SG_ 2365484270 Driver1WorkingState_ISig_3 "Driver1WorkingState";
BA_ "SeToolVersion_SIGNAL" SG_ 2365484270 Driver1WorkingState_ISig_3 "1";
BA_ "GenSigCycleTime" SG_ 2365484270 Driver1TimeRelatedStates_ISig_3 100;
BA_ "GenSigCycleTimeActive" SG_ 2365484270 Driver1TimeRelatedStates_ISig_3 100;
BA_ "GenSigStartValue" SG_ 2365484270 Driver1TimeRelatedStates_ISig_3 15;
BA_ "Platform_VMCU1_Sig" SG_ 2365484270 Driver1TimeRelatedStates_ISig_3 1;
BA_ "SPN" SG_ 2365484270 Driver1TimeRelatedStates_ISig_3 1617;
BA_ "SeToolAncestorID_SIGNAL" SG_ 2365484270 Driver1TimeRelatedStates_ISig_3 "x0000001D0417BECF";
BA_ "SeToolItemID_SIGNAL" SG_ 2365484270 Driver1TimeRelatedStates_ISig_3 "x0000001D0417BECF";
BA_ "SeToolName_SIGNAL" SG_ 2365484270 Driver1TimeRelatedStates_ISig_3 "Driver1TimeRelatedStates";
BA_ "SeToolVersion_SIGNAL" SG_ 2365484270 Driver1TimeRelatedStates_ISig_3 "1";
BA_ "GenSigCycleTime" SG_ 2365484270 DriverCardDriver2_ISig_3 100;
BA_ "GenSigCycleTimeActive" SG_ 2365484270 DriverCardDriver2_ISig_3 100;
BA_ "GenSigStartValue" SG_ 2365484270 DriverCardDriver2_ISig_3 3;
BA_ "Platform_VMCU1_Sig" SG_ 2365484270 DriverCardDriver2_ISig_3 1;
BA_ "SPN" SG_ 2365484270 DriverCardDriver2_ISig_3 1616;
BA_ "GenSigCycleTime" SG_ 2365484270 TachographOutputShaftSpeed_ISig_ 100;
BA_ "GenSigCycleTimeActive" SG_ 2365484270 TachographOutputShaftSpeed_ISig_ 100;
BA_ "GenSigStartValue" SG_ 2365484270 TachographOutputShaftSpeed_ISig_ 65535;
BA_ "Platform_VMCU1_Sig" SG_ 2365484270 TachographOutputShaftSpeed_ISig_ 1;
BA_ "SPN" SG_ 2365484270 TachographOutputShaftSpeed_ISig_ 1623;
BA_ "SeToolAncestorID_SIGNAL" SG_ 2365484270 TachographOutputShaftSpeed_ISig_ "x0000001D041285E8";
BA_ "SeToolItemID_SIGNAL" SG_ 2365484270 TachographOutputShaftSpeed_ISig_ "x0000001D041285E8";
BA_ "SeToolName_SIGNAL" SG_ 2365484270 TachographOutputShaftSpeed_ISig_ "TachographOutputShaftSpeed";
BA_ "SeToolVersion_SIGNAL" SG_ 2365484270 TachographOutputShaftSpeed_ISig_ "1";
BA_ "SystemSignalLongSymbol" SG_ 2365484270 TachographOutputShaftSpeed_ISig_ "TachographOutputShaftSpeed_ISig_3";
BA_ "GenSigCycleTime" SG_ 2365484270 HandlingInformation_ISig_3 100;
BA_ "GenSigCycleTimeActive" SG_ 2365484270 HandlingInformation_ISig_3 100;
BA_ "GenSigStartValue" SG_ 2365484270 HandlingInformation_ISig_3 3;
BA_ "Platform_VMCU1_Sig" SG_ 2365484270 HandlingInformation_ISig_3 1;
BA_ "SPN" SG_ 2365484270 HandlingInformation_ISig_3 1621;
BA_ "GenSigCycleTime" SG_ 2365484270 DriverCardDriver1_ISig_3 100;
BA_ "GenSigCycleTimeActive" SG_ 2365484270 DriverCardDriver1_ISig_3 100;
BA_ "GenSigStartValue" SG_ 2365484270 DriverCardDriver1_ISig_3 3;
BA_ "Platform_VMCU1_Sig" SG_ 2365484270 DriverCardDriver1_ISig_3 1;
BA_ "SPN" SG_ 2365484270 DriverCardDriver1_ISig_3 1615;
BA_ "GenSigCycleTime" SG_ 2365484270 SystemEvent_ISig_3 100;
BA_ "GenSigCycleTimeActive" SG_ 2365484270 SystemEvent_ISig_3 100;
BA_ "GenSigStartValue" SG_ 2365484270 SystemEvent_ISig_3 3;
BA_ "Platform_VMCU1_Sig" SG_ 2365484270 SystemEvent_ISig_3 1;
BA_ "SPN" SG_ 2365484270 SystemEvent_ISig_3 1622;
BA_ "GenSigCycleTime" SG_ 2365484270 VehicleOverspeed_ISig_3 100;
BA_ "GenSigCycleTimeActive" SG_ 2365484270 VehicleOverspeed_ISig_3 100;
BA_ "GenSigStartValue" SG_ 2365484270 VehicleOverspeed_ISig_3 3;
BA_ "Platform_VMCU1_Sig" SG_ 2365484270 VehicleOverspeed_ISig_3 1;
BA_ "SPN" SG_ 2365484270 VehicleOverspeed_ISig_3 1614;
BA_ "SeToolAncestorID_SIGNAL" SG_ 2365484270 VehicleOverspeed_ISig_3 "x0000001D0417BEBB";
BA_ "SeToolItemID_SIGNAL" SG_ 2365484270 VehicleOverspeed_ISig_3 "x0000001D0417BEBB";
BA_ "SeToolName_SIGNAL" SG_ 2365484270 VehicleOverspeed_ISig_3 "VehicleOverspeed";
BA_ "SeToolVersion_SIGNAL" SG_ 2365484270 VehicleOverspeed_ISig_3 "1";
BA_ "GenSigCycleTime" SG_ 2365484270 Driver2WorkingState_ISig_3 100;
BA_ "GenSigCycleTimeActive" SG_ 2365484270 Driver2WorkingState_ISig_3 100;
BA_ "GenSigStartValue" SG_ 2365484270 Driver2WorkingState_ISig_3 7;
BA_ "Platform_VMCU1_Sig" SG_ 2365484270 Driver2WorkingState_ISig_3 1;
BA_ "SPN" SG_ 2365484270 Driver2WorkingState_ISig_3 1613;
BA_ "SeToolAncestorID_SIGNAL" SG_ 2365484270 Driver2WorkingState_ISig_3 "x0000001D0417BEAC";
BA_ "SeToolItemID_SIGNAL" SG_ 2365484270 Driver2WorkingState_ISig_3 "x0000001D0417BEAC";
BA_ "SeToolName_SIGNAL" SG_ 2365484270 Driver2WorkingState_ISig_3 "Driver2WorkingState";
BA_ "SeToolVersion_SIGNAL" SG_ 2365484270 Driver2WorkingState_ISig_3 "1";
BA_ "GenSigCycleTime" SG_ 2565533233 PGNReq_Tacho_CIOM 100;
BA_ "GenSigCycleTimeActive" SG_ 2565533233 PGNReq_Tacho_CIOM 100;
BA_ "GenSigStartValue" SG_ 2565533233 PGNReq_Tacho_CIOM 65131;
BA_ "Platform_VMCU1_Sig" SG_ 2565533233 PGNReq_Tacho_CIOM 1;
BA_ "GenSigCycleTime" SG_ 2499792656 DrivelineRetarderStat 100;
BA_ "GenSigCycleTimeActive" SG_ 2499792656 DrivelineRetarderStat 100;
BA_ "GenSigStartValue" SG_ 2499792656 DrivelineRetarderStat 3;
BA_ "GenSigMaxLatency" SG_ 2499792656 DrivelineRetarderStat 100;
BA_ "Platform_VMCU1_Sig" SG_ 2499792656 DrivelineRetarderStat 1;
BA_ "GenSigSendType" SG_ 2566840592 DrivelineRetarderRefTorque 3;
BA_ "GenSigCycleTime" SG_ 2566840592 DrivelineRetarderRefTorque 100;
BA_ "GenSigCycleTimeActive" SG_ 2566840592 DrivelineRetarderRefTorque 100;
BA_ "GenSigStartValue" SG_ 2566840592 DrivelineRetarderRefTorque 65535;
BA_ "Platform_VMCU1_Sig" SG_ 2566840592 DrivelineRetarderRefTorque 1;
BA_ "SPN" SG_ 2566840592 DrivelineRetarderRefTorque 556;
BA_ "SeToolAncestorID_SIGNAL" SG_ 2566840592 DrivelineRetarderRefTorque "x0000001D041286D2";
BA_ "SeToolItemID_SIGNAL" SG_ 2566840592 DrivelineRetarderRefTorque "x0000001D041286D2";
BA_ "SeToolName_SIGNAL" SG_ 2566840592 DrivelineRetarderRefTorque "ReferenceDrivelineRetarderTorque";
BA_ "SeToolVersion_SIGNAL" SG_ 2566840592 DrivelineRetarderRefTorque "1";
BA_ "GenSigSendType" SG_ 2566840592 DrivelineRetarderLocation 3;
BA_ "GenSigCycleTime" SG_ 2566840592 DrivelineRetarderLocation 100;
BA_ "GenSigCycleTimeActive" SG_ 2566840592 DrivelineRetarderLocation 100;
BA_ "GenSigStartValue" SG_ 2566840592 DrivelineRetarderLocation 15;
BA_ "Platform_VMCU1_Sig" SG_ 2566840592 DrivelineRetarderLocation 1;
BA_ "SPN" SG_ 2566840592 DrivelineRetarderLocation 902;
BA_ "GenSigSendType" SG_ 2566840592 DrivelineRetarderType 3;
BA_ "GenSigCycleTime" SG_ 2566840592 DrivelineRetarderType 100;
BA_ "GenSigCycleTimeActive" SG_ 2566840592 DrivelineRetarderType 100;
BA_ "GenSigStartValue" SG_ 2566840592 DrivelineRetarderType 15;
BA_ "Platform_VMCU1_Sig" SG_ 2566840592 DrivelineRetarderType 1;
BA_ "SPN" SG_ 2566840592 DrivelineRetarderType 901;
BA_ "GenSigSendType" SG_ 2566840591 EngRetConf_RetCtrlMethod 3;
BA_ "GenSigCycleTime" SG_ 2566840591 EngRetConf_RetCtrlMethod 100;
BA_ "GenSigCycleTimeActive" SG_ 2566840591 EngRetConf_RetCtrlMethod 100;
BA_ "GenSigStartValue" SG_ 2566840591 EngRetConf_RetCtrlMethod 255;
BA_ "Platform_VMCU1_Sig" SG_ 2566840591 EngRetConf_RetCtrlMethod 1;
BA_ "SPN" SG_ 2566840591 EngRetConf_RetCtrlMethod 557;
BA_ "SeToolAncestorID_SIGNAL" SG_ 2566840591 EngRetConf_RetCtrlMethod "x0000001D0431F119";
BA_ "SeToolItemID_SIGNAL" SG_ 2566840591 EngRetConf_RetCtrlMethod "x0000001D0431F119";
BA_ "SeToolName_SIGNAL" SG_ 2566840591 EngRetConf_RetCtrlMethod "EngRetConf_RetCtrlMethod";
BA_ "SeToolVersion_SIGNAL" SG_ 2566840591 EngRetConf_RetCtrlMethod "1";
BA_ "GenSigSendType" SG_ 2566840591 EngRetConf_RetSpeedAtP4 3;
BA_ "GenSigCycleTime" SG_ 2566840591 EngRetConf_RetSpeedAtP4 100;
BA_ "GenSigCycleTimeActive" SG_ 2566840591 EngRetConf_RetSpeedAtP4 100;
BA_ "GenSigStartValue" SG_ 2566840591 EngRetConf_RetSpeedAtP4 65535;
BA_ "Platform_VMCU1_Sig" SG_ 2566840591 EngRetConf_RetSpeedAtP4 1;
BA_ "SPN" SG_ 2566840591 EngRetConf_RetSpeedAtP4 550;
BA_ "SeToolAncestorID_SIGNAL" SG_ 2566840591 EngRetConf_RetSpeedAtP4 "x0000001D0431F0E0";
BA_ "SeToolItemID_SIGNAL" SG_ 2566840591 EngRetConf_RetSpeedAtP4 "x0000001D0431F0E0";
BA_ "SeToolName_SIGNAL" SG_ 2566840591 EngRetConf_RetSpeedAtP4 "EngRetConf_RetSpeedAtP4";
BA_ "SeToolVersion_SIGNAL" SG_ 2566840591 EngRetConf_RetSpeedAtP4 "1";
BA_ "GenSigSendType" SG_ 2566840591 EngRetConf_MaxRetSpeedP2 3;
BA_ "GenSigCycleTime" SG_ 2566840591 EngRetConf_MaxRetSpeedP2 100;
BA_ "GenSigCycleTimeActive" SG_ 2566840591 EngRetConf_MaxRetSpeedP2 100;
BA_ "GenSigStartValue" SG_ 2566840591 EngRetConf_MaxRetSpeedP2 65535;
BA_ "Platform_VMCU1_Sig" SG_ 2566840591 EngRetConf_MaxRetSpeedP2 1;
BA_ "SPN" SG_ 2566840591 EngRetConf_MaxRetSpeedP2 548;
BA_ "SeToolAncestorID_SIGNAL" SG_ 2566840591 EngRetConf_MaxRetSpeedP2 "x0000001D0431F0DC";
BA_ "SeToolItemID_SIGNAL" SG_ 2566840591 EngRetConf_MaxRetSpeedP2 "x0000001D0431F0DC";
BA_ "SeToolName_SIGNAL" SG_ 2566840591 EngRetConf_MaxRetSpeedP2 "EngRetConf_MaxRetSpeedP2";
BA_ "SeToolVersion_SIGNAL" SG_ 2566840591 EngRetConf_MaxRetSpeedP2 "1";
BA_ "GenSigSendType" SG_ 2566840591 EngRetConf_PerTrqAtP3 3;
BA_ "GenSigCycleTime" SG_ 2566840591 EngRetConf_PerTrqAtP3 100;
BA_ "GenSigCycleTimeActive" SG_ 2566840591 EngRetConf_PerTrqAtP3 100;
BA_ "GenSigStartValue" SG_ 2566840591 EngRetConf_PerTrqAtP3 255;
BA_ "Platform_VMCU1_Sig" SG_ 2566840591 EngRetConf_PerTrqAtP3 1;
BA_ "SPN" SG_ 2566840591 EngRetConf_PerTrqAtP3 553;
BA_ "SeToolAncestorID_SIGNAL" SG_ 2566840591 EngRetConf_PerTrqAtP3 "x0000001D0431F0E4";
BA_ "SeToolItemID_SIGNAL" SG_ 2566840591 EngRetConf_PerTrqAtP3 "x0000001D0431F0E4";
BA_ "SeToolName_SIGNAL" SG_ 2566840591 EngRetConf_PerTrqAtP3 "EngRetConf_PerTrqAtP3";
BA_ "SeToolVersion_SIGNAL" SG_ 2566840591 EngRetConf_PerTrqAtP3 "1";
BA_ "GenSigSendType" SG_ 2566840591 EngRetConf_RetSpeedAtP5 3;
BA_ "GenSigCycleTime" SG_ 2566840591 EngRetConf_RetSpeedAtP5 100;
BA_ "GenSigCycleTimeActive" SG_ 2566840591 EngRetConf_RetSpeedAtP5 100;
BA_ "GenSigStartValue" SG_ 2566840591 EngRetConf_RetSpeedAtP5 65535;
BA_ "Platform_VMCU1_Sig" SG_ 2566840591 EngRetConf_RetSpeedAtP5 1;
BA_ "SPN" SG_ 2566840591 EngRetConf_RetSpeedAtP5 547;
BA_ "SeToolAncestorID_SIGNAL" SG_ 2566840591 EngRetConf_RetSpeedAtP5 "x0000001D0431F107";
BA_ "SeToolItemID_SIGNAL" SG_ 2566840591 EngRetConf_RetSpeedAtP5 "x0000001D0431F107";
BA_ "SeToolName_SIGNAL" SG_ 2566840591 EngRetConf_RetSpeedAtP5 "EngRetConf_RetSpeedAtP5";
BA_ "SeToolVersion_SIGNAL" SG_ 2566840591 EngRetConf_RetSpeedAtP5 "1";
BA_ "GenSigSendType" SG_ 2566840591 EngRetConf_speedAtIdleP1 3;
BA_ "GenSigCycleTime" SG_ 2566840591 EngRetConf_speedAtIdleP1 100;
BA_ "GenSigCycleTimeActive" SG_ 2566840591 EngRetConf_speedAtIdleP1 100;
BA_ "GenSigStartValue" SG_ 2566840591 EngRetConf_speedAtIdleP1 65535;
BA_ "Platform_VMCU1_Sig" SG_ 2566840591 EngRetConf_speedAtIdleP1 1;
BA_ "SPN" SG_ 2566840591 EngRetConf_speedAtIdleP1 546;
BA_ "SeToolAncestorID_SIGNAL" SG_ 2566840591 EngRetConf_speedAtIdleP1 "x0000001D0431F0CB";
BA_ "SeToolItemID_SIGNAL" SG_ 2566840591 EngRetConf_speedAtIdleP1 "x0000001D0431F0CB";
BA_ "SeToolName_SIGNAL" SG_ 2566840591 EngRetConf_speedAtIdleP1 "EngRetConf_speedAtIdleP1";
BA_ "SeToolVersion_SIGNAL" SG_ 2566840591 EngRetConf_speedAtIdleP1 "1";
BA_ "GenSigSendType" SG_ 2566840591 EngRetConf_PerTrqAtP4 3;
BA_ "GenSigCycleTime" SG_ 2566840591 EngRetConf_PerTrqAtP4 100;
BA_ "GenSigCycleTimeActive" SG_ 2566840591 EngRetConf_PerTrqAtP4 100;
BA_ "GenSigStartValue" SG_ 2566840591 EngRetConf_PerTrqAtP4 255;
BA_ "Platform_VMCU1_Sig" SG_ 2566840591 EngRetConf_PerTrqAtP4 1;
BA_ "SPN" SG_ 2566840591 EngRetConf_PerTrqAtP4 554;
BA_ "SeToolAncestorID_SIGNAL" SG_ 2566840591 EngRetConf_PerTrqAtP4 "x0000001D0431F101";
BA_ "SeToolItemID_SIGNAL" SG_ 2566840591 EngRetConf_PerTrqAtP4 "x0000001D0431F101";
BA_ "SeToolName_SIGNAL" SG_ 2566840591 EngRetConf_PerTrqAtP4 "EngRetConf_PerTrqAtP4";
BA_ "SeToolVersion_SIGNAL" SG_ 2566840591 EngRetConf_PerTrqAtP4 "1";
BA_ "GenSigSendType" SG_ 2566840591 ReferenceEngineRetarderTorque 3;
BA_ "GenSigCycleTime" SG_ 2566840591 ReferenceEngineRetarderTorque 100;
BA_ "GenSigCycleTimeActive" SG_ 2566840591 ReferenceEngineRetarderTorque 100;
BA_ "GenSigStartValue" SG_ 2566840591 ReferenceEngineRetarderTorque 65535;
BA_ "Platform_VMCU1_Sig" SG_ 2566840591 ReferenceEngineRetarderTorque 1;
BA_ "SPN" SG_ 2566840591 ReferenceEngineRetarderTorque 556;
BA_ "SeToolAncestorID_SIGNAL" SG_ 2566840591 ReferenceEngineRetarderTorque "x0000001D041286C7";
BA_ "SeToolItemID_SIGNAL" SG_ 2566840591 ReferenceEngineRetarderTorque "x0000001D041286C7";
BA_ "SeToolName_SIGNAL" SG_ 2566840591 ReferenceEngineRetarderTorque "ReferenceEngineRetarderTorque";
BA_ "SeToolVersion_SIGNAL" SG_ 2566840591 ReferenceEngineRetarderTorque "1";
BA_ "GenSigSendType" SG_ 2566840591 EngRetConf_PerTrqAtIdleP1 3;
BA_ "GenSigCycleTime" SG_ 2566840591 EngRetConf_PerTrqAtIdleP1 100;
BA_ "GenSigCycleTimeActive" SG_ 2566840591 EngRetConf_PerTrqAtIdleP1 100;
BA_ "GenSigStartValue" SG_ 2566840591 EngRetConf_PerTrqAtIdleP1 255;
BA_ "Platform_VMCU1_Sig" SG_ 2566840591 EngRetConf_PerTrqAtIdleP1 1;
BA_ "SPN" SG_ 2566840591 EngRetConf_PerTrqAtIdleP1 551;
BA_ "SeToolAncestorID_SIGNAL" SG_ 2566840591 EngRetConf_PerTrqAtIdleP1 "x0000001D0431F0CE";
BA_ "SeToolItemID_SIGNAL" SG_ 2566840591 EngRetConf_PerTrqAtIdleP1 "x0000001D0431F0CE";
BA_ "SeToolName_SIGNAL" SG_ 2566840591 EngRetConf_PerTrqAtIdleP1 "EngRetConf_PerTrqAtIdleP1";
BA_ "SeToolVersion_SIGNAL" SG_ 2566840591 EngRetConf_PerTrqAtIdleP1 "1";
BA_ "GenSigSendType" SG_ 2566840591 EngRetConf_RetSpeedAtP3 3;
BA_ "GenSigCycleTime" SG_ 2566840591 EngRetConf_RetSpeedAtP3 100;
BA_ "GenSigCycleTimeActive" SG_ 2566840591 EngRetConf_RetSpeedAtP3 100;
BA_ "GenSigStartValue" SG_ 2566840591 EngRetConf_RetSpeedAtP3 65535;
BA_ "Platform_VMCU1_Sig" SG_ 2566840591 EngRetConf_RetSpeedAtP3 1;
BA_ "SPN" SG_ 2566840591 EngRetConf_RetSpeedAtP3 549;
BA_ "SeToolAncestorID_SIGNAL" SG_ 2566840591 EngRetConf_RetSpeedAtP3 "x0000001D0431F0DE";
BA_ "SeToolItemID_SIGNAL" SG_ 2566840591 EngRetConf_RetSpeedAtP3 "x0000001D0431F0DE";
BA_ "SeToolName_SIGNAL" SG_ 2566840591 EngRetConf_RetSpeedAtP3 "EngRetConf_RetSpeedAtP3";
BA_ "SeToolVersion_SIGNAL" SG_ 2566840591 EngRetConf_RetSpeedAtP3 "1";
BA_ "GenSigSendType" SG_ 2566840591 EngRetConf_PerTrqAtMaxSpeedP2 3;
BA_ "GenSigCycleTime" SG_ 2566840591 EngRetConf_PerTrqAtMaxSpeedP2 100;
BA_ "GenSigCycleTimeActive" SG_ 2566840591 EngRetConf_PerTrqAtMaxSpeedP2 100;
BA_ "GenSigStartValue" SG_ 2566840591 EngRetConf_PerTrqAtMaxSpeedP2 255;
BA_ "Platform_VMCU1_Sig" SG_ 2566840591 EngRetConf_PerTrqAtMaxSpeedP2 1;
BA_ "SPN" SG_ 2566840591 EngRetConf_PerTrqAtMaxSpeedP2 552;
BA_ "SeToolAncestorID_SIGNAL" SG_ 2566840591 EngRetConf_PerTrqAtMaxSpeedP2 "x0000001D0431F0E2";
BA_ "SeToolItemID_SIGNAL" SG_ 2566840591 EngRetConf_PerTrqAtMaxSpeedP2 "x0000001D0431F0E2";
BA_ "SeToolName_SIGNAL" SG_ 2566840591 EngRetConf_PerTrqAtMaxSpeedP2 "EngRetConf_PerTrqAtMaxSpeedP2";
BA_ "SeToolVersion_SIGNAL" SG_ 2566840591 EngRetConf_PerTrqAtMaxSpeedP2 "1";
BA_ "GenSigSendType" SG_ 2566840591 EngRetConf_PerTrqAtP5 3;
BA_ "GenSigCycleTime" SG_ 2566840591 EngRetConf_PerTrqAtP5 100;
BA_ "GenSigCycleTimeActive" SG_ 2566840591 EngRetConf_PerTrqAtP5 100;
BA_ "GenSigStartValue" SG_ 2566840591 EngRetConf_PerTrqAtP5 255;
BA_ "Platform_VMCU1_Sig" SG_ 2566840591 EngRetConf_PerTrqAtP5 1;
BA_ "SPN" SG_ 2566840591 EngRetConf_PerTrqAtP5 555;
BA_ "SeToolAncestorID_SIGNAL" SG_ 2566840591 EngRetConf_PerTrqAtP5 "x0000001D0431F103";
BA_ "SeToolItemID_SIGNAL" SG_ 2566840591 EngRetConf_PerTrqAtP5 "x0000001D0431F103";
BA_ "SeToolName_SIGNAL" SG_ 2566840591 EngRetConf_PerTrqAtP5 "EngRetConf_PerTrqAtP5";
BA_ "SeToolVersion_SIGNAL" SG_ 2566840591 EngRetConf_PerTrqAtP5 "1";
BA_REL_ "GenSigFirstTimeoutTime" BU_SG_REL_ RECU_Virt SG_ 2348814353 TSC1RECUVMCU_EnRSpdSpdLm 3000;
BA_REL_ "GenSigTimeoutTime" BU_SG_REL_ RECU_Virt SG_ 2348814353 TSC1RECUVMCU_EnRSpdSpdLm 300;
BA_REL_ "GenSigFirstTimeoutTime" BU_SG_REL_ EBS SG_ 2348814353 TSC1RECUVMCU_EnRSpdSpdLm 3000;
BA_REL_ "GenSigTimeoutTime" BU_SG_REL_ EBS SG_ 2348814353 TSC1RECUVMCU_EnRSpdSpdLm 300;
BA_REL_ "GenSigFirstTimeoutTime" BU_SG_REL_ EBS SG_ 2348814353 TSC1RECUVMCU_EnOvrdCtrlM 3000;
BA_REL_ "GenSigTimeoutTime" BU_SG_REL_ EBS SG_ 2348814353 TSC1RECUVMCU_EnOvrdCtrlM 300;
BA_REL_ "GenSigFirstTimeoutTime" BU_SG_REL_ RECU_Virt SG_ 2348814353 TSC1RECUVMCU_EnOvrdCtrlM 3000;
BA_REL_ "GenSigTimeoutTime" BU_SG_REL_ RECU_Virt SG_ 2348814353 TSC1RECUVMCU_EnOvrdCtrlM 300;
BA_REL_ "GenSigFirstTimeoutTime" BU_SG_REL_ RECU_Virt SG_ 2348814353 TSC1RECUVMCU_EnRTrqTrqLm 3000;
BA_REL_ "GenSigTimeoutTime" BU_SG_REL_ RECU_Virt SG_ 2348814353 TSC1RECUVMCU_EnRTrqTrqLm 300;
BA_REL_ "GenSigFirstTimeoutTime" BU_SG_REL_ EBS SG_ 2348814353 TSC1RECUVMCU_EnRTrqTrqLm 3000;
BA_REL_ "GenSigTimeoutTime" BU_SG_REL_ EBS SG_ 2348814353 TSC1RECUVMCU_EnRTrqTrqLm 300;
BA_REL_ "GenSigFirstTimeoutTime" BU_SG_REL_ RECU_Virt SG_ 2348814353 TSC1RECUVMCU_EnRSpdCtrlC 3000;
BA_REL_ "GenSigTimeoutTime" BU_SG_REL_ RECU_Virt SG_ 2348814353 TSC1RECUVMCU_EnRSpdCtrlC 300;
BA_REL_ "GenSigFirstTimeoutTime" BU_SG_REL_ EBS SG_ 2348814353 TSC1RECUVMCU_EnRSpdCtrlC 3000;
BA_REL_ "GenSigTimeoutTime" BU_SG_REL_ EBS SG_ 2348814353 TSC1RECUVMCU_EnRSpdCtrlC 300;
BA_REL_ "GenSigFirstTimeoutTime" BU_SG_REL_ EBS SG_ 2348814353 TSC1RECUVMCU_OvrdCtrlMPr 3000;
BA_REL_ "GenSigTimeoutTime" BU_SG_REL_ EBS SG_ 2348814353 TSC1RECUVMCU_OvrdCtrlMPr 300;
BA_REL_ "GenSigFirstTimeoutTime" BU_SG_REL_ RECU_Virt SG_ 2348814353 TSC1RECUVMCU_OvrdCtrlMPr 3000;
BA_REL_ "GenSigTimeoutTime" BU_SG_REL_ RECU_Virt SG_ 2348814353 TSC1RECUVMCU_OvrdCtrlMPr 300;
BA_REL_ "GenSigFirstTimeoutTime" BU_SG_REL_ RECU_Virt SG_ 2348814339 TSC1RECUTECU_EnRTrqTrqLm 3000;
BA_REL_ "GenSigTimeoutTime" BU_SG_REL_ RECU_Virt SG_ 2348814339 TSC1RECUTECU_EnRTrqTrqLm 300;
BA_REL_ "GenSigFirstTimeoutTime" BU_SG_REL_ RECU_Virt SG_ 2348814339 TSC1RECUTECU_EnOvrdCtrlM 3000;
BA_REL_ "GenSigTimeoutTime" BU_SG_REL_ RECU_Virt SG_ 2348814339 TSC1RECUTECU_EnOvrdCtrlM 300;
BA_REL_ "GenSigFirstTimeoutTime" BU_SG_REL_ RECU_Virt SG_ 2348814339 TSC1RECUTECU_OvrdCtrlMPr 3000;
BA_REL_ "GenSigTimeoutTime" BU_SG_REL_ RECU_Virt SG_ 2348814339 TSC1RECUTECU_OvrdCtrlMPr 300;
BA_REL_ "GenSigFirstTimeoutTime" BU_SG_REL_ RECU_Virt SG_ 2348814339 TSC1RECUTECU_EnRSpdCtrlC 3000;
BA_REL_ "GenSigTimeoutTime" BU_SG_REL_ RECU_Virt SG_ 2348814339 TSC1RECUTECU_EnRSpdCtrlC 300;
BA_REL_ "GenSigFirstTimeoutTime" BU_SG_REL_ RECU_Virt SG_ 2348814339 TSC1RECUTECU_EnRSpdSpdLm 3000;
BA_REL_ "GenSigTimeoutTime" BU_SG_REL_ RECU_Virt SG_ 2348814339 TSC1RECUTECU_EnRSpdSpdLm 300;
BA_REL_ "GenSigFirstTimeoutTime" BU_SG_REL_ RECU_Virt SG_ 2348814337 TSC1RECUEMSdap_EnRSpdSpdLm 3000;
BA_REL_ "GenSigTimeoutTime" BU_SG_REL_ RECU_Virt SG_ 2348814337 TSC1RECUEMSdap_EnRSpdSpdLm 300;
BA_REL_ "GenSigFirstTimeoutTime" BU_SG_REL_ RECU_Virt SG_ 2348814337 TSC1RECUEMSdap_OvrdCtrlMPr 3000;
BA_REL_ "GenSigTimeoutTime" BU_SG_REL_ RECU_Virt SG_ 2348814337 TSC1RECUEMSdap_OvrdCtrlMPr 300;
BA_REL_ "GenSigFirstTimeoutTime" BU_SG_REL_ RECU_Virt SG_ 2348814337 TSC1RECUEMSdap_EnOvrdCtrlM 3000;
BA_REL_ "GenSigTimeoutTime" BU_SG_REL_ RECU_Virt SG_ 2348814337 TSC1RECUEMSdap_EnOvrdCtrlM 300;
BA_REL_ "GenSigFirstTimeoutTime" BU_SG_REL_ RECU_Virt SG_ 2348814337 TSC1RECUEMSdap_EnRSpdCtrlC 3000;
BA_REL_ "GenSigTimeoutTime" BU_SG_REL_ RECU_Virt SG_ 2348814337 TSC1RECUEMSdap_EnRSpdCtrlC 300;
BA_REL_ "GenSigFirstTimeoutTime" BU_SG_REL_ RECU_Virt SG_ 2348814337 TSC1RECUEMSdap_EnRTrqTrqLm 3000;
BA_REL_ "GenSigTimeoutTime" BU_SG_REL_ RECU_Virt SG_ 2348814337 TSC1RECUEMSdap_EnRTrqTrqLm 300;
BA_REL_ "GenSigFirstTimeoutTime" BU_SG_REL_ RECU_Virt SG_ 2348814336 TSC1RECUEMSccb_EnRSpdSpdLm 3000;
BA_REL_ "GenSigTimeoutTime" BU_SG_REL_ RECU_Virt SG_ 2348814336 TSC1RECUEMSccb_EnRSpdSpdLm 300;
BA_REL_ "GenSigFirstTimeoutTime" BU_SG_REL_ RECU_Virt SG_ 2348814336 TSC1RECUEMSccb_EnRSpdCtrlC 3000;
BA_REL_ "GenSigTimeoutTime" BU_SG_REL_ RECU_Virt SG_ 2348814336 TSC1RECUEMSccb_EnRSpdCtrlC 300;
BA_REL_ "GenSigFirstTimeoutTime" BU_SG_REL_ RECU_Virt SG_ 2348814336 TSC1RECUEMSccb_EnOvrdCtrlM 3000;
BA_REL_ "GenSigTimeoutTime" BU_SG_REL_ RECU_Virt SG_ 2348814336 TSC1RECUEMSccb_EnOvrdCtrlM 300;
BA_REL_ "GenSigFirstTimeoutTime" BU_SG_REL_ RECU_Virt SG_ 2348814336 TSC1RECUEMSccb_OvrdCtrlMPr 3000;
BA_REL_ "GenSigTimeoutTime" BU_SG_REL_ RECU_Virt SG_ 2348814336 TSC1RECUEMSccb_OvrdCtrlMPr 300;
BA_REL_ "GenSigFirstTimeoutTime" BU_SG_REL_ RECU_Virt SG_ 2348814336 TSC1RECUEMSccb_EnRTrqTrqLm 3000;
BA_REL_ "GenSigTimeoutTime" BU_SG_REL_ RECU_Virt SG_ 2348814336 TSC1RECUEMSccb_EnRTrqTrqLm 300;
BA_REL_ "GenSigFirstTimeoutTime" BU_SG_REL_ RECU_Virt SG_ 2348814347 TSC1RECUABS_EnOvrdCtrlM 3000;
BA_REL_ "GenSigTimeoutTime" BU_SG_REL_ RECU_Virt SG_ 2348814347 TSC1RECUABS_EnOvrdCtrlM 300;
BA_REL_ "GenSigFirstTimeoutTime" BU_SG_REL_ RECU_Virt SG_ 2348814347 TSC1RECUABS_EnRTrqTrqLm 3000;
BA_REL_ "GenSigTimeoutTime" BU_SG_REL_ RECU_Virt SG_ 2348814347 TSC1RECUABS_EnRTrqTrqLm 300;
BA_REL_ "GenSigFirstTimeoutTime" BU_SG_REL_ RECU_Virt SG_ 2348814347 TSC1RECUABS_EnRSpdSpdLm 3000;
BA_REL_ "GenSigTimeoutTime" BU_SG_REL_ RECU_Virt SG_ 2348814347 TSC1RECUABS_EnRSpdSpdLm 300;
BA_REL_ "GenSigFirstTimeoutTime" BU_SG_REL_ RECU_Virt SG_ 2348814347 TSC1RECUABS_OvrdCtrlMPr 3000;
BA_REL_ "GenSigTimeoutTime" BU_SG_REL_ RECU_Virt SG_ 2348814347 TSC1RECUABS_OvrdCtrlMPr 300;
BA_REL_ "GenSigFirstTimeoutTime" BU_SG_REL_ RECU_Virt SG_ 2348814347 TSC1RECUABS_EnRSpdCtrlC 3000;
BA_REL_ "GenSigTimeoutTime" BU_SG_REL_ RECU_Virt SG_ 2348814347 TSC1RECUABS_EnRSpdCtrlC 300;
BA_REL_ "GenSigFirstTimeoutTime" BU_SG_REL_ EMS SG_ 2348810257 TSC1EMSVMCUtr_EnOvrdCtrlM 3000;
BA_REL_ "GenSigTimeoutTime" BU_SG_REL_ EMS SG_ 2348810257 TSC1EMSVMCUtr_EnOvrdCtrlM 120;
BA_REL_ "GenSigFirstTimeoutTime" BU_SG_REL_ EMS SG_ 2348810257 TSC1EMSVMCUtr_EnRSpdCtrlC 3000;
BA_REL_ "GenSigTimeoutTime" BU_SG_REL_ EMS SG_ 2348810257 TSC1EMSVMCUtr_EnRSpdCtrlC 120;
BA_REL_ "GenSigFirstTimeoutTime" BU_SG_REL_ EMS SG_ 2348810257 TSC1EMSVMCUtr_OvrdCtrlMPr 3000;
BA_REL_ "GenSigTimeoutTime" BU_SG_REL_ EMS SG_ 2348810257 TSC1EMSVMCUtr_OvrdCtrlMPr 120;
BA_REL_ "GenSigFirstTimeoutTime" BU_SG_REL_ EMS SG_ 2348810257 TSC1EMSVMCUtr_EnRSpdSpdLm 3000;
BA_REL_ "GenSigTimeoutTime" BU_SG_REL_ EMS SG_ 2348810257 TSC1EMSVMCUtr_EnRSpdSpdLm 120;
BA_REL_ "GenSigFirstTimeoutTime" BU_SG_REL_ EMS SG_ 2348810257 TSC1EMSVMCUtr_EnRTrqTrqLm 3000;
BA_REL_ "GenSigTimeoutTime" BU_SG_REL_ EMS SG_ 2348810257 TSC1EMSVMCUtr_EnRTrqTrqLm 120;
BA_REL_ "GenSigFirstTimeoutTime" BU_SG_REL_ EMS SG_ 2348810288 TSC1EMSVMCUes_OvrdCtrlMPr 3000;
BA_REL_ "GenSigTimeoutTime" BU_SG_REL_ EMS SG_ 2348810288 TSC1EMSVMCUes_OvrdCtrlMPr 120;
BA_REL_ "GenSigFirstTimeoutTime" BU_SG_REL_ TECU SG_ 2348810288 TSC1EMSVMCUes_OvrdCtrlMPr 3000;
BA_REL_ "GenSigTimeoutTime" BU_SG_REL_ TECU SG_ 2348810288 TSC1EMSVMCUes_OvrdCtrlMPr 120;
BA_REL_ "GenSigFirstTimeoutTime" BU_SG_REL_ TECU SG_ 2348810288 TSC1EMSVMCUes_EnRTrqTrqLm 3000;
BA_REL_ "GenSigTimeoutTime" BU_SG_REL_ TECU SG_ 2348810288 TSC1EMSVMCUes_EnRTrqTrqLm 120;
BA_REL_ "GenSigFirstTimeoutTime" BU_SG_REL_ EMS SG_ 2348810288 TSC1EMSVMCUes_EnRTrqTrqLm 3000;
BA_REL_ "GenSigTimeoutTime" BU_SG_REL_ EMS SG_ 2348810288 TSC1EMSVMCUes_EnRTrqTrqLm 120;
BA_REL_ "GenSigFirstTimeoutTime" BU_SG_REL_ TECU SG_ 2348810288 TSC1EMSVMCUes_EnOvrdCtrlM 3000;
BA_REL_ "GenSigTimeoutTime" BU_SG_REL_ TECU SG_ 2348810288 TSC1EMSVMCUes_EnOvrdCtrlM 120;
BA_REL_ "GenSigFirstTimeoutTime" BU_SG_REL_ EMS SG_ 2348810288 TSC1EMSVMCUes_EnOvrdCtrlM 3000;
BA_REL_ "GenSigTimeoutTime" BU_SG_REL_ EMS SG_ 2348810288 TSC1EMSVMCUes_EnOvrdCtrlM 120;
BA_REL_ "GenSigFirstTimeoutTime" BU_SG_REL_ TECU SG_ 2348810288 TSC1EMSVMCUes_EnRSpdSpdLm 3000;
BA_REL_ "GenSigTimeoutTime" BU_SG_REL_ TECU SG_ 2348810288 TSC1EMSVMCUes_EnRSpdSpdLm 120;
BA_REL_ "GenSigFirstTimeoutTime" BU_SG_REL_ EMS SG_ 2348810288 TSC1EMSVMCUes_EnRSpdSpdLm 3000;
BA_REL_ "GenSigTimeoutTime" BU_SG_REL_ EMS SG_ 2348810288 TSC1EMSVMCUes_EnRSpdSpdLm 120;
BA_REL_ "GenSigFirstTimeoutTime" BU_SG_REL_ EMS SG_ 2348810288 TSC1EMSVMCUes_EnRSpdCtrlC 3000;
BA_REL_ "GenSigTimeoutTime" BU_SG_REL_ EMS SG_ 2348810288 TSC1EMSVMCUes_EnRSpdCtrlC 120;
BA_REL_ "GenSigFirstTimeoutTime" BU_SG_REL_ TECU SG_ 2348810288 TSC1EMSVMCUes_EnRSpdCtrlC 3000;
BA_REL_ "GenSigTimeoutTime" BU_SG_REL_ TECU SG_ 2348810288 TSC1EMSVMCUes_EnRSpdCtrlC 120;
BA_REL_ "GenSigFirstTimeoutTime" BU_SG_REL_ EMS SG_ 2348810243 TSC1EMSTECU_EnRSpdSpdLm 3000;
BA_REL_ "GenSigTimeoutTime" BU_SG_REL_ EMS SG_ 2348810243 TSC1EMSTECU_EnRSpdSpdLm 60;
BA_REL_ "GenSigFirstTimeoutTime" BU_SG_REL_ EMS SG_ 2348810243 TSC1EMSTECU_EnOvrdCtrlM 3000;
BA_REL_ "GenSigTimeoutTime" BU_SG_REL_ EMS SG_ 2348810243 TSC1EMSTECU_EnOvrdCtrlM 60;
BA_REL_ "GenSigFirstTimeoutTime" BU_SG_REL_ EMS SG_ 2348810243 TSC1EMSTECU_OvrdCtrlMPr 3000;
BA_REL_ "GenSigTimeoutTime" BU_SG_REL_ EMS SG_ 2348810243 TSC1EMSTECU_OvrdCtrlMPr 60;
BA_REL_ "GenSigFirstTimeoutTime" BU_SG_REL_ EMS SG_ 2348810243 TSC1EMSTECU_EnRSpdCtrlC 3000;
BA_REL_ "GenSigTimeoutTime" BU_SG_REL_ EMS SG_ 2348810243 TSC1EMSTECU_EnRSpdCtrlC 60;
BA_REL_ "GenSigFirstTimeoutTime" BU_SG_REL_ EMS SG_ 2348810243 TSC1EMSTECU_EnRTrqTrqLm 3000;
BA_REL_ "GenSigTimeoutTime" BU_SG_REL_ EMS SG_ 2348810243 TSC1EMSTECU_EnRTrqTrqLm 60;
BA_REL_ "GenSigFirstTimeoutTime" BU_SG_REL_ EMS SG_ 2348810251 TSC1EMSABS_EnRTrqTrqLm 3000;
BA_REL_ "GenSigTimeoutTime" BU_SG_REL_ EMS SG_ 2348810251 TSC1EMSABS_EnRTrqTrqLm 60;
BA_REL_ "GenSigFirstTimeoutTime" BU_SG_REL_ EMS SG_ 2348810251 TSC1EMSABS_EnRSpdCtrlC 3000;
BA_REL_ "GenSigTimeoutTime" BU_SG_REL_ EMS SG_ 2348810251 TSC1EMSABS_EnRSpdCtrlC 60;
BA_REL_ "GenSigFirstTimeoutTime" BU_SG_REL_ EMS SG_ 2348810251 TSC1EMSABS_OvrdCtrlMPr 3000;
BA_REL_ "GenSigTimeoutTime" BU_SG_REL_ EMS SG_ 2348810251 TSC1EMSABS_OvrdCtrlMPr 60;
BA_REL_ "GenSigFirstTimeoutTime" BU_SG_REL_ EMS SG_ 2348810251 TSC1EMSABS_EnOvrdCtrlM 3000;
BA_REL_ "GenSigTimeoutTime" BU_SG_REL_ EMS SG_ 2348810251 TSC1EMSABS_EnOvrdCtrlM 60;
BA_REL_ "GenSigFirstTimeoutTime" BU_SG_REL_ EMS SG_ 2348810251 TSC1EMSABS_EnRSpdSpdLm 3000;
BA_REL_ "GenSigTimeoutTime" BU_SG_REL_ EMS SG_ 2348810251 TSC1EMSABS_EnRSpdSpdLm 60;
BA_REL_ "GenSigFirstTimeoutTime" BU_SG_REL_ EMS SG_ 2348810413 TSC1EMSDACU_OvrdCtrlMPr 3000;
BA_REL_ "GenSigTimeoutTime" BU_SG_REL_ EMS SG_ 2348810413 TSC1EMSDACU_OvrdCtrlMPr 120;
BA_REL_ "GenSigFirstTimeoutTime" BU_SG_REL_ EMS SG_ 2348810413 TSC1EMSDACU_EnRSpdSpdLm 3000;
BA_REL_ "GenSigTimeoutTime" BU_SG_REL_ EMS SG_ 2348810413 TSC1EMSDACU_EnRSpdSpdLm 120;
BA_REL_ "GenSigFirstTimeoutTime" BU_SG_REL_ EMS SG_ 2348810413 TSC1EMSDACU_EnRSpdCtrlC 3000;
BA_REL_ "GenSigTimeoutTime" BU_SG_REL_ EMS SG_ 2348810413 TSC1EMSDACU_EnRSpdCtrlC 120;
BA_REL_ "GenSigFirstTimeoutTime" BU_SG_REL_ EMS SG_ 2348810413 TSC1EMSDACU_EnRTrqTrqLm 3000;
BA_REL_ "GenSigTimeoutTime" BU_SG_REL_ EMS SG_ 2348810413 TSC1EMSDACU_EnRTrqTrqLm 120;
BA_REL_ "GenSigFirstTimeoutTime" BU_SG_REL_ EMS SG_ 2348810413 TSC1EMSDACU_EnOvrdCtrlM 3000;
BA_REL_ "GenSigTimeoutTime" BU_SG_REL_ EMS SG_ 2348810413 TSC1EMSDACU_EnOvrdCtrlM 120;
BA_REL_ "GenSigFirstTimeoutTime" BU_SG_REL_ EBS SG_ 2348814097 TSC1EMSrVMCU_EnRSpdCtrlC 3000;
BA_REL_ "GenSigTimeoutTime" BU_SG_REL_ EBS SG_ 2348814097 TSC1EMSrVMCU_EnRSpdCtrlC 300;
BA_REL_ "GenSigFirstTimeoutTime" BU_SG_REL_ EMS SG_ 2348814097 TSC1EMSrVMCU_EnRSpdCtrlC 3000;
BA_REL_ "GenSigTimeoutTime" BU_SG_REL_ EMS SG_ 2348814097 TSC1EMSrVMCU_EnRSpdCtrlC 300;
BA_REL_ "GenSigFirstTimeoutTime" BU_SG_REL_ EMS SG_ 2348814097 TSC1EMSrVMCU_EnRTrqTrqLm 3000;
BA_REL_ "GenSigTimeoutTime" BU_SG_REL_ EMS SG_ 2348814097 TSC1EMSrVMCU_EnRTrqTrqLm 300;
BA_REL_ "GenSigFirstTimeoutTime" BU_SG_REL_ EBS SG_ 2348814097 TSC1EMSrVMCU_EnRTrqTrqLm 3000;
BA_REL_ "GenSigTimeoutTime" BU_SG_REL_ EBS SG_ 2348814097 TSC1EMSrVMCU_EnRTrqTrqLm 300;
BA_REL_ "GenSigFirstTimeoutTime" BU_SG_REL_ EMS SG_ 2348814097 TSC1EMSrVMCU_OvrdCtrlMPr 3000;
BA_REL_ "GenSigTimeoutTime" BU_SG_REL_ EMS SG_ 2348814097 TSC1EMSrVMCU_OvrdCtrlMPr 300;
BA_REL_ "GenSigFirstTimeoutTime" BU_SG_REL_ EBS SG_ 2348814097 TSC1EMSrVMCU_OvrdCtrlMPr 3000;
BA_REL_ "GenSigTimeoutTime" BU_SG_REL_ EBS SG_ 2348814097 TSC1EMSrVMCU_OvrdCtrlMPr 300;
BA_REL_ "GenSigFirstTimeoutTime" BU_SG_REL_ EBS SG_ 2348814097 TSC1EMSrVMCU_EnRSpdSpdLm 3000;
BA_REL_ "GenSigTimeoutTime" BU_SG_REL_ EBS SG_ 2348814097 TSC1EMSrVMCU_EnRSpdSpdLm 300;
BA_REL_ "GenSigFirstTimeoutTime" BU_SG_REL_ EMS SG_ 2348814097 TSC1EMSrVMCU_EnRSpdSpdLm 3000;
BA_REL_ "GenSigTimeoutTime" BU_SG_REL_ EMS SG_ 2348814097 TSC1EMSrVMCU_EnRSpdSpdLm 300;
BA_REL_ "GenSigFirstTimeoutTime" BU_SG_REL_ EMS SG_ 2348814097 TSC1EMSrVMCU_EnOvrdCtrlM 3000;
BA_REL_ "GenSigTimeoutTime" BU_SG_REL_ EMS SG_ 2348814097 TSC1EMSrVMCU_EnOvrdCtrlM 300;
BA_REL_ "GenSigFirstTimeoutTime" BU_SG_REL_ EBS SG_ 2348814097 TSC1EMSrVMCU_EnOvrdCtrlM 3000;
BA_REL_ "GenSigTimeoutTime" BU_SG_REL_ EBS SG_ 2348814097 TSC1EMSrVMCU_EnOvrdCtrlM 300;
BA_REL_ "GenSigFirstTimeoutTime" BU_SG_REL_ EMS SG_ 2348814083 TSC1EMSrTECU_OvrdCtrlMPr 3000;
BA_REL_ "GenSigTimeoutTime" BU_SG_REL_ EMS SG_ 2348814083 TSC1EMSrTECU_OvrdCtrlMPr 300;
BA_REL_ "GenSigFirstTimeoutTime" BU_SG_REL_ EMS SG_ 2348814083 TSC1EMSrTECU_EnRSpdCtrlC 3000;
BA_REL_ "GenSigTimeoutTime" BU_SG_REL_ EMS SG_ 2348814083 TSC1EMSrTECU_EnRSpdCtrlC 300;
BA_REL_ "GenSigFirstTimeoutTime" BU_SG_REL_ EMS SG_ 2348814083 TSC1EMSrTECU_EnOvrdCtrlM 3000;
BA_REL_ "GenSigTimeoutTime" BU_SG_REL_ EMS SG_ 2348814083 TSC1EMSrTECU_EnOvrdCtrlM 300;
BA_REL_ "GenSigFirstTimeoutTime" BU_SG_REL_ EMS SG_ 2348814083 TSC1EMSrTECU_EnRTrqTrqLm 3000;
BA_REL_ "GenSigTimeoutTime" BU_SG_REL_ EMS SG_ 2348814083 TSC1EMSrTECU_EnRTrqTrqLm 300;
BA_REL_ "GenSigFirstTimeoutTime" BU_SG_REL_ EMS SG_ 2348814083 TSC1EMSrTECU_EnRSpdSpdLm 3000;
BA_REL_ "GenSigTimeoutTime" BU_SG_REL_ EMS SG_ 2348814083 TSC1EMSrTECU_EnRSpdSpdLm 300;
BA_REL_ "GenSigFirstTimeoutTime" BU_SG_REL_ TECU SG_ 2348814091 TSC1EMSrABS_EnRTrqTrqLm 3000;
BA_REL_ "GenSigTimeoutTime" BU_SG_REL_ TECU SG_ 2348814091 TSC1EMSrABS_EnRTrqTrqLm 300;
BA_REL_ "GenSigFirstTimeoutTime" BU_SG_REL_ EMS SG_ 2348814091 TSC1EMSrABS_EnRTrqTrqLm 3000;
BA_REL_ "GenSigTimeoutTime" BU_SG_REL_ EMS SG_ 2348814091 TSC1EMSrABS_EnRTrqTrqLm 300;
BA_REL_ "GenSigFirstTimeoutTime" BU_SG_REL_ TECU SG_ 2348814091 TSC1EMSrABS_EnRSpdCtrlC 3000;
BA_REL_ "GenSigTimeoutTime" BU_SG_REL_ TECU SG_ 2348814091 TSC1EMSrABS_EnRSpdCtrlC 300;
BA_REL_ "GenSigFirstTimeoutTime" BU_SG_REL_ EMS SG_ 2348814091 TSC1EMSrABS_EnRSpdCtrlC 3000;
BA_REL_ "GenSigTimeoutTime" BU_SG_REL_ EMS SG_ 2348814091 TSC1EMSrABS_EnRSpdCtrlC 300;
BA_REL_ "GenSigFirstTimeoutTime" BU_SG_REL_ TECU SG_ 2348814091 TSC1EMSrABS_OvrdCtrlMPr 3000;
BA_REL_ "GenSigTimeoutTime" BU_SG_REL_ TECU SG_ 2348814091 TSC1EMSrABS_OvrdCtrlMPr 300;
BA_REL_ "GenSigFirstTimeoutTime" BU_SG_REL_ EMS SG_ 2348814091 TSC1EMSrABS_OvrdCtrlMPr 3000;
BA_REL_ "GenSigTimeoutTime" BU_SG_REL_ EMS SG_ 2348814091 TSC1EMSrABS_OvrdCtrlMPr 300;
BA_REL_ "GenSigFirstTimeoutTime" BU_SG_REL_ TECU SG_ 2348814091 TSC1EMSrABS_EnOvrdCtrlM 3000;
BA_REL_ "GenSigTimeoutTime" BU_SG_REL_ TECU SG_ 2348814091 TSC1EMSrABS_EnOvrdCtrlM 300;
BA_REL_ "GenSigFirstTimeoutTime" BU_SG_REL_ EMS SG_ 2348814091 TSC1EMSrABS_EnOvrdCtrlM 3000;
BA_REL_ "GenSigTimeoutTime" BU_SG_REL_ EMS SG_ 2348814091 TSC1EMSrABS_EnOvrdCtrlM 300;
BA_REL_ "GenSigFirstTimeoutTime" BU_SG_REL_ TECU SG_ 2348814091 TSC1EMSrABS_EnRSpdSpdLm 3000;
BA_REL_ "GenSigTimeoutTime" BU_SG_REL_ TECU SG_ 2348814091 TSC1EMSrABS_EnRSpdSpdLm 300;
BA_REL_ "GenSigFirstTimeoutTime" BU_SG_REL_ EMS SG_ 2348814091 TSC1EMSrABS_EnRSpdSpdLm 3000;
BA_REL_ "GenSigTimeoutTime" BU_SG_REL_ EMS SG_ 2348814091 TSC1EMSrABS_EnRSpdSpdLm 300;
BA_REL_ "GenSigFirstTimeoutTime" BU_SG_REL_ BBM SG_ 2566846467 TransmissionOilTemp_ISig_3 24000;
BA_REL_ "GenSigTimeoutTime" BU_SG_REL_ BBM SG_ 2566846467 TransmissionOilTemp_ISig_3 6000;
BA_REL_ "GenSigFirstTimeoutTime" BU_SG_REL_ EMS SG_ 2566846467 TransmissionOilTemp_ISig_3 24000;
BA_REL_ "GenSigTimeoutTime" BU_SG_REL_ EMS SG_ 2566846467 TransmissionOilTemp_ISig_3 6000;
BA_REL_ "GenSigFirstTimeoutTime" BU_SG_REL_ IC3 SG_ 2566846467 TransmissionOilTemp_ISig_3 24000;
BA_REL_ "GenSigTimeoutTime" BU_SG_REL_ IC3 SG_ 2566846467 TransmissionOilTemp_ISig_3 6000;
BA_REL_ "GenSigFirstTimeoutTime" BU_SG_REL_ IC3 SG_ 2566846467 TransmissionOilLevel 24000;
BA_REL_ "GenSigTimeoutTime" BU_SG_REL_ IC3 SG_ 2566846467 TransmissionOilLevel 6000;
BA_REL_ "GenSigFirstTimeoutTime" BU_SG_REL_ IC3 SG_ 2566882307 TransmissionGCVW_ISig_3 3000;
BA_REL_ "GenSigTimeoutTime" BU_SG_REL_ IC3 SG_ 2566882307 TransmissionGCVW_ISig_3 600;
BA_REL_ "GenSigFirstTimeoutTime" BU_SG_REL_ EMS SG_ 2566882307 TransmissionGCVW_ISig_3 3000;
BA_REL_ "GenSigTimeoutTime" BU_SG_REL_ EMS SG_ 2566882307 TransmissionGCVW_ISig_3 570;
BA_REL_ "GenSigFirstTimeoutTime" BU_SG_REL_ VMCU SG_ 2566882307 TransmissionGCVW_ISig_3 3000;
BA_REL_ "GenSigTimeoutTime" BU_SG_REL_ VMCU SG_ 2566882307 TransmissionGCVW_ISig_3 570;
BA_REL_ "GenSigFirstTimeoutTime" BU_SG_REL_ VMCU SG_ 2566882307 RawRoadInclination 3000;
BA_REL_ "GenSigTimeoutTime" BU_SG_REL_ VMCU SG_ 2566882307 RawRoadInclination 570;
BA_REL_ "GenSigFirstTimeoutTime" BU_SG_REL_ IC3 SG_ 2566882307 LowTempClutchInfo 3000;
BA_REL_ "GenSigTimeoutTime" BU_SG_REL_ IC3 SG_ 2566882307 LowTempClutchInfo 600;
BA_REL_ "GenSigFirstTimeoutTime" BU_SG_REL_ EBS SG_ 2566882307 PermittedHSAPressure 3000;
BA_REL_ "GenSigTimeoutTime" BU_SG_REL_ EBS SG_ 2566882307 PermittedHSAPressure 570;
BA_REL_ "GenSigFirstTimeoutTime" BU_SG_REL_ VMCU SG_ 2566882307 TransmEngineCrankEnable_ISig_3 3000;
BA_REL_ "GenSigTimeoutTime" BU_SG_REL_ VMCU SG_ 2566882307 TransmEngineCrankEnable_ISig_3 570;
BA_REL_ "GenSigFirstTimeoutTime" BU_SG_REL_ EBS SG_ 2566841879 MonthUTC_ISig_3 6000;
BA_REL_ "GenSigTimeoutTime" BU_SG_REL_ EBS SG_ 2566841879 MonthUTC_ISig_3 1500;
BA_REL_ "GenSigFirstTimeoutTime" BU_SG_REL_ TECU SG_ 2566841879 MonthUTC_ISig_3 6000;
BA_REL_ "GenSigTimeoutTime" BU_SG_REL_ TECU SG_ 2566841879 MonthUTC_ISig_3 1500;
BA_REL_ "GenSigFirstTimeoutTime" BU_SG_REL_ ACM SG_ 2566841879 MonthUTC_ISig_3 6000;
BA_REL_ "GenSigTimeoutTime" BU_SG_REL_ ACM SG_ 2566841879 MonthUTC_ISig_3 1500;
BA_REL_ "GenSigFirstTimeoutTime" BU_SG_REL_ DACU SG_ 2566841879 MonthUTC_ISig_3 6000;
BA_REL_ "GenSigTimeoutTime" BU_SG_REL_ DACU SG_ 2566841879 MonthUTC_ISig_3 1500;
BA_REL_ "GenSigFirstTimeoutTime" BU_SG_REL_ EMS SG_ 2566841879 MonthUTC_ISig_3 6000;
BA_REL_ "GenSigTimeoutTime" BU_SG_REL_ EMS SG_ 2566841879 MonthUTC_ISig_3 1500;
BA_REL_ "GenSigFirstTimeoutTime" BU_SG_REL_ BBM SG_ 2566841879 MonthUTC_ISig_3 6000;
BA_REL_ "GenSigTimeoutTime" BU_SG_REL_ BBM SG_ 2566841879 MonthUTC_ISig_3 1500;
BA_REL_ "GenSigFirstTimeoutTime" BU_SG_REL_ IC3 SG_ 2566841879 MonthUTC_ISig_3 6000;
BA_REL_ "GenSigTimeoutTime" BU_SG_REL_ IC3 SG_ 2566841879 MonthUTC_ISig_3 1500;
BA_REL_ "GenSigFirstTimeoutTime" BU_SG_REL_ CIOM SG_ 2566841879 MonthUTC_ISig_3 6000;
BA_REL_ "GenSigTimeoutTime" BU_SG_REL_ CIOM SG_ 2566841879 MonthUTC_ISig_3 1500;
BA_REL_ "GenSigFirstTimeoutTime" BU_SG_REL_ EBS SG_ 2566841879 SelectedLocalHourOffset_ISig_3 6000;
BA_REL_ "GenSigTimeoutTime" BU_SG_REL_ EBS SG_ 2566841879 SelectedLocalHourOffset_ISig_3 1500;
BA_REL_ "GenSigFirstTimeoutTime" BU_SG_REL_ IC3 SG_ 2566841879 SelectedLocalHourOffset_ISig_3 6000;
BA_REL_ "GenSigTimeoutTime" BU_SG_REL_ IC3 SG_ 2566841879 SelectedLocalHourOffset_ISig_3 1500;
BA_REL_ "GenSigFirstTimeoutTime" BU_SG_REL_ DACU SG_ 2566841879 SecondsUTC_ISig_3 6000;
BA_REL_ "GenSigTimeoutTime" BU_SG_REL_ DACU SG_ 2566841879 SecondsUTC_ISig_3 1500;
BA_REL_ "GenSigFirstTimeoutTime" BU_SG_REL_ TECU SG_ 2566841879 SecondsUTC_ISig_3 6000;
BA_REL_ "GenSigTimeoutTime" BU_SG_REL_ TECU SG_ 2566841879 SecondsUTC_ISig_3 1500;
BA_REL_ "GenSigFirstTimeoutTime" BU_SG_REL_ CIOM SG_ 2566841879 SecondsUTC_ISig_3 6000;
BA_REL_ "GenSigTimeoutTime" BU_SG_REL_ CIOM SG_ 2566841879 SecondsUTC_ISig_3 1500;
BA_REL_ "GenSigFirstTimeoutTime" BU_SG_REL_ IC3 SG_ 2566841879 SecondsUTC_ISig_3 6000;
BA_REL_ "GenSigTimeoutTime" BU_SG_REL_ IC3 SG_ 2566841879 SecondsUTC_ISig_3 1500;
BA_REL_ "GenSigFirstTimeoutTime" BU_SG_REL_ ACM SG_ 2566841879 SecondsUTC_ISig_3 6000;
BA_REL_ "GenSigTimeoutTime" BU_SG_REL_ ACM SG_ 2566841879 SecondsUTC_ISig_3 1500;
BA_REL_ "GenSigFirstTimeoutTime" BU_SG_REL_ BBM SG_ 2566841879 SecondsUTC_ISig_3 6000;
BA_REL_ "GenSigTimeoutTime" BU_SG_REL_ BBM SG_ 2566841879 SecondsUTC_ISig_3 1500;
BA_REL_ "GenSigFirstTimeoutTime" BU_SG_REL_ EBS SG_ 2566841879 SecondsUTC_ISig_3 6000;
BA_REL_ "GenSigTimeoutTime" BU_SG_REL_ EBS SG_ 2566841879 SecondsUTC_ISig_3 1500;
BA_REL_ "GenSigFirstTimeoutTime" BU_SG_REL_ EMS SG_ 2566841879 SecondsUTC_ISig_3 6000;
BA_REL_ "GenSigTimeoutTime" BU_SG_REL_ EMS SG_ 2566841879 SecondsUTC_ISig_3 1500;
BA_REL_ "GenSigFirstTimeoutTime" BU_SG_REL_ EBS SG_ 2566841879 SelectedLocalMinuteOffset_ISig_3 6000;
BA_REL_ "GenSigTimeoutTime" BU_SG_REL_ EBS SG_ 2566841879 SelectedLocalMinuteOffset_ISig_3 1500;
BA_REL_ "GenSigFirstTimeoutTime" BU_SG_REL_ IC3 SG_ 2566841879 SelectedLocalMinuteOffset_ISig_3 6000;
BA_REL_ "GenSigTimeoutTime" BU_SG_REL_ IC3 SG_ 2566841879 SelectedLocalMinuteOffset_ISig_3 1500;
BA_REL_ "GenSigFirstTimeoutTime" BU_SG_REL_ EBS SG_ 2566841879 HoursUTC_ISig_3 6000;
BA_REL_ "GenSigTimeoutTime" BU_SG_REL_ EBS SG_ 2566841879 HoursUTC_ISig_3 1500;
BA_REL_ "GenSigFirstTimeoutTime" BU_SG_REL_ DACU SG_ 2566841879 HoursUTC_ISig_3 6000;
BA_REL_ "GenSigTimeoutTime" BU_SG_REL_ DACU SG_ 2566841879 HoursUTC_ISig_3 1500;
BA_REL_ "GenSigFirstTimeoutTime" BU_SG_REL_ ACM SG_ 2566841879 HoursUTC_ISig_3 6000;
BA_REL_ "GenSigTimeoutTime" BU_SG_REL_ ACM SG_ 2566841879 HoursUTC_ISig_3 1500;
BA_REL_ "GenSigFirstTimeoutTime" BU_SG_REL_ BBM SG_ 2566841879 HoursUTC_ISig_3 6000;
BA_REL_ "GenSigTimeoutTime" BU_SG_REL_ BBM SG_ 2566841879 HoursUTC_ISig_3 1500;
BA_REL_ "GenSigFirstTimeoutTime" BU_SG_REL_ IC3 SG_ 2566841879 HoursUTC_ISig_3 6000;
BA_REL_ "GenSigTimeoutTime" BU_SG_REL_ IC3 SG_ 2566841879 HoursUTC_ISig_3 1500;
BA_REL_ "GenSigFirstTimeoutTime" BU_SG_REL_ TECU SG_ 2566841879 HoursUTC_ISig_3 6000;
BA_REL_ "GenSigTimeoutTime" BU_SG_REL_ TECU SG_ 2566841879 HoursUTC_ISig_3 1500;
BA_REL_ "GenSigFirstTimeoutTime" BU_SG_REL_ CIOM SG_ 2566841879 HoursUTC_ISig_3 6000;
BA_REL_ "GenSigTimeoutTime" BU_SG_REL_ CIOM SG_ 2566841879 HoursUTC_ISig_3 1500;
BA_REL_ "GenSigFirstTimeoutTime" BU_SG_REL_ EMS SG_ 2566841879 HoursUTC_ISig_3 6000;
BA_REL_ "GenSigTimeoutTime" BU_SG_REL_ EMS SG_ 2566841879 HoursUTC_ISig_3 1500;
BA_REL_ "GenSigFirstTimeoutTime" BU_SG_REL_ EBS SG_ 2566841879 YearUTC_ISig_3 6000;
BA_REL_ "GenSigTimeoutTime" BU_SG_REL_ EBS SG_ 2566841879 YearUTC_ISig_3 1500;
BA_REL_ "GenSigFirstTimeoutTime" BU_SG_REL_ EMS SG_ 2566841879 YearUTC_ISig_3 6000;
BA_REL_ "GenSigTimeoutTime" BU_SG_REL_ EMS SG_ 2566841879 YearUTC_ISig_3 1500;
BA_REL_ "GenSigFirstTimeoutTime" BU_SG_REL_ DACU SG_ 2566841879 YearUTC_ISig_3 6000;
BA_REL_ "GenSigTimeoutTime" BU_SG_REL_ DACU SG_ 2566841879 YearUTC_ISig_3 1500;
BA_REL_ "GenSigFirstTimeoutTime" BU_SG_REL_ IC3 SG_ 2566841879 YearUTC_ISig_3 6000;
BA_REL_ "GenSigTimeoutTime" BU_SG_REL_ IC3 SG_ 2566841879 YearUTC_ISig_3 1500;
BA_REL_ "GenSigFirstTimeoutTime" BU_SG_REL_ ACM SG_ 2566841879 YearUTC_ISig_3 6000;
BA_REL_ "GenSigTimeoutTime" BU_SG_REL_ ACM SG_ 2566841879 YearUTC_ISig_3 1500;
BA_REL_ "GenSigFirstTimeoutTime" BU_SG_REL_ BBM SG_ 2566841879 YearUTC_ISig_3 6000;
BA_REL_ "GenSigTimeoutTime" BU_SG_REL_ BBM SG_ 2566841879 YearUTC_ISig_3 1500;
BA_REL_ "GenSigFirstTimeoutTime" BU_SG_REL_ CIOM SG_ 2566841879 YearUTC_ISig_3 6000;
BA_REL_ "GenSigTimeoutTime" BU_SG_REL_ CIOM SG_ 2566841879 YearUTC_ISig_3 1500;
BA_REL_ "GenSigFirstTimeoutTime" BU_SG_REL_ TECU SG_ 2566841879 YearUTC_ISig_3 6000;
BA_REL_ "GenSigTimeoutTime" BU_SG_REL_ TECU SG_ 2566841879 YearUTC_ISig_3 1500;
BA_REL_ "GenSigFirstTimeoutTime" BU_SG_REL_ TECU SG_ 2566841879 DayUTC_ISig_3 6000;
BA_REL_ "GenSigTimeoutTime" BU_SG_REL_ TECU SG_ 2566841879 DayUTC_ISig_3 1500;
BA_REL_ "GenSigFirstTimeoutTime" BU_SG_REL_ CIOM SG_ 2566841879 DayUTC_ISig_3 6000;
BA_REL_ "GenSigTimeoutTime" BU_SG_REL_ CIOM SG_ 2566841879 DayUTC_ISig_3 1500;
BA_REL_ "GenSigFirstTimeoutTime" BU_SG_REL_ IC3 SG_ 2566841879 DayUTC_ISig_3 6000;
BA_REL_ "GenSigTimeoutTime" BU_SG_REL_ IC3 SG_ 2566841879 DayUTC_ISig_3 1500;
BA_REL_ "GenSigFirstTimeoutTime" BU_SG_REL_ EBS SG_ 2566841879 DayUTC_ISig_3 6000;
BA_REL_ "GenSigTimeoutTime" BU_SG_REL_ EBS SG_ 2566841879 DayUTC_ISig_3 1500;
BA_REL_ "GenSigFirstTimeoutTime" BU_SG_REL_ EMS SG_ 2566841879 DayUTC_ISig_3 6000;
BA_REL_ "GenSigTimeoutTime" BU_SG_REL_ EMS SG_ 2566841879 DayUTC_ISig_3 1500;
BA_REL_ "GenSigFirstTimeoutTime" BU_SG_REL_ DACU SG_ 2566841879 DayUTC_ISig_3 6000;
BA_REL_ "GenSigTimeoutTime" BU_SG_REL_ DACU SG_ 2566841879 DayUTC_ISig_3 1500;
BA_REL_ "GenSigFirstTimeoutTime" BU_SG_REL_ ACM SG_ 2566841879 DayUTC_ISig_3 6000;
BA_REL_ "GenSigTimeoutTime" BU_SG_REL_ ACM SG_ 2566841879 DayUTC_ISig_3 1500;
BA_REL_ "GenSigFirstTimeoutTime" BU_SG_REL_ BBM SG_ 2566841879 DayUTC_ISig_3 6000;
BA_REL_ "GenSigTimeoutTime" BU_SG_REL_ BBM SG_ 2566841879 DayUTC_ISig_3 1500;
BA_REL_ "GenSigFirstTimeoutTime" BU_SG_REL_ DACU SG_ 2566841879 MinutesUTC_ISig_3 6000;
BA_REL_ "GenSigTimeoutTime" BU_SG_REL_ DACU SG_ 2566841879 MinutesUTC_ISig_3 1500;
BA_REL_ "GenSigFirstTimeoutTime" BU_SG_REL_ TECU SG_ 2566841879 MinutesUTC_ISig_3 6000;
BA_REL_ "GenSigTimeoutTime" BU_SG_REL_ TECU SG_ 2566841879 MinutesUTC_ISig_3 1500;
BA_REL_ "GenSigFirstTimeoutTime" BU_SG_REL_ CIOM SG_ 2566841879 MinutesUTC_ISig_3 6000;
BA_REL_ "GenSigTimeoutTime" BU_SG_REL_ CIOM SG_ 2566841879 MinutesUTC_ISig_3 1500;
BA_REL_ "GenSigFirstTimeoutTime" BU_SG_REL_ ACM SG_ 2566841879 MinutesUTC_ISig_3 6000;
BA_REL_ "GenSigTimeoutTime" BU_SG_REL_ ACM SG_ 2566841879 MinutesUTC_ISig_3 1500;
BA_REL_ "GenSigFirstTimeoutTime" BU_SG_REL_ EMS SG_ 2566841879 MinutesUTC_ISig_3 6000;
BA_REL_ "GenSigTimeoutTime" BU_SG_REL_ EMS SG_ 2566841879 MinutesUTC_ISig_3 1500;
BA_REL_ "GenSigFirstTimeoutTime" BU_SG_REL_ EBS SG_ 2566841879 MinutesUTC_ISig_3 6000;
BA_REL_ "GenSigTimeoutTime" BU_SG_REL_ EBS SG_ 2566841879 MinutesUTC_ISig_3 1500;
BA_REL_ "GenSigFirstTimeoutTime" BU_SG_REL_ BBM SG_ 2566841879 MinutesUTC_ISig_3 6000;
BA_REL_ "GenSigTimeoutTime" BU_SG_REL_ BBM SG_ 2566841879 MinutesUTC_ISig_3 1500;
BA_REL_ "GenSigFirstTimeoutTime" BU_SG_REL_ IC3 SG_ 2566841879 MinutesUTC_ISig_3 6000;
BA_REL_ "GenSigTimeoutTime" BU_SG_REL_ IC3 SG_ 2566841879 MinutesUTC_ISig_3 1500;
BA_REL_ "GenSigFirstTimeoutTime" BU_SG_REL_ VMCU SG_ 2566842094 TachographLocalMinuteOffset_ISig 24000;
BA_REL_ "GenSigTimeoutTime" BU_SG_REL_ VMCU SG_ 2566842094 TachographLocalMinuteOffset_ISig 6000;
BA_REL_ "GenSigFirstTimeoutTime" BU_SG_REL_ BBM SG_ 2566842094 TachographLocalMinuteOffset_ISig 24000;
BA_REL_ "GenSigTimeoutTime" BU_SG_REL_ BBM SG_ 2566842094 TachographLocalMinuteOffset_ISig 6000;
BA_REL_ "GenSigFirstTimeoutTime" BU_SG_REL_ VMCU SG_ 2566842094 TachographMinutes 24000;
BA_REL_ "GenSigTimeoutTime" BU_SG_REL_ VMCU SG_ 2566842094 TachographMinutes 6000;
BA_REL_ "GenSigFirstTimeoutTime" BU_SG_REL_ VMCU SG_ 2566842094 TachographYears 24000;
BA_REL_ "GenSigTimeoutTime" BU_SG_REL_ VMCU SG_ 2566842094 TachographYears 6000;
BA_REL_ "GenSigFirstTimeoutTime" BU_SG_REL_ VMCU SG_ 2566842094 TachographSeconds 24000;
BA_REL_ "GenSigTimeoutTime" BU_SG_REL_ VMCU SG_ 2566842094 TachographSeconds 6000;
BA_REL_ "GenSigFirstTimeoutTime" BU_SG_REL_ VMCU SG_ 2566842094 TachographHours 24000;
BA_REL_ "GenSigTimeoutTime" BU_SG_REL_ VMCU SG_ 2566842094 TachographHours 6000;
BA_REL_ "GenSigFirstTimeoutTime" BU_SG_REL_ VMCU SG_ 2566842094 TachographMonths 24000;
BA_REL_ "GenSigTimeoutTime" BU_SG_REL_ VMCU SG_ 2566842094 TachographMonths 6000;
BA_REL_ "GenSigFirstTimeoutTime" BU_SG_REL_ BBM SG_ 2566842094 TachographLocalHourOffset_ISig_3 24000;
BA_REL_ "GenSigTimeoutTime" BU_SG_REL_ BBM SG_ 2566842094 TachographLocalHourOffset_ISig_3 6000;
BA_REL_ "GenSigFirstTimeoutTime" BU_SG_REL_ VMCU SG_ 2566842094 TachographLocalHourOffset_ISig_3 24000;
BA_REL_ "GenSigTimeoutTime" BU_SG_REL_ VMCU SG_ 2566842094 TachographLocalHourOffset_ISig_3 6000;
BA_REL_ "GenSigFirstTimeoutTime" BU_SG_REL_ VMCU SG_ 2566842094 TachographDays 24000;
BA_REL_ "GenSigTimeoutTime" BU_SG_REL_ VMCU SG_ 2566842094 TachographDays 6000;
BA_REL_ "GenSigFirstTimeoutTime" BU_SG_REL_ BBM SG_ 2365484270 Driver2TimeRelatedStates_ISig_3 3000;
BA_REL_ "GenSigTimeoutTime" BU_SG_REL_ BBM SG_ 2365484270 Driver2TimeRelatedStates_ISig_3 300;
BA_REL_ "GenSigFirstTimeoutTime" BU_SG_REL_ CIOM SG_ 2365484270 Driver2TimeRelatedStates_ISig_3 3000;
BA_REL_ "GenSigTimeoutTime" BU_SG_REL_ CIOM SG_ 2365484270 Driver2TimeRelatedStates_ISig_3 300;
BA_REL_ "GenSigFirstTimeoutTime" BU_SG_REL_ IC3 SG_ 2365484270 Driver2TimeRelatedStates_ISig_3 3000;
BA_REL_ "GenSigTimeoutTime" BU_SG_REL_ IC3 SG_ 2365484270 Driver2TimeRelatedStates_ISig_3 300;
BA_REL_ "GenSigFirstTimeoutTime" BU_SG_REL_ IC3 SG_ 2365484270 VehicleMotion_ISig_3 3000;
BA_REL_ "GenSigTimeoutTime" BU_SG_REL_ IC3 SG_ 2365484270 VehicleMotion_ISig_3 300;
BA_REL_ "GenSigFirstTimeoutTime" BU_SG_REL_ CIOM SG_ 2365484270 VehicleMotion_ISig_3 3000;
BA_REL_ "GenSigTimeoutTime" BU_SG_REL_ CIOM SG_ 2365484270 VehicleMotion_ISig_3 300;
BA_REL_ "GenSigFirstTimeoutTime" BU_SG_REL_ BBM SG_ 2365484270 VehicleMotion_ISig_3 3000;
BA_REL_ "GenSigTimeoutTime" BU_SG_REL_ BBM SG_ 2365484270 VehicleMotion_ISig_3 300;
BA_REL_ "GenSigFirstTimeoutTime" BU_SG_REL_ CIOM SG_ 2365484270 TachographVehicleSpeed_ISig_3 3000;
BA_REL_ "GenSigTimeoutTime" BU_SG_REL_ CIOM SG_ 2365484270 TachographVehicleSpeed_ISig_3 300;
BA_REL_ "GenSigFirstTimeoutTime" BU_SG_REL_ VMCU SG_ 2365484270 TachographVehicleSpeed_ISig_3 3000;
BA_REL_ "GenSigTimeoutTime" BU_SG_REL_ VMCU SG_ 2365484270 TachographVehicleSpeed_ISig_3 300;
BA_REL_ "GenSigFirstTimeoutTime" BU_SG_REL_ BBM SG_ 2365484270 TachographVehicleSpeed_ISig_3 3000;
BA_REL_ "GenSigTimeoutTime" BU_SG_REL_ BBM SG_ 2365484270 TachographVehicleSpeed_ISig_3 300;
BA_REL_ "GenSigFirstTimeoutTime" BU_SG_REL_ IC3 SG_ 2365484270 TachographVehicleSpeed_ISig_3 3000;
BA_REL_ "GenSigTimeoutTime" BU_SG_REL_ IC3 SG_ 2365484270 TachographVehicleSpeed_ISig_3 120;
BA_REL_ "GenSigFirstTimeoutTime" BU_SG_REL_ BBM SG_ 2365484270 TachographPerformance_ISig_3 3000;
BA_REL_ "GenSigTimeoutTime" BU_SG_REL_ BBM SG_ 2365484270 TachographPerformance_ISig_3 300;
BA_REL_ "GenSigFirstTimeoutTime" BU_SG_REL_ CIOM SG_ 2365484270 TachographPerformance_ISig_3 3000;
BA_REL_ "GenSigTimeoutTime" BU_SG_REL_ CIOM SG_ 2365484270 TachographPerformance_ISig_3 300;
BA_REL_ "GenSigFirstTimeoutTime" BU_SG_REL_ IC3 SG_ 2365484270 TachographPerformance_ISig_3 3000;
BA_REL_ "GenSigTimeoutTime" BU_SG_REL_ IC3 SG_ 2365484270 TachographPerformance_ISig_3 300;
BA_REL_ "GenSigFirstTimeoutTime" BU_SG_REL_ VMCU SG_ 2365484270 TachographPerformance_ISig_3 3000;
BA_REL_ "GenSigTimeoutTime" BU_SG_REL_ VMCU SG_ 2365484270 TachographPerformance_ISig_3 300;
BA_REL_ "GenSigFirstTimeoutTime" BU_SG_REL_ BBM SG_ 2365484270 Driver1WorkingState_ISig_3 3000;
BA_REL_ "GenSigTimeoutTime" BU_SG_REL_ BBM SG_ 2365484270 Driver1WorkingState_ISig_3 300;
BA_REL_ "GenSigFirstTimeoutTime" BU_SG_REL_ IC3 SG_ 2365484270 Driver1WorkingState_ISig_3 3000;
BA_REL_ "GenSigTimeoutTime" BU_SG_REL_ IC3 SG_ 2365484270 Driver1WorkingState_ISig_3 300;
BA_REL_ "GenSigFirstTimeoutTime" BU_SG_REL_ CIOM SG_ 2365484270 Driver1WorkingState_ISig_3 3000;
BA_REL_ "GenSigTimeoutTime" BU_SG_REL_ CIOM SG_ 2365484270 Driver1WorkingState_ISig_3 300;
BA_REL_ "GenSigFirstTimeoutTime" BU_SG_REL_ CIOM SG_ 2365484270 Driver1TimeRelatedStates_ISig_3 3000;
BA_REL_ "GenSigTimeoutTime" BU_SG_REL_ CIOM SG_ 2365484270 Driver1TimeRelatedStates_ISig_3 300;
BA_REL_ "GenSigFirstTimeoutTime" BU_SG_REL_ BBM SG_ 2365484270 Driver1TimeRelatedStates_ISig_3 3000;
BA_REL_ "GenSigTimeoutTime" BU_SG_REL_ BBM SG_ 2365484270 Driver1TimeRelatedStates_ISig_3 300;
BA_REL_ "GenSigFirstTimeoutTime" BU_SG_REL_ IC3 SG_ 2365484270 Driver1TimeRelatedStates_ISig_3 3000;
BA_REL_ "GenSigTimeoutTime" BU_SG_REL_ IC3 SG_ 2365484270 Driver1TimeRelatedStates_ISig_3 300;
BA_REL_ "GenSigFirstTimeoutTime" BU_SG_REL_ CIOM SG_ 2365484270 DriverCardDriver2_ISig_3 3000;
BA_REL_ "GenSigTimeoutTime" BU_SG_REL_ CIOM SG_ 2365484270 DriverCardDriver2_ISig_3 300;
BA_REL_ "GenSigFirstTimeoutTime" BU_SG_REL_ BBM SG_ 2365484270 DriverCardDriver2_ISig_3 3000;
BA_REL_ "GenSigTimeoutTime" BU_SG_REL_ BBM SG_ 2365484270 DriverCardDriver2_ISig_3 300;
BA_REL_ "GenSigFirstTimeoutTime" BU_SG_REL_ IC3 SG_ 2365484270 DriverCardDriver2_ISig_3 3000;
BA_REL_ "GenSigTimeoutTime" BU_SG_REL_ IC3 SG_ 2365484270 DriverCardDriver2_ISig_3 300;
BA_REL_ "GenSigFirstTimeoutTime" BU_SG_REL_ VMCU SG_ 2365484270 TachographOutputShaftSpeed_ISig_ 3000;
BA_REL_ "GenSigTimeoutTime" BU_SG_REL_ VMCU SG_ 2365484270 TachographOutputShaftSpeed_ISig_ 300;
BA_REL_ "GenSigFirstTimeoutTime" BU_SG_REL_ BBM SG_ 2365484270 TachographOutputShaftSpeed_ISig_ 3000;
BA_REL_ "GenSigTimeoutTime" BU_SG_REL_ BBM SG_ 2365484270 TachographOutputShaftSpeed_ISig_ 300;
BA_REL_ "GenSigFirstTimeoutTime" BU_SG_REL_ CIOM SG_ 2365484270 HandlingInformation_ISig_3 3000;
BA_REL_ "GenSigTimeoutTime" BU_SG_REL_ CIOM SG_ 2365484270 HandlingInformation_ISig_3 300;
BA_REL_ "GenSigFirstTimeoutTime" BU_SG_REL_ VMCU SG_ 2365484270 HandlingInformation_ISig_3 3000;
BA_REL_ "GenSigTimeoutTime" BU_SG_REL_ VMCU SG_ 2365484270 HandlingInformation_ISig_3 300;
BA_REL_ "GenSigFirstTimeoutTime" BU_SG_REL_ IC3 SG_ 2365484270 HandlingInformation_ISig_3 3000;
BA_REL_ "GenSigTimeoutTime" BU_SG_REL_ IC3 SG_ 2365484270 HandlingInformation_ISig_3 300;
BA_REL_ "GenSigFirstTimeoutTime" BU_SG_REL_ BBM SG_ 2365484270 HandlingInformation_ISig_3 3000;
BA_REL_ "GenSigTimeoutTime" BU_SG_REL_ BBM SG_ 2365484270 HandlingInformation_ISig_3 300;
BA_REL_ "GenSigFirstTimeoutTime" BU_SG_REL_ CIOM SG_ 2365484270 DriverCardDriver1_ISig_3 3000;
BA_REL_ "GenSigTimeoutTime" BU_SG_REL_ CIOM SG_ 2365484270 DriverCardDriver1_ISig_3 300;
BA_REL_ "GenSigFirstTimeoutTime" BU_SG_REL_ VMCU SG_ 2365484270 DriverCardDriver1_ISig_3 3000;
BA_REL_ "GenSigTimeoutTime" BU_SG_REL_ VMCU SG_ 2365484270 DriverCardDriver1_ISig_3 300;
BA_REL_ "GenSigFirstTimeoutTime" BU_SG_REL_ IC3 SG_ 2365484270 DriverCardDriver1_ISig_3 3000;
BA_REL_ "GenSigTimeoutTime" BU_SG_REL_ IC3 SG_ 2365484270 DriverCardDriver1_ISig_3 300;
BA_REL_ "GenSigFirstTimeoutTime" BU_SG_REL_ BBM SG_ 2365484270 DriverCardDriver1_ISig_3 3000;
BA_REL_ "GenSigTimeoutTime" BU_SG_REL_ BBM SG_ 2365484270 DriverCardDriver1_ISig_3 300;
BA_REL_ "GenSigFirstTimeoutTime" BU_SG_REL_ DACU SG_ 2365484270 DriverCardDriver1_ISig_3 3000;
BA_REL_ "GenSigTimeoutTime" BU_SG_REL_ DACU SG_ 2365484270 DriverCardDriver1_ISig_3 120;
BA_REL_ "GenSigFirstTimeoutTime" BU_SG_REL_ IC3 SG_ 2365484270 SystemEvent_ISig_3 3000;
BA_REL_ "GenSigTimeoutTime" BU_SG_REL_ IC3 SG_ 2365484270 SystemEvent_ISig_3 300;
BA_REL_ "GenSigFirstTimeoutTime" BU_SG_REL_ BBM SG_ 2365484270 SystemEvent_ISig_3 3000;
BA_REL_ "GenSigTimeoutTime" BU_SG_REL_ BBM SG_ 2365484270 SystemEvent_ISig_3 300;
BA_REL_ "GenSigFirstTimeoutTime" BU_SG_REL_ VMCU SG_ 2365484270 SystemEvent_ISig_3 3000;
BA_REL_ "GenSigTimeoutTime" BU_SG_REL_ VMCU SG_ 2365484270 SystemEvent_ISig_3 300;
BA_REL_ "GenSigFirstTimeoutTime" BU_SG_REL_ CIOM SG_ 2365484270 SystemEvent_ISig_3 3000;
BA_REL_ "GenSigTimeoutTime" BU_SG_REL_ CIOM SG_ 2365484270 SystemEvent_ISig_3 300;
BA_REL_ "GenSigFirstTimeoutTime" BU_SG_REL_ CIOM SG_ 2365484270 VehicleOverspeed_ISig_3 3000;
BA_REL_ "GenSigTimeoutTime" BU_SG_REL_ CIOM SG_ 2365484270 VehicleOverspeed_ISig_3 300;
BA_REL_ "GenSigFirstTimeoutTime" BU_SG_REL_ BBM SG_ 2365484270 VehicleOverspeed_ISig_3 3000;
BA_REL_ "GenSigTimeoutTime" BU_SG_REL_ BBM SG_ 2365484270 VehicleOverspeed_ISig_3 300;
BA_REL_ "GenSigFirstTimeoutTime" BU_SG_REL_ IC3 SG_ 2365484270 VehicleOverspeed_ISig_3 3000;
BA_REL_ "GenSigTimeoutTime" BU_SG_REL_ IC3 SG_ 2365484270 VehicleOverspeed_ISig_3 300;
BA_REL_ "GenSigFirstTimeoutTime" BU_SG_REL_ CIOM SG_ 2365484270 Driver2WorkingState_ISig_3 3000;
BA_REL_ "GenSigTimeoutTime" BU_SG_REL_ CIOM SG_ 2365484270 Driver2WorkingState_ISig_3 300;
BA_REL_ "GenSigFirstTimeoutTime" BU_SG_REL_ BBM SG_ 2365484270 Driver2WorkingState_ISig_3 3000;
BA_REL_ "GenSigTimeoutTime" BU_SG_REL_ BBM SG_ 2365484270 Driver2WorkingState_ISig_3 300;
BA_REL_ "GenSigFirstTimeoutTime" BU_SG_REL_ IC3 SG_ 2365484270 Driver2WorkingState_ISig_3 3000;
BA_REL_ "GenSigTimeoutTime" BU_SG_REL_ IC3 SG_ 2365484270 Driver2WorkingState_ISig_3 300;
BA_REL_ "GenSigFirstTimeoutTime" BU_SG_REL_ TACHO SG_ 2565533233 PGNReq_Tacho_CIOM 65000;
BA_REL_ "GenSigTimeoutTime" BU_SG_REL_ TACHO SG_ 2565533233 PGNReq_Tacho_CIOM 65000;
BA_REL_ "GenSigFirstTimeoutTime" BU_SG_REL_ IC3 SG_ 2499792656 DrivelineRetarderStat 3000;
BA_REL_ "GenSigTimeoutTime" BU_SG_REL_ IC3 SG_ 2499792656 DrivelineRetarderStat 900;
BA_REL_ "GenSigFirstTimeoutTime" BU_SG_REL_ EBS SG_ 2566840592 DrivelineRetarderRefTorque 65000;
BA_REL_ "GenSigTimeoutTime" BU_SG_REL_ EBS SG_ 2566840592 DrivelineRetarderRefTorque 30000;
BA_REL_ "GenSigFirstTimeoutTime" BU_SG_REL_ VMCU SG_ 2566840592 DrivelineRetarderRefTorque 65000;
BA_REL_ "GenSigTimeoutTime" BU_SG_REL_ VMCU SG_ 2566840592 DrivelineRetarderRefTorque 30000;
BA_REL_ "GenSigFirstTimeoutTime" BU_SG_REL_ DACU SG_ 2566840592 DrivelineRetarderRefTorque 65000;
BA_REL_ "GenSigTimeoutTime" BU_SG_REL_ DACU SG_ 2566840592 DrivelineRetarderRefTorque 30000;
BA_REL_ "GenSigFirstTimeoutTime" BU_SG_REL_ TECU SG_ 2566840592 DrivelineRetarderRefTorque 60000;
BA_REL_ "GenSigTimeoutTime" BU_SG_REL_ TECU SG_ 2566840592 DrivelineRetarderRefTorque 30000;
BA_REL_ "GenSigFirstTimeoutTime" BU_SG_REL_ EMS SG_ 2566840592 DrivelineRetarderRefTorque 65000;
BA_REL_ "GenSigTimeoutTime" BU_SG_REL_ EMS SG_ 2566840592 DrivelineRetarderRefTorque 30000;
BA_REL_ "GenSigFirstTimeoutTime" BU_SG_REL_ EMS SG_ 2566840592 DrivelineRetarderLocation 65000;
BA_REL_ "GenSigTimeoutTime" BU_SG_REL_ EMS SG_ 2566840592 DrivelineRetarderLocation 30000;
BA_REL_ "GenSigFirstTimeoutTime" BU_SG_REL_ DACU SG_ 2566840592 DrivelineRetarderLocation 65000;
BA_REL_ "GenSigTimeoutTime" BU_SG_REL_ DACU SG_ 2566840592 DrivelineRetarderLocation 30000;
BA_REL_ "GenSigFirstTimeoutTime" BU_SG_REL_ EBS SG_ 2566840592 DrivelineRetarderLocation 65000;
BA_REL_ "GenSigTimeoutTime" BU_SG_REL_ EBS SG_ 2566840592 DrivelineRetarderLocation 30000;
BA_REL_ "GenSigFirstTimeoutTime" BU_SG_REL_ EBS SG_ 2566840592 DrivelineRetarderType 65000;
BA_REL_ "GenSigTimeoutTime" BU_SG_REL_ EBS SG_ 2566840592 DrivelineRetarderType 30000;
BA_REL_ "GenSigFirstTimeoutTime" BU_SG_REL_ TECU SG_ 2566840591 EngRetConf_RetCtrlMethod 65000;
BA_REL_ "GenSigTimeoutTime" BU_SG_REL_ TECU SG_ 2566840591 EngRetConf_RetCtrlMethod 30000;
BA_REL_ "GenSigFirstTimeoutTime" BU_SG_REL_ TECU SG_ 2566840591 EngRetConf_RetSpeedAtP4 65000;
BA_REL_ "GenSigTimeoutTime" BU_SG_REL_ TECU SG_ 2566840591 EngRetConf_RetSpeedAtP4 30000;
BA_REL_ "GenSigFirstTimeoutTime" BU_SG_REL_ TECU SG_ 2566840591 EngRetConf_MaxRetSpeedP2 65000;
BA_REL_ "GenSigTimeoutTime" BU_SG_REL_ TECU SG_ 2566840591 EngRetConf_MaxRetSpeedP2 30000;
BA_REL_ "GenSigFirstTimeoutTime" BU_SG_REL_ TECU SG_ 2566840591 EngRetConf_PerTrqAtP3 65000;
BA_REL_ "GenSigTimeoutTime" BU_SG_REL_ TECU SG_ 2566840591 EngRetConf_PerTrqAtP3 30000;
BA_REL_ "GenSigFirstTimeoutTime" BU_SG_REL_ TECU SG_ 2566840591 EngRetConf_RetSpeedAtP5 65000;
BA_REL_ "GenSigTimeoutTime" BU_SG_REL_ TECU SG_ 2566840591 EngRetConf_RetSpeedAtP5 30000;
BA_REL_ "GenSigFirstTimeoutTime" BU_SG_REL_ TECU SG_ 2566840591 EngRetConf_speedAtIdleP1 65000;
BA_REL_ "GenSigTimeoutTime" BU_SG_REL_ TECU SG_ 2566840591 EngRetConf_speedAtIdleP1 30000;
BA_REL_ "GenSigFirstTimeoutTime" BU_SG_REL_ TECU SG_ 2566840591 EngRetConf_PerTrqAtP4 65000;
BA_REL_ "GenSigTimeoutTime" BU_SG_REL_ TECU SG_ 2566840591 EngRetConf_PerTrqAtP4 30000;
BA_REL_ "GenSigFirstTimeoutTime" BU_SG_REL_ VMCU SG_ 2566840591 ReferenceEngineRetarderTorque 65000;
BA_REL_ "GenSigTimeoutTime" BU_SG_REL_ VMCU SG_ 2566840591 ReferenceEngineRetarderTorque 30000;
BA_REL_ "GenSigFirstTimeoutTime" BU_SG_REL_ EBS SG_ 2566840591 ReferenceEngineRetarderTorque 65000;
BA_REL_ "GenSigTimeoutTime" BU_SG_REL_ EBS SG_ 2566840591 ReferenceEngineRetarderTorque 30000;
BA_REL_ "GenSigFirstTimeoutTime" BU_SG_REL_ DACU SG_ 2566840591 ReferenceEngineRetarderTorque 65000;
BA_REL_ "GenSigTimeoutTime" BU_SG_REL_ DACU SG_ 2566840591 ReferenceEngineRetarderTorque 30000;
BA_REL_ "GenSigFirstTimeoutTime" BU_SG_REL_ RECU_Virt SG_ 2566840591 ReferenceEngineRetarderTorque 65000;
BA_REL_ "GenSigTimeoutTime" BU_SG_REL_ RECU_Virt SG_ 2566840591 ReferenceEngineRetarderTorque 30000;
BA_REL_ "GenSigFirstTimeoutTime" BU_SG_REL_ TECU SG_ 2566840591 ReferenceEngineRetarderTorque 65000;
BA_REL_ "GenSigTimeoutTime" BU_SG_REL_ TECU SG_ 2566840591 ReferenceEngineRetarderTorque 30000;
BA_REL_ "GenSigFirstTimeoutTime" BU_SG_REL_ TECU SG_ 2566840591 EngRetConf_PerTrqAtIdleP1 65000;
BA_REL_ "GenSigTimeoutTime" BU_SG_REL_ TECU SG_ 2566840591 EngRetConf_PerTrqAtIdleP1 30000;
BA_REL_ "GenSigFirstTimeoutTime" BU_SG_REL_ TECU SG_ 2566840591 EngRetConf_RetSpeedAtP3 65000;
BA_REL_ "GenSigTimeoutTime" BU_SG_REL_ TECU SG_ 2566840591 EngRetConf_RetSpeedAtP3 30000;
BA_REL_ "GenSigFirstTimeoutTime" BU_SG_REL_ TECU SG_ 2566840591 EngRetConf_PerTrqAtMaxSpeedP2 65000;
BA_REL_ "GenSigTimeoutTime" BU_SG_REL_ TECU SG_ 2566840591 EngRetConf_PerTrqAtMaxSpeedP2 30000;
BA_REL_ "GenSigFirstTimeoutTime" BU_SG_REL_ TECU SG_ 2566840591 EngRetConf_PerTrqAtP5 65000;
BA_REL_ "GenSigTimeoutTime" BU_SG_REL_ TECU SG_ 2566840591 EngRetConf_PerTrqAtP5 30000;
VAL_ 2348814353 TSC1RECUVMCU_EnOvrdCtrlM 3 "TSC1EngOverrideCtrlMode_SpeedTorqueLimitControl" 2 "TSC1EngOverrideCtrlMode_TorqueControl" 1 "TSC1EngOverrideCtrlMode_SpeedControl" 0 "TSC1EngOverrideCtrlMode_OverrideDisabled" ;
VAL_ 2348814353 TSC1RECUVMCU_EnRSpdCtrlC 3 "TSC1EngReqSpeedCtrlCond_StabilityOptDrvlnEngLockup2" 2 "TSC1EngReqSpeedCtrlCond_StabilityOptDrvlnEngLockup1" 1 "TSC1EngReqSpeedCtrlCond_StabilityOptDrvlnDisengNonLockup" 0 "TSC1EngReqSpeedCtrlCond_TransientOptimized" ;
VAL_ 2348814353 TSC1RECUVMCU_OvrdCtrlMPr 3 "Priority_LowPriority" 2 "Priority_MediumPriority" 1 "Priority_HighPriority" 0 "Priority_HighestPriority" ;
VAL_ 2348814339 TSC1RECUTECU_EnOvrdCtrlM 3 "TSC1EngOverrideCtrlMode_SpeedTorqueLimitControl" 2 "TSC1EngOverrideCtrlMode_TorqueControl" 1 "TSC1EngOverrideCtrlMode_SpeedControl" 0 "TSC1EngOverrideCtrlMode_OverrideDisabled" ;
VAL_ 2348814339 TSC1RECUTECU_OvrdCtrlMPr 3 "Priority_LowPriority" 2 "Priority_MediumPriority" 1 "Priority_HighPriority" 0 "Priority_HighestPriority" ;
VAL_ 2348814339 TSC1RECUTECU_EnRSpdCtrlC 3 "TSC1EngReqSpeedCtrlCond_StabilityOptDrvlnEngLockup2" 2 "TSC1EngReqSpeedCtrlCond_StabilityOptDrvlnEngLockup1" 1 "TSC1EngReqSpeedCtrlCond_StabilityOptDrvlnDisengNonLockup" 0 "TSC1EngReqSpeedCtrlCond_TransientOptimized" ;
VAL_ 2348814337 TSC1RECUEMSdap_OvrdCtrlMPr 3 "Priority_LowPriority" 2 "Priority_MediumPriority" 1 "Priority_HighPriority" 0 "Priority_HighestPriority" ;
VAL_ 2348814337 TSC1RECUEMSdap_EnOvrdCtrlM 3 "TSC1EngOverrideCtrlMode_SpeedTorqueLimitControl" 2 "TSC1EngOverrideCtrlMode_TorqueControl" 1 "TSC1EngOverrideCtrlMode_SpeedControl" 0 "TSC1EngOverrideCtrlMode_OverrideDisabled" ;
VAL_ 2348814337 TSC1RECUEMSdap_EnRSpdCtrlC 3 "TSC1EngReqSpeedCtrlCond_StabilityOptDrvlnEngLockup2" 2 "TSC1EngReqSpeedCtrlCond_StabilityOptDrvlnEngLockup1" 1 "TSC1EngReqSpeedCtrlCond_StabilityOptDrvlnDisengNonLockup" 0 "TSC1EngReqSpeedCtrlCond_TransientOptimized" ;
VAL_ 2348814336 TSC1RECUEMSccb_EnRSpdCtrlC 3 "TSC1EngReqSpeedCtrlCond_StabilityOptDrvlnEngLockup2" 2 "TSC1EngReqSpeedCtrlCond_StabilityOptDrvlnEngLockup1" 1 "TSC1EngReqSpeedCtrlCond_StabilityOptDrvlnDisengNonLockup" 0 "TSC1EngReqSpeedCtrlCond_TransientOptimized" ;
VAL_ 2348814336 TSC1RECUEMSccb_EnOvrdCtrlM 3 "TSC1EngOverrideCtrlMode_SpeedTorqueLimitControl" 2 "TSC1EngOverrideCtrlMode_TorqueControl" 1 "TSC1EngOverrideCtrlMode_SpeedControl" 0 "TSC1EngOverrideCtrlMode_OverrideDisabled" ;
VAL_ 2348814336 TSC1RECUEMSccb_OvrdCtrlMPr 3 "Priority_LowPriority" 2 "Priority_MediumPriority" 1 "Priority_HighPriority" 0 "Priority_HighestPriority" ;
VAL_ 2348814347 TSC1RECUABS_EnOvrdCtrlM 3 "TSC1EngOverrideCtrlMode_SpeedTorqueLimitControl" 2 "TSC1EngOverrideCtrlMode_TorqueControl" 1 "TSC1EngOverrideCtrlMode_SpeedControl" 0 "TSC1EngOverrideCtrlMode_OverrideDisabled" ;
VAL_ 2348814347 TSC1RECUABS_OvrdCtrlMPr 3 "Priority_LowPriority" 2 "Priority_MediumPriority" 1 "Priority_HighPriority" 0 "Priority_HighestPriority" ;
VAL_ 2348814347 TSC1RECUABS_EnRSpdCtrlC 3 "TSC1EngReqSpeedCtrlCond_StabilityOptDrvlnEngLockup2" 2 "TSC1EngReqSpeedCtrlCond_StabilityOptDrvlnEngLockup1" 1 "TSC1EngReqSpeedCtrlCond_StabilityOptDrvlnDisengNonLockup" 0 "TSC1EngReqSpeedCtrlCond_TransientOptimized" ;
VAL_ 2348810257 TSC1EMSVMCUtr_EnOvrdCtrlM 3 "TSC1EngOverrideCtrlMode_SpeedTorqueLimitControl" 2 "TSC1EngOverrideCtrlMode_TorqueControl" 1 "TSC1EngOverrideCtrlMode_SpeedControl" 0 "TSC1EngOverrideCtrlMode_OverrideDisabled" ;
VAL_ 2348810257 TSC1EMSVMCUtr_EnRSpdCtrlC 3 "TSC1EngReqSpeedCtrlCond_StabilityOptDrvlnEngLockup2" 2 "TSC1EngReqSpeedCtrlCond_StabilityOptDrvlnEngLockup1" 1 "TSC1EngReqSpeedCtrlCond_StabilityOptDrvlnDisengNonLockup" 0 "TSC1EngReqSpeedCtrlCond_TransientOptimized" ;
VAL_ 2348810257 TSC1EMSVMCUtr_OvrdCtrlMPr 3 "Priority_LowPriority" 2 "Priority_MediumPriority" 1 "Priority_HighPriority" 0 "Priority_HighestPriority" ;
VAL_ 2348810288 TSC1EMSVMCUes_OvrdCtrlMPr 3 "Priority_LowPriority" 2 "Priority_MediumPriority" 1 "Priority_HighPriority" 0 "Priority_HighestPriority" ;
VAL_ 2348810288 TSC1EMSVMCUes_EnOvrdCtrlM 3 "TSC1EngOverrideCtrlMode_SpeedTorqueLimitControl" 2 "TSC1EngOverrideCtrlMode_TorqueControl" 1 "TSC1EngOverrideCtrlMode_SpeedControl" 0 "TSC1EngOverrideCtrlMode_OverrideDisabled" ;
VAL_ 2348810288 TSC1EMSVMCUes_EnRSpdCtrlC 3 "TSC1EngReqSpeedCtrlCond_StabilityOptDrvlnEngLockup2" 2 "TSC1EngReqSpeedCtrlCond_StabilityOptDrvlnEngLockup1" 1 "TSC1EngReqSpeedCtrlCond_StabilityOptDrvlnDisengNonLockup" 0 "TSC1EngReqSpeedCtrlCond_TransientOptimized" ;
VAL_ 2348810243 TSC1EMSTECU_EnOvrdCtrlM 3 "TSC1EngOverrideCtrlMode_SpeedTorqueLimitControl" 2 "TSC1EngOverrideCtrlMode_TorqueControl" 1 "TSC1EngOverrideCtrlMode_SpeedControl" 0 "TSC1EngOverrideCtrlMode_OverrideDisabled" ;
VAL_ 2348810243 TSC1EMSTECU_OvrdCtrlMPr 3 "Priority_LowPriority" 2 "Priority_MediumPriority" 1 "Priority_HighPriority" 0 "Priority_HighestPriority" ;
VAL_ 2348810243 TSC1EMSTECU_EnRSpdCtrlC 3 "TSC1EngReqSpeedCtrlCond_StabilityOptDrvlnEngLockup2" 2 "TSC1EngReqSpeedCtrlCond_StabilityOptDrvlnEngLockup1" 1 "TSC1EngReqSpeedCtrlCond_StabilityOptDrvlnDisengNonLockup" 0 "TSC1EngReqSpeedCtrlCond_TransientOptimized" ;
VAL_ 2348810251 TSC1EMSABS_EnRSpdCtrlC 3 "TSC1EngReqSpeedCtrlCond_StabilityOptDrvlnEngLockup2" 2 "TSC1EngReqSpeedCtrlCond_StabilityOptDrvlnEngLockup1" 1 "TSC1EngReqSpeedCtrlCond_StabilityOptDrvlnDisengNonLockup" 0 "TSC1EngReqSpeedCtrlCond_TransientOptimized" ;
VAL_ 2348810251 TSC1EMSABS_OvrdCtrlMPr 3 "Priority_LowPriority" 2 "Priority_MediumPriority" 1 "Priority_HighPriority" 0 "Priority_HighestPriority" ;
VAL_ 2348810251 TSC1EMSABS_EnOvrdCtrlM 3 "TSC1EngOverrideCtrlMode_SpeedTorqueLimitControl" 2 "TSC1EngOverrideCtrlMode_TorqueControl" 1 "TSC1EngOverrideCtrlMode_SpeedControl" 0 "TSC1EngOverrideCtrlMode_OverrideDisabled" ;
VAL_ 2348810413 TSC1EMSDACU_OvrdCtrlMPr 3 "Priority_LowPriority" 2 "Priority_MediumPriority" 1 "Priority_HighPriority" 0 "Priority_HighestPriority" ;
VAL_ 2348810413 TSC1EMSDACU_EnRSpdCtrlC 3 "TSC1EngReqSpeedCtrlCond_StabilityOptDrvlnEngLockup2" 2 "TSC1EngReqSpeedCtrlCond_StabilityOptDrvlnEngLockup1" 1 "TSC1EngReqSpeedCtrlCond_StabilityOptDrvlnDisengNonLockup" 0 "TSC1EngReqSpeedCtrlCond_TransientOptimized" ;
VAL_ 2348810413 TSC1EMSDACU_EnOvrdCtrlM 3 "TSC1EngOverrideCtrlMode_SpeedTorqueLimitControl" 2 "TSC1EngOverrideCtrlMode_TorqueControl" 1 "TSC1EngOverrideCtrlMode_SpeedControl" 0 "TSC1EngOverrideCtrlMode_OverrideDisabled" ;
VAL_ 2348814097 TSC1EMSrVMCU_EnRSpdCtrlC 3 "TSC1EngReqSpeedCtrlCond_StabilityOptDrvlnEngLockup2" 2 "TSC1EngReqSpeedCtrlCond_StabilityOptDrvlnEngLockup1" 1 "TSC1EngReqSpeedCtrlCond_StabilityOptDrvlnDisengNonLockup" 0 "TSC1EngReqSpeedCtrlCond_TransientOptimized" ;
VAL_ 2348814097 TSC1EMSrVMCU_OvrdCtrlMPr 3 "Priority_LowPriority" 2 "Priority_MediumPriority" 1 "Priority_HighPriority" 0 "Priority_HighestPriority" ;
VAL_ 2348814097 TSC1EMSrVMCU_EnOvrdCtrlM 3 "TSC1EngOverrideCtrlMode_SpeedTorqueLimitControl" 2 "TSC1EngOverrideCtrlMode_TorqueControl" 1 "TSC1EngOverrideCtrlMode_SpeedControl" 0 "TSC1EngOverrideCtrlMode_OverrideDisabled" ;
VAL_ 2348814083 TSC1EMSrTECU_OvrdCtrlMPr 3 "Priority_LowPriority" 2 "Priority_MediumPriority" 1 "Priority_HighPriority" 0 "Priority_HighestPriority" ;
VAL_ 2348814083 TSC1EMSrTECU_EnRSpdCtrlC 3 "TSC1EngReqSpeedCtrlCond_StabilityOptDrvlnEngLockup2" 2 "TSC1EngReqSpeedCtrlCond_StabilityOptDrvlnEngLockup1" 1 "TSC1EngReqSpeedCtrlCond_StabilityOptDrvlnDisengNonLockup" 0 "TSC1EngReqSpeedCtrlCond_TransientOptimized" ;
VAL_ 2348814083 TSC1EMSrTECU_EnOvrdCtrlM 3 "TSC1EngOverrideCtrlMode_SpeedTorqueLimitControl" 2 "TSC1EngOverrideCtrlMode_TorqueControl" 1 "TSC1EngOverrideCtrlMode_SpeedControl" 0 "TSC1EngOverrideCtrlMode_OverrideDisabled" ;
VAL_ 2348814091 TSC1EMSrABS_EnRSpdCtrlC 3 "TSC1EngReqSpeedCtrlCond_StabilityOptDrvlnEngLockup2" 2 "TSC1EngReqSpeedCtrlCond_StabilityOptDrvlnEngLockup1" 1 "TSC1EngReqSpeedCtrlCond_StabilityOptDrvlnDisengNonLockup" 0 "TSC1EngReqSpeedCtrlCond_TransientOptimized" ;
VAL_ 2348814091 TSC1EMSrABS_OvrdCtrlMPr 3 "Priority_LowPriority" 2 "Priority_MediumPriority" 1 "Priority_HighPriority" 0 "Priority_HighestPriority" ;
VAL_ 2348814091 TSC1EMSrABS_EnOvrdCtrlM 3 "TSC1EngOverrideCtrlMode_SpeedTorqueLimitControl" 2 "TSC1EngOverrideCtrlMode_TorqueControl" 1 "TSC1EngOverrideCtrlMode_SpeedControl" 0 "TSC1EngOverrideCtrlMode_OverrideDisabled" ;
VAL_ 2566882307 LowTempClutchInfo 3 "Warning_NotAvailable" 2 "Warning_Error" 1 "Warning_Warning" 0 "Warning_NoWarning" ;
VAL_ 2566882307 TransmEngineCrankEnable_ISig_3 3 "DisableEnable_NotAvailable" 2 "DisableEnable_Error" 1 "DisableEnable_Enable" 0 "DisableEnable_Disable" ;
VAL_ 2365484270 Driver2TimeRelatedStates_ISig_3 15 "DriverTimeRelatedStates_NotAvailable" 14 "DriverTimeRelatedStates_Error" 13 "DriverTimeRelatedStates_Other" 12 "DriverTimeRelatedStates_Reserved_05" 11 "DriverTimeRelatedStates_Reserved_04" 10 "DriverTimeRelatedStates_Reserved_03" 9 "DriverTimeRelatedStates_Reserved_02" 8 "DriverTimeRelatedStates_Reserved_01" 7 "DriverTimeRelatedStates_Reserved" 6 "DriverTimeRelatedStates_Limit6_16hReached" 5 "DriverTimeRelatedStates_Limit5_15MinutesBefore16h" 4 "DriverTimeRelatedStates_Limit4_9hReached" 3 "DriverTimeRelatedStates_Limit3_15MinutesBefore9h" 2 "DriverTimeRelatedStates_Limit2_4h30minReached" 1 "DriverTimeRelatedStates_Limit1_15minBefore4h30min" 0 "DriverTimeRelatedStates_NormalNoLimitsReached" ;
VAL_ 2365484270 VehicleMotion_ISig_3 3 "NotDetected_NotAvaliable" 2 "NotDetected_Error" 1 "NotDetected_Detected" 0 "NotDetected_NotDetected" ;
VAL_ 2365484270 TachographPerformance_ISig_3 3 "TachographPerformance_NotAvailable" 2 "TachographPerformance_Error" 1 "TachographPerformance_PerformanceAnalysis" 0 "TachographPerformance_NormalPerformance" ;
VAL_ 2365484270 Driver1WorkingState_ISig_3 7 "DriverWorkingState_NotAvailable" 6 "DriverWorkingState_ErrorIndicator" 5 "DriverWorkingState_Reserved_01" 4 "DriverWorkingState_Reserved" 3 "DriverWorkingState_DriveBehindWheel" 2 "DriverWorkingState_WorkLoadingUnloadingWorkingInAnOffice" 1 "DriverWorkingState_DriverAvailableShortBreak" 0 "DriverWorkingState_RestSleeping" ;
VAL_ 2365484270 Driver1TimeRelatedStates_ISig_3 15 "Driver1TimeRelatedStates_NotAvailable" 14 "Driver1TimeRelatedStates_Error" 13 "Driver1TimeRelatedStates_Other" 12 "Driver1TimeRelatedStates_NextMandatoryDriver1CardDownload" 11 "Driver1TimeRelatedStates_Driver1CardExpiryWarning" 10 "Driver1TimeRelatedStates_2WeekDrivingTimeWarning" 9 "Driver1TimeRelatedStates_2WeekDrivingTimePreWarning" 8 "Driver1TimeRelatedStates_WeeklyDrivingTimeWarning" 7 "Driver1TimeRelatedStates_WeeklyDrivingTimePreWarning" 6 "Driver1TimeRelatedStates_DailyWeeklyRestWarning" 5 "Driver1TimeRelatedStates_DailyWeeklyRestPreWarning" 4 "Driver1TimeRelatedStates_DailyDrivingTimeWarning" 3 "Driver1TimeRelatedStates_DailyDrivingTimePreWarning" 2 "Driver1TimeRelatedStates_4h30minReached" 1 "Driver1TimeRelatedStates_15minBefore4h30min" 0 "Driver1TimeRelatedStates_NormalNoLimitsReached" ;
VAL_ 2365484270 DriverCardDriver2_ISig_3 3 "NotPresentPresent_NotAvailable" 2 "NotPresentPresent_ErrorIndicator" 1 "NotPresentPresent_Present" 0 "NotPresentPresent_NotPresent" ;
VAL_ 2365484270 HandlingInformation_ISig_3 3 "HandlingInformation_NotAvailable" 2 "HandlingInformation_Error" 1 "HandlingInformation_HandlingInformation" 0 "HandlingInformation_NoHandlingInformation" ;
VAL_ 2365484270 DriverCardDriver1_ISig_3 3 "NotPresentPresent_NotAvailable" 2 "NotPresentPresent_ErrorIndicator" 1 "NotPresentPresent_Present" 0 "NotPresentPresent_NotPresent" ;
VAL_ 2365484270 SystemEvent_ISig_3 3 "SystemEvent_NotAvailable" 2 "SystemEvent_Error" 1 "SystemEvent_TachographEvent" 0 "SystemEvent_NoTachographEvent" ;
VAL_ 2365484270 VehicleOverspeed_ISig_3 3 "VehicleOverspeed_NotAvailable" 2 "VehicleOverspeed_PreOverspeed" 1 "VehicleOverspeed_Overspeed" 0 "VehicleOverspeed_NoOverspeed" ;
VAL_ 2365484270 Driver2WorkingState_ISig_3 7 "DriverWorkingState_NotAvailable" 6 "DriverWorkingState_ErrorIndicator" 5 "DriverWorkingState_Reserved_01" 4 "DriverWorkingState_Reserved" 3 "DriverWorkingState_DriveBehindWheel" 2 "DriverWorkingState_WorkLoadingUnloadingWorkingInAnOffice" 1 "DriverWorkingState_DriverAvailableShortBreak" 0 "DriverWorkingState_RestSleeping" ;
VAL_ 2499792656 DrivelineRetarderStat 3 "DrivelineRetarderStat_NotAvailable" 2 "DrivelineRetarderStat_Error" 1 "DrivelineRetarderStat_RetarderCapacityDerated" 0 "DrivelineRetarderStat_RetarderCapacityNotDerated" ;
VAL_ 2566840592 DrivelineRetarderLocation 15 "DrivelineRetarderLocation_NotAvailable" 14 "DrivelineRetarderLocation_Other" 13 "DrivelineRetarderLocation_NotDefined_07" 12 "DrivelineRetarderLocation_NotDefined_06" 11 "DrivelineRetarderLocation_NotDefined_05" 10 "DrivelineRetarderLocation_NotDefined_04" 9 "DrivelineRetarderLocation_NotDefined_03" 8 "DrivelineRetarderLocation_NotDefined_02" 7 "DrivelineRetarderLocation_NotDefined_01" 6 "DrivelineRetarderLocation_NotDefined" 5 "DrivelineRetarderLocation_TrailerVehicleSpeed" 4 "DrivelineRetarderLocation_SecondaryDrivelineOutputShaftRpm" 3 "DrivelineRetarderLocation_SecondaryTransmissionOutput" 2 "DrivelineRetarderLocation_PrimaryTransmissionInputEngineRpm" 1 "DrivelineRetarderLocation_PrimaryEngineExhaustBrake" 0 "DrivelineRetarderLocation_PrimaryEngineCompressionReleaseBrake" ;
VAL_ 2566840592 DrivelineRetarderType 15 "DrivelineRetarderType_NotAvailable" 14 "DrivelineRetarderType_Other" 13 "DrivelineRetarderType_NotDefined_08" 12 "DrivelineRetarderType_NotDefined_07" 11 "DrivelineRetarderType_NotDefined_06" 10 "DrivelineRetarderType_NotDefined_05" 9 "DrivelineRetarderType_NotDefined_04" 8 "DrivelineRetarderType_NotDefined_03" 7 "DrivelineRetarderType_NotDefined_02" 6 "DrivelineRetarderType_NotDefined_01" 5 "DrivelineRetarderType_NotDefined" 4 "DrivelineRetarderType_Exhaust" 3 "DrivelineRetarderType_CompressionRelease" 2 "DrivelineRetarderType_CooledFriction" 1 "DrivelineRetarderType_Hydraulic" 0 "DrivelineRetarderType_ElectricMagnetic" ;
SIG_GROUP_ 2348814353 TSC1RECUVMCU_sg 1 : TSC1RECUVMCU_EnRSpdSpdLm TSC1RECUVMCU_EnOvrdCtrlM TSC1RECUVMCU_EnRTrqTrqLm TSC1RECUVMCU_EnRSpdCtrlC TSC1RECUVMCU_OvrdCtrlMPr;
SIG_GROUP_ 2348814339 TSC1RECUTECU_sg 1 : TSC1RECUTECU_EnRTrqTrqLm TSC1RECUTECU_EnOvrdCtrlM TSC1RECUTECU_OvrdCtrlMPr TSC1RECUTECU_EnRSpdCtrlC TSC1RECUTECU_EnRSpdSpdLm;
SIG_GROUP_ 2348814337 TSC1RECUEMSdap_sg 1 : TSC1RECUEMSdap_EnRSpdSpdLm TSC1RECUEMSdap_OvrdCtrlMPr TSC1RECUEMSdap_EnOvrdCtrlM TSC1RECUEMSdap_EnRSpdCtrlC TSC1RECUEMSdap_EnRTrqTrqLm;
SIG_GROUP_ 2348814336 TSC1RECUEMSccb_sg 1 : TSC1RECUEMSccb_EnRSpdSpdLm TSC1RECUEMSccb_EnRSpdCtrlC TSC1RECUEMSccb_EnOvrdCtrlM TSC1RECUEMSccb_OvrdCtrlMPr TSC1RECUEMSccb_EnRTrqTrqLm;
SIG_GROUP_ 2348814347 TSC1RECUABS_sg 1 : TSC1RECUABS_EnOvrdCtrlM TSC1RECUABS_EnRTrqTrqLm TSC1RECUABS_EnRSpdSpdLm TSC1RECUABS_OvrdCtrlMPr TSC1RECUABS_EnRSpdCtrlC;
SIG_GROUP_ 2348810257 TSC1EMSVMCUtr_sg 1 : TSC1EMSVMCUtr_EnOvrdCtrlM TSC1EMSVMCUtr_EnRSpdCtrlC TSC1EMSVMCUtr_OvrdCtrlMPr TSC1EMSVMCUtr_EnRSpdSpdLm TSC1EMSVMCUtr_EnRTrqTrqLm;
SIG_GROUP_ 2348810288 TSC1EMSVMCUes_sg 1 : TSC1EMSVMCUes_OvrdCtrlMPr TSC1EMSVMCUes_EnRTrqTrqLm TSC1EMSVMCUes_EnOvrdCtrlM TSC1EMSVMCUes_EnRSpdSpdLm TSC1EMSVMCUes_EnRSpdCtrlC;
SIG_GROUP_ 2348810243 TSC1EMSTECU_sg 1 : TSC1EMSTECU_EnRSpdSpdLm TSC1EMSTECU_EnOvrdCtrlM TSC1EMSTECU_OvrdCtrlMPr TSC1EMSTECU_EnRSpdCtrlC TSC1EMSTECU_EnRTrqTrqLm;
SIG_GROUP_ 2348810251 TSC1EMSABS_sg 1 : TSC1EMSABS_EnRTrqTrqLm TSC1EMSABS_EnRSpdCtrlC TSC1EMSABS_OvrdCtrlMPr TSC1EMSABS_EnOvrdCtrlM TSC1EMSABS_EnRSpdSpdLm;
SIG_GROUP_ 2348810413 TSC1EMSDACU_sg 1 : TSC1EMSDACU_OvrdCtrlMPr TSC1EMSDACU_EnRSpdSpdLm TSC1EMSDACU_EnRSpdCtrlC TSC1EMSDACU_EnRTrqTrqLm TSC1EMSDACU_EnOvrdCtrlM;
SIG_GROUP_ 2348814097 TSC1EMSrVMCU_sg 1 : TSC1EMSrVMCU_EnRSpdCtrlC TSC1EMSrVMCU_EnRTrqTrqLm TSC1EMSrVMCU_OvrdCtrlMPr TSC1EMSrVMCU_EnRSpdSpdLm TSC1EMSrVMCU_EnOvrdCtrlM;
SIG_GROUP_ 2348814083 TSC1EMSrTECU_sg 1 : TSC1EMSrTECU_OvrdCtrlMPr TSC1EMSrTECU_EnRSpdCtrlC TSC1EMSrTECU_EnOvrdCtrlM TSC1EMSrTECU_EnRTrqTrqLm TSC1EMSrTECU_EnRSpdSpdLm;
SIG_GROUP_ 2348814091 TSC1EMSrABS_sg 1 : TSC1EMSrABS_EnRTrqTrqLm TSC1EMSrABS_EnRSpdCtrlC TSC1EMSrABS_OvrdCtrlMPr TSC1EMSrABS_EnOvrdCtrlM TSC1EMSrABS_EnRSpdSpdLm;
